VERSION "created by canmatrix"

NS_ :

BS_:

BU_: IPD

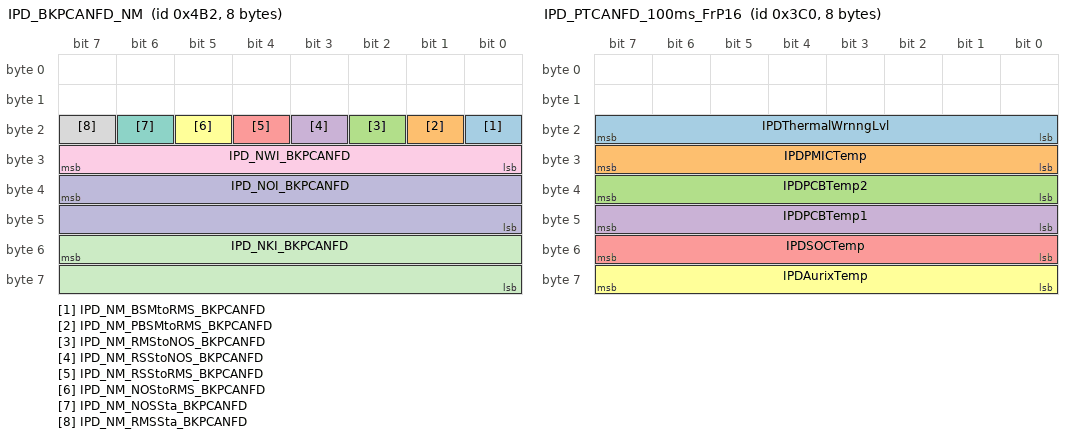
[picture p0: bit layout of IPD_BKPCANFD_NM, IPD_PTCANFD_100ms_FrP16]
BO_ 1202 IPD_BKPCANFD_NM: 8 IPD
 SG_ IPD_NM_BSMtoRMS_BKPCANFD : 16|1@0+ (1,0) [0|1] "null" Vector__XXX
 SG_ IPD_NM_PBSMtoRMS_BKPCANFD : 17|1@0+ (1,0) [0|1] "null" Vector__XXX
 SG_ IPD_NM_RMStoNOS_BKPCANFD : 18|1@0+ (1,0) [0|1] "null" Vector__XXX
 SG_ IPD_NM_RSStoNOS_BKPCANFD : 19|1@0+ (1,0) [0|1] "null" Vector__XXX
 SG_ IPD_NM_RSStoRMS_BKPCANFD : 20|1@0+ (1,0) [0|1] "null" Vector__XXX
 SG_ IPD_NM_NOStoRMS_BKPCANFD : 21|1@0+ (1,0) [0|1] "null" Vector__XXX
 SG_ IPD_NM_NOSSta_BKPCANFD : 22|1@0+ (1,0) [0|1] "null" Vector__XXX
 SG_ IPD_NM_RMSSta_BKPCANFD : 23|1@0+ (1,0) [0|1] "null" Vector__XXX
 SG_ IPD_NWI_BKPCANFD : 31|8@0+ (1,0) [0|255] "null" Vector__XXX
 SG_ IPD_NOI_BKPCANFD : 39|16@0+ (1,0) [0|65535] "null" Vector__XXX
 SG_ IPD_NKI_BKPCANFD : 55|16@0+ (1,0) [0|65535] "null" Vector__XXX

BO_ 705 IPD_CHCANFD_100ms_FrP130: 16 IPD
 SG_ RASysSts : 19|3@0+ (1,0) [0|7] "null" Vector__XXX
 SG_ HWPEMStsForEdr : 124|3@0+ (1,0) [0|7] "null" Vector__XXX
 SG_ HWPEMSts : 127|3@0+ (1,0) [0|7] "null" Vector__XXX

BO_ 982 IPD_PTCANFD_100ms_FrP03: 20 IPD
 SG_ ACCDetObjLongtRltvDist : 7|12@0+ (0.0625,0) [0.0000|255.9375] "null" Vector__XXX
 SG_ ACCDetObjSyncCtr : 11|4@0+ (1,0) [0|15] "null" Vector__XXX
 SG_ ACCDetObjLongtRltvSpd : 23|12@0+ (0.0625,-128) [-128.0000|127.9375] "null" Vector__XXX
 SG_ ACCDetObjRisk : 24|1@0+ (1,0) [0|1] "null" Vector__XXX
 SG_ ACCDetObjTyp : 27|3@0+ (1,0) [0|7] "null" Vector__XXX
 SG_ ACCDetObjLatRltvDist : 33|15@0+ (0.0078,-128) [-128.0000|127.5826] "null" Vector__XXX
 SG_ ACCDetObjExistPrblty : 39|6@0+ (0.015625,0) [0.000000|0.984375] "null" Vector__XXX
 SG_ ACCDetObjId : 50|6@0+ (1,0) [0|63] "null" Vector__XXX

BO_ 960 IPD_PTCANFD_100ms_FrP16: 8 IPD
 SG_ IPDThermalWrnngLvl : 23|8@0+ (1,0) [0|255] "null" Vector__XXX
 SG_ IPDPMICTemp : 31|8@0+ (1,-40) [-40|215] "degreeCelsius" Vector__XXX
 SG_ IPDPCBTemp2 : 39|8@0+ (1,-40) [-40|215] "degreeCelsius" Vector__XXX
 SG_ IPDPCBTemp1 : 47|8@0+ (1,-40) [-40|215] "degreeCelsius" Vector__XXX
 SG_ IPDSOCTemp : 55|8@0+ (1,-40) [-40|215] "degreeCelsius" Vector__XXX
 SG_ IPDAurixTemp : 63|8@0+ (1,-40) [-40|215] "degreeCelsius" Vector__XXX

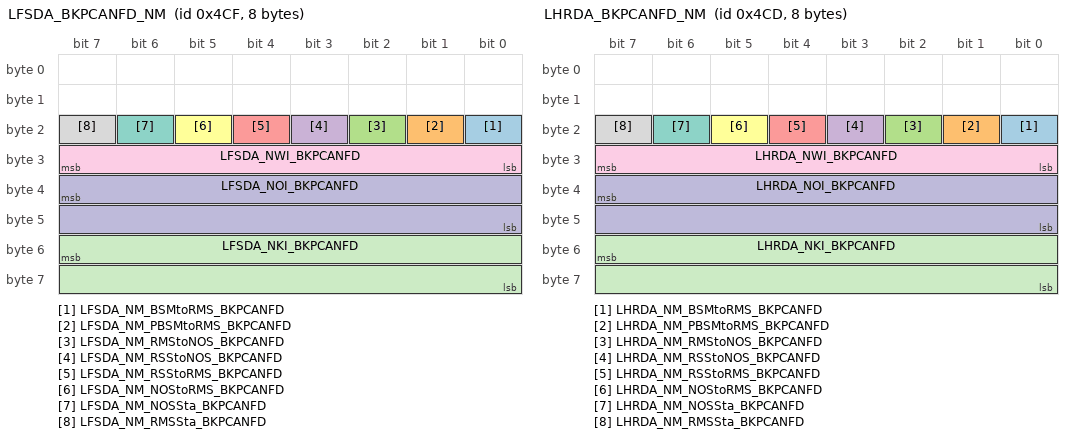
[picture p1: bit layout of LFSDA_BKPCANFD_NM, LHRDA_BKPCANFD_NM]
BO_ 1231 LFSDA_BKPCANFD_NM: 8 Vector__XXX
 SG_ LFSDA_NM_BSMtoRMS_BKPCANFD : 16|1@0+ (1,0) [0|1] "null" Vector__XXX
 SG_ LFSDA_NM_PBSMtoRMS_BKPCANFD : 17|1@0+ (1,0) [0|1] "null" Vector__XXX
 SG_ LFSDA_NM_RMStoNOS_BKPCANFD : 18|1@0+ (1,0) [0|1] "null" Vector__XXX
 SG_ LFSDA_NM_RSStoNOS_BKPCANFD : 19|1@0+ (1,0) [0|1] "null" Vector__XXX
 SG_ LFSDA_NM_RSStoRMS_BKPCANFD : 20|1@0+ (1,0) [0|1] "null" Vector__XXX
 SG_ LFSDA_NM_NOStoRMS_BKPCANFD : 21|1@0+ (1,0) [0|1] "null" Vector__XXX
 SG_ LFSDA_NM_NOSSta_BKPCANFD : 22|1@0+ (1,0) [0|1] "null" Vector__XXX
 SG_ LFSDA_NM_RMSSta_BKPCANFD : 23|1@0+ (1,0) [0|1] "null" Vector__XXX
 SG_ LFSDA_NWI_BKPCANFD : 31|8@0+ (1,0) [0|255] "null" Vector__XXX
 SG_ LFSDA_NOI_BKPCANFD : 39|16@0+ (1,0) [0|65535] "null" Vector__XXX
 SG_ LFSDA_NKI_BKPCANFD : 55|16@0+ (1,0) [0|65535] "null" Vector__XXX

BO_ 1229 LHRDA_BKPCANFD_NM: 8 Vector__XXX
 SG_ LHRDA_NM_BSMtoRMS_BKPCANFD : 16|1@0+ (1,0) [0|1] "null" Vector__XXX
 SG_ LHRDA_NM_PBSMtoRMS_BKPCANFD : 17|1@0+ (1,0) [0|1] "null" Vector__XXX
 SG_ LHRDA_NM_RMStoNOS_BKPCANFD : 18|1@0+ (1,0) [0|1] "null" Vector__XXX
 SG_ LHRDA_NM_RSStoNOS_BKPCANFD : 19|1@0+ (1,0) [0|1] "null" Vector__XXX
 SG_ LHRDA_NM_RSStoRMS_BKPCANFD : 20|1@0+ (1,0) [0|1] "null" Vector__XXX
 SG_ LHRDA_NM_NOStoRMS_BKPCANFD : 21|1@0+ (1,0) [0|1] "null" Vector__XXX
 SG_ LHRDA_NM_NOSSta_BKPCANFD : 22|1@0+ (1,0) [0|1] "null" Vector__XXX
 SG_ LHRDA_NM_RMSSta_BKPCANFD : 23|1@0+ (1,0) [0|1] "null" Vector__XXX
 SG_ LHRDA_NWI_BKPCANFD : 31|8@0+ (1,0) [0|255] "null" Vector__XXX
 SG_ LHRDA_NOI_BKPCANFD : 39|16@0+ (1,0) [0|65535] "null" Vector__XXX
 SG_ LHRDA_NKI_BKPCANFD : 55|16@0+ (1,0) [0|65535] "null" Vector__XXX

BO_ 995 LHZCU_BKBCANFD_100ms_FrP30: 16 Vector__XXX
 SG_ LHZCU_100ms_Group30_CRC : 7|8@0+ (1,0) [0|255] "null" IPD
 SG_ LHZCU_100ms_Group30_RC : 11|4@0+ (1,0) [0|15] "null" IPD
 SG_ LHZCU_100ms_Group30_Reserved12 : 12|1@0+ (1,0) [0|1] "null" IPD
 SG_ DircnIndLampSwStsMntry : 15|3@0+ (1,0) [0|7] "null" IPD
 SG_ LHZCU_100ms_Group30_Reserved23 : 23|8@0+ (1,0) [0|255] "null" IPD
 SG_ LHZCU_100ms_Group30_Reserved31 : 31|8@0+ (1,0) [0|255] "null" IPD
 SG_ FLSeatHorzPos : 39|8@0+ (1,0) [0|255] "%" IPD
 SG_ FLSeatVertPos : 47|8@0+ (1,0) [0|255] "%" IPD
 SG_ LHZCU_100ms_Group30_Reserved55 : 55|8@0+ (1,0) [0|255] "null" IPD
 SG_ LHZCU_100ms_Group30_Reserved63 : 63|8@0+ (1,0) [0|255] "null" IPD
 SG_ LHZCU_100ms_Group30_Reserved71 : 71|8@0+ (1,0) [0|255] "null" IPD
 SG_ LHZCU_100ms_Group30_Reserved79 : 79|8@0+ (1,0) [0|255] "null" IPD
 SG_ LHZCU_100ms_Group30_Reserved87 : 87|8@0+ (1,0) [0|255] "null" IPD
 SG_ LHZCU_100ms_Group30_Reserved95 : 95|8@0+ (1,0) [0|255] "null" IPD
 SG_ LHZCU_100ms_Group30_Reserved103 : 103|8@0+ (1,0) [0|255] "null" IPD
 SG_ LHZCU_100ms_Group30_Reserved111 : 111|8@0+ (1,0) [0|255] "null" IPD
 SG_ LHZCU_100ms_Group30_Reserved119 : 119|8@0+ (1,0) [0|255] "null" IPD
 SG_ LHZCU_100ms_Group30_Reserved127 : 127|8@0+ (1,0) [0|255] "null" IPD

BO_ 181 LHZCU_BKBCANFD_10ms_FrP32: 12 Vector__XXX
 SG_ LHZCU_10ms_Group32_CRC : 7|8@0+ (1,0) [0|255] "null" IPD
 SG_ LHZCU_10ms_Group32_RC : 11|4@0+ (1,0) [0|15] "null" IPD
 SG_ LHZCU_10ms_Group32_Reserved1 : 15|4@0+ (1,0) [0|15] "null" IPD
 SG_ BrkLghtSwReq : 16|1@0+ (1,0) [0|1] "null" IPD
 SG_ SideLghtOnReq : 18|2@0+ (1,0) [0|3] "null" IPD
 SG_ MainBeamLghtSwReq : 20|2@0+ (1,0) [0|3] "null" IPD
 SG_ LHZCU_10ms_Group32_Reserved2 : 23|3@0+ (1,0) [0|7] "null" IPD
 SG_ DrvrReqGearShftPos : 27|4@0+ (1,0) [0|15] "null" IPD
 SG_ LHZCU_10ms_Group32_Reserved3 : 28|1@0+ (1,0) [0|1] "null" IPD
 SG_ RrFogLightOnReq : 29|1@0+ (1,0) [0|1] "null" IPD
 SG_ RDayTimeRunningLghtCtrl : 30|1@0+ (1,0) [0|1] "null" IPD
 SG_ LDayTimeRunningLghtCtrl : 31|1@0+ (1,0) [0|1] "null" IPD
 SG_ EleccTrRngReq : 35|4@0+ (1,0) [0|15] "null" IPD
 SG_ DrvrReqGearShftPosInvs : 39|4@0+ (1,0) [0|15] "null" IPD
 SG_ DircnLghtOnReq_LHZCU : 41|2@0+ (1,0) [0|3] "null" IPD
 SG_ SCUDrvnIntrvnPos : 45|4@0+ (1,0) [0|15] "null" IPD
 SG_ LHZCU_10ms_Group32_Reserved4 : 46|1@0+ (1,0) [0|1] "null" IPD
 SG_ SCUShftLvrPosIncnstntFlag : 47|1@0+ (1,0) [0|1] "null" IPD
 SG_ SCUShftLvrPosTrgt : 51|4@0+ (1,0) [0|15] "null" IPD
 SG_ SCUExtdShifterActrPos : 55|4@0+ (1,0) [0|15] "null" IPD
 SG_ SCUTapUpDwnSwStaInvsn : 57|2@0+ (1,0) [0|3] "null" IPD
 SG_ SCUTapUpDwnSwSta : 59|2@0+ (1,0) [0|3] "null" IPD
 SG_ SCUParkActrSts : 61|2@0+ (1,0) [0|3] "null" IPD
 SG_ SCUActrMvmntSts : 63|2@0+ (1,0) [0|3] "null" IPD
 SG_ SmrtKey4LoctnResp : 67|4@0+ (1,0) [0|15] "null" IPD
 SG_ SmrtKeyLoctnProc : 71|4@0+ (1,0) [0|15] "null" IPD
 SG_ LHZCU_10ms_Group32_Reserved5 : 74|3@0+ (1,0) [0|7] "null" IPD
 SG_ LHZCUWKSTS : 75|1@0+ (1,0) [0|1] "null" IPD
 SG_ SmrtKeyLoctnFlrRsn : 79|4@0+ (1,0) [0|15] "null" IPD
 SG_ LHZCU_10ms_Group32_Reserved6 : 87|8@0+ (1,0) [0|255] "null" IPD
 SG_ LHZCU_10ms_Group32_Reserved7 : 95|8@0+ (1,0) [0|255] "null" IPD

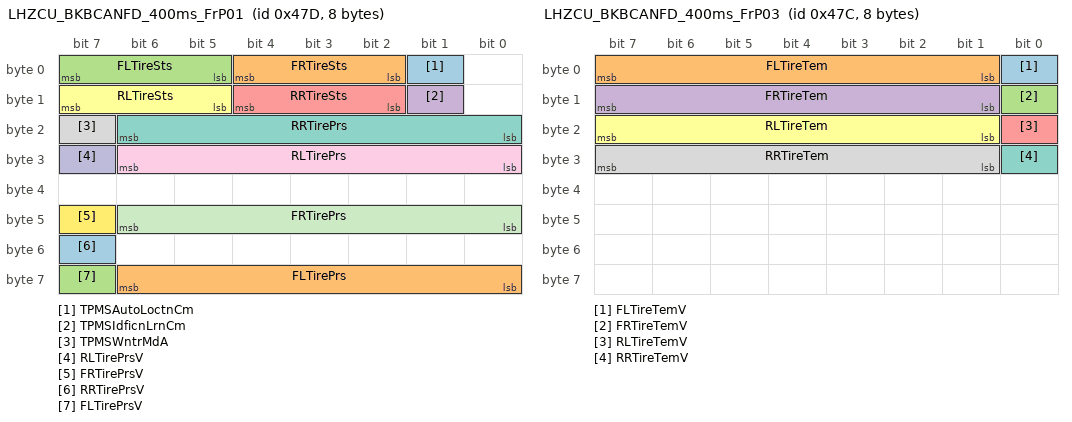
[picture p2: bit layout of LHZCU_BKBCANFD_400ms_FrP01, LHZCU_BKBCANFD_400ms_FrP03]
BO_ 1149 LHZCU_BKBCANFD_400ms_FrP01: 8 Vector__XXX
 SG_ TPMSAutoLoctnCm : 1|1@0+ (1,0) [0|1] "null" Vector__XXX
 SG_ FRTireSts : 4|3@0+ (1,0) [0|7] "null" IPD
 SG_ FLTireSts : 7|3@0+ (1,0) [0|7] "null" IPD
 SG_ TPMSIdficnLrnCm : 9|1@0+ (1,0) [0|1] "null" Vector__XXX
 SG_ RRTireSts : 12|3@0+ (1,0) [0|7] "null" IPD
 SG_ RLTireSts : 15|3@0+ (1,0) [0|7] "null" IPD
 SG_ RRTirePrs : 22|7@0+ (4,0) [0|508] "kPa" IPD
 SG_ TPMSWntrMdA : 23|1@0+ (1,0) [0|1] "null" IPD
 SG_ RLTirePrs : 30|7@0+ (4,0) [0|508] "kPa" IPD
 SG_ RLTirePrsV : 31|1@0+ (1,0) [0|1] "null" IPD
 SG_ FRTirePrs : 46|7@0+ (4,0) [0|508] "kPa" IPD
 SG_ FRTirePrsV : 47|1@0+ (1,0) [0|1] "null" IPD
 SG_ RRTirePrsV : 55|1@0+ (1,0) [0|1] "null" IPD
 SG_ FLTirePrs : 62|7@0+ (4,0) [0|508] "kPa" IPD
 SG_ FLTirePrsV : 63|1@0+ (1,0) [0|1] "null" IPD

BO_ 1148 LHZCU_BKBCANFD_400ms_FrP03: 8 Vector__XXX
 SG_ FLTireTemV : 0|1@0+ (1,0) [0|1] "null" IPD
 SG_ FLTireTem : 7|7@0+ (2,-60) [-60|194] "degreeCelsius" IPD
 SG_ FRTireTemV : 8|1@0+ (1,0) [0|1] "null" IPD
 SG_ FRTireTem : 15|7@0+ (2,-60) [-60|194] "degreeCelsius" IPD
 SG_ RLTireTemV : 16|1@0+ (1,0) [0|1] "null" IPD
 SG_ RLTireTem : 23|7@0+ (2,-60) [-60|194] "degreeCelsius" IPD
 SG_ RRTireTemV : 24|1@0+ (1,0) [0|1] "null" IPD
 SG_ RRTireTem : 31|7@0+ (2,-60) [-60|194] "degreeCelsius" IPD

BO_ 638 LHZCU_BKBCANFD_50ms_FrP24: 20 Vector__XXX
 SG_ LHZCU_50ms_Group24_CRC : 7|8@0+ (1,0) [0|255] "null" IPD
 SG_ LHZCU_50ms_Group24_RC : 11|4@0+ (1,0) [0|15] "null" IPD
 SG_ VehHzrdMdSts : 15|4@0+ (1,0) [0|15] "null" IPD
 SG_ LHZCU_50ms_Group24_Reserved23 : 23|8@0+ (1,0) [0|255] "null" IPD
 SG_ VehIlluminateCtrlCmd : 24|1@0+ (1,0) [0|1] "null" IPD
 SG_ LHZCU_50ms_Group24_Reserved31 : 31|7@0+ (1,0) [0|127] "null" IPD
 SG_ BrkLghtSta : 32|1@0+ (1,0) [0|1] "null" IPD
 SG_ LHZCU_50ms_Group24_Reserved39 : 39|7@0+ (1,0) [0|127] "null" IPD
 SG_ BrkLghtFltSta : 40|1@0+ (1,0) [0|1] "null" IPD
 SG_ LHZCU_50ms_Group24_Reserved47 : 47|7@0+ (1,0) [0|127] "null" IPD
 SG_ LHZCU_50ms_Group24_Reserved49 : 49|3@0+ (1,0) [0|7] "null" IPD
 SG_ DircnLghtSts : 52|3@0+ (1,0) [0|7] "null" IPD
 SG_ DircnLghtMdSts : 53|1@0+ (1,0) [0|1] "null" IPD
 SG_ LHZCU_50ms_Group24_Reserved55 : 55|2@0+ (1,0) [0|3] "null" IPD
 SG_ LHZCU_50ms_Group24_Reserved60 : 60|5@0+ (1,0) [0|31] "null" IPD
 SG_ RRSideLghtCtrl : 61|1@0+ (1,0) [0|1] "null" IPD
 SG_ RLSideLghtCtrl : 62|1@0+ (1,0) [0|1] "null" IPD
 SG_ LHZCU_50ms_Group24_Reserved71 : 71|8@0+ (1,0) [0|255] "null" IPD
 SG_ VehSideLghtSts : 73|2@0+ (1,0) [0|3] "null" IPD
 SG_ LHZCU_50ms_Group24_Reserved79 : 79|6@0+ (1,0) [0|63] "null" IPD
 SG_ LHZCU_50ms_Group24_Reserved81 : 81|2@0+ (1,0) [0|3] "null" IPD
 SG_ DircnLghtSwReq : 84|3@0+ (1,0) [0|7] "null" IPD
 SG_ LHZCU_50ms_Group24_Reserved87 : 87|3@0+ (1,0) [0|7] "null" IPD
 SG_ LHZCU_50ms_Group24_Reserved95 : 95|8@0+ (1,0) [0|255] "null" IPD
 SG_ LHZCU_50ms_Group24_Reserved103 : 103|8@0+ (1,0) [0|255] "null" IPD
 SG_ DircnLghtFltsts : 105|2@0+ (1,0) [0|3] "null" IPD
 SG_ LHZCU_50ms_Group24_Reserved111 : 111|6@0+ (1,0) [0|63] "null" IPD
 SG_ HUDLkngAmbtLghtLvlByLux : 119|14@0+ (10,0) [0|163830] "lux" IPD
 SG_ LHZCU_50ms_Group24_Reserved121 : 121|2@0+ (1,0) [0|3] "null" IPD
 SG_ LHZCU_50ms_Group24_Reserved135 : 135|8@0+ (1,0) [0|255] "null" IPD
 SG_ LHZCU_50ms_Group24_Reserved143 : 143|8@0+ (1,0) [0|255] "null" IPD
 SG_ LHZCU_50ms_Group24_Reserved151 : 151|8@0+ (1,0) [0|255] "null" IPD
 SG_ LHZCU_50ms_Group24_Reserved159 : 159|8@0+ (1,0) [0|255] "null" IPD

BO_ 745 LHZCU_BKBCANFD_50ms_FrP34: 16 Vector__XXX
 SG_ AutoMainBeamLghtOn : 12|1@0+ (1,0) [0|1] "null" IPD
 SG_ MainBeamLghtOn : 13|1@0+ (1,0) [0|1] "null" IPD
 SG_ LRevsLghtSts : 14|1@0+ (1,0) [0|1] "null" Vector__XXX
 SG_ LBrkLghtSts : 15|1@0+ (1,0) [0|1] "null" Vector__XXX
 SG_ ROtsdMirVertSwActReq : 17|2@0+ (1,0) [0|3] "null" Vector__XXX
 SG_ ROtsdMirHoztSwActReq : 19|2@0+ (1,0) [0|3] "null" Vector__XXX
 SG_ RLDoorLckSts : 21|2@0+ (1,0) [0|3] "null" Vector__XXX
 SG_ ZoneRLSideLghtSts : 27|2@0+ (1,0) [0|3] "null" Vector__XXX
 SG_ ZoneFLSideLghtSts : 29|2@0+ (1,0) [0|3] "null" Vector__XXX
 SG_ AllWndAndSrfLazyClsReq : 45|1@0+ (1,0) [0|1] "null" Vector__XXX
 SG_ RrSrvcPosReq : 46|1@0+ (1,0) [0|1] "null" Vector__XXX
 SG_ RrWiperFnEnb : 47|1@0+ (1,0) [0|1] "null" Vector__XXX
 SG_ DDSPSelRSwReq : 50|2@0+ (1,0) [0|3] "null" Vector__XXX
 SG_ DDSPSelLSwReq : 52|2@0+ (1,0) [0|3] "null" Vector__XXX
 SG_ TrdtnSmrtKyLckSwSts : 65|2@0+ (1,0) [0|3] "null" IPD
 SG_ TrdtnSmrtKyUnlckSwSts : 67|2@0+ (1,0) [0|3] "null" IPD
 SG_ RLSuperLckSts : 69|2@0+ (1,0) [0|3] "null" Vector__XXX
 SG_ FLSuperLckSts : 71|2@0+ (1,0) [0|3] "null" Vector__XXX
 SG_ DDSPSelDwnSwReq : 73|2@0+ (1,0) [0|3] "null" Vector__XXX
 SG_ DDSPSelUpSwReq : 75|2@0+ (1,0) [0|3] "null" Vector__XXX
 SG_ DDSPROtsdMirSeldSwA : 77|2@0+ (1,0) [0|3] "null" Vector__XXX
 SG_ DDSPLOtsdMirSeldSwA : 79|2@0+ (1,0) [0|3] "null" Vector__XXX
 SG_ DDSPOtsdMirFoldSwReq : 87|2@0+ (1,0) [0|3] "null" Vector__XXX

BO_ 640 LHZCU_BKBCANFD_50ms_FrP58: 24 Vector__XXX
 SG_ TrdtnKeyBtnSts : 15|4@0+ (1,0) [0|15] "null" IPD
 SG_ SmrtKey1BtnSts : 23|8@0+ (1,0) [0|255] "null" Vector__XXX
 SG_ SmrtKey2BtnSts : 31|8@0+ (1,0) [0|255] "null" Vector__XXX
 SG_ SmrtKey3BtnSts : 39|8@0+ (1,0) [0|255] "null" Vector__XXX
 SG_ SmrtKey4BtnSts : 47|8@0+ (1,0) [0|255] "null" Vector__XXX
 SG_ SmrtKey2LoctnResp : 51|4@0+ (1,0) [0|15] "null" Vector__XXX
 SG_ SmrtKey1LoctnResp : 55|4@0+ (1,0) [0|15] "null" Vector__XXX
 SG_ LHandAntFltSts : 59|4@0+ (1,0) [0|15] "null" Vector__XXX
 SG_ SmrtKey3LoctnResp : 63|4@0+ (1,0) [0|15] "null" Vector__XXX
 SG_ FrtBmpAntFltSts : 67|4@0+ (1,0) [0|15] "null" Vector__XXX
 SG_ RHandAntFltSts : 71|4@0+ (1,0) [0|15] "null" Vector__XXX
 SG_ CabinFrtAntFltSts : 75|4@0+ (1,0) [0|15] "null" Vector__XXX
 SG_ RrBmpAntFltSts : 79|4@0+ (1,0) [0|15] "null" Vector__XXX
 SG_ CabinRrAntFltSts : 83|4@0+ (1,0) [0|15] "null" Vector__XXX
 SG_ CabinImmoAntFltSts : 87|4@0+ (1,0) [0|15] "null" Vector__XXX
 SG_ KickSnsrDetnSts : 91|2@0+ (1,0) [0|3] "null" Vector__XXX
 SG_ TrdtnSmrtKyLdspcSwSts : 93|2@0+ (1,0) [0|3] "null" IPD
 SG_ TrdtnSmrtKyFindCarSwSts : 95|2@0+ (1,0) [0|3] "null" IPD

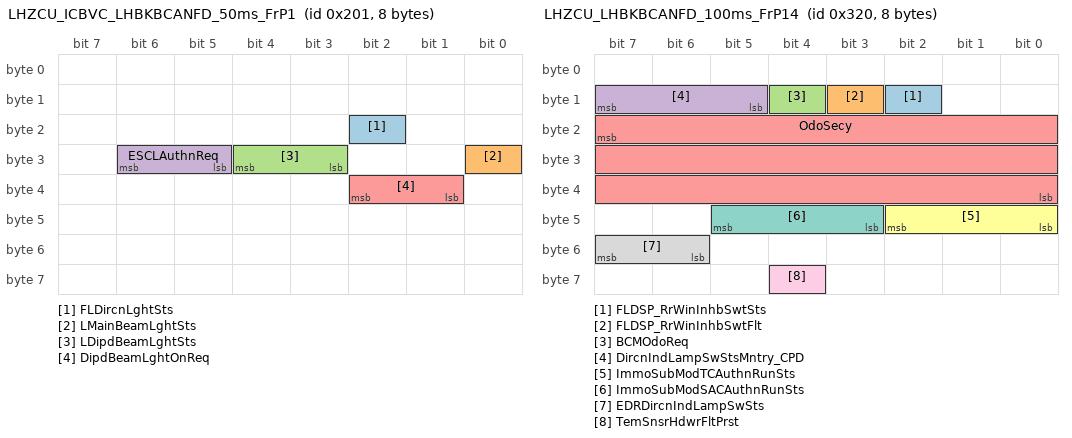
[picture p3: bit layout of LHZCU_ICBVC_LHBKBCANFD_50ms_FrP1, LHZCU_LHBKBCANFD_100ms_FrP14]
BO_ 513 LHZCU_ICBVC_LHBKBCANFD_50ms_FrP1: 8 Vector__XXX
 SG_ FLDircnLghtSts : 18|1@0+ (1,0) [0|1] "null" IPD
 SG_ LMainBeamLghtSts : 24|1@0+ (1,0) [0|1] "null" Vector__XXX
 SG_ LDipdBeamLghtSts : 28|2@0+ (1,0) [0|3] "null" Vector__XXX
 SG_ ESCLAuthnReq : 30|2@0+ (1,0) [0|3] "null" Vector__XXX
 SG_ DipdBeamLghtOnReq : 34|2@0+ (1,0) [0|3] "null" Vector__XXX

BO_ 800 LHZCU_LHBKBCANFD_100ms_FrP14: 8 Vector__XXX
 SG_ FLDSP_RrWinInhbSwtSts : 10|1@0+ (1,0) [0|1] "null" Vector__XXX
 SG_ FLDSP_RrWinInhbSwtFlt : 11|1@0+ (1,0) [0|1] "null" Vector__XXX
 SG_ BCMOdoReq : 12|1@0+ (1,0) [0|1] "null" Vector__XXX
 SG_ DircnIndLampSwStsMntry_CPD : 15|3@0+ (1,0) [0|7] "null" Vector__XXX
 SG_ OdoSecy : 23|24@0+ (1,0) [0|16777215] "km" Vector__XXX
 SG_ ImmoSubModTCAuthnRunSts : 42|3@0+ (1,0) [0|7] "null" Vector__XXX
 SG_ ImmoSubModSACAuthnRunSts : 45|3@0+ (1,0) [0|7] "null" Vector__XXX
 SG_ EDRDircnIndLampSwSts : 55|2@0+ (1,0) [0|3] "null" Vector__XXX
 SG_ TemSnsrHdwrFltPrst : 60|1@0+ (1,0) [0|1] "null" IPD

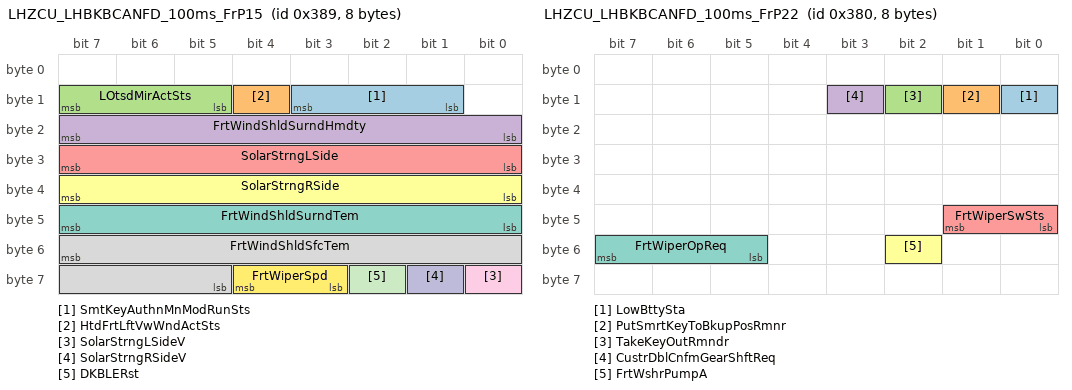
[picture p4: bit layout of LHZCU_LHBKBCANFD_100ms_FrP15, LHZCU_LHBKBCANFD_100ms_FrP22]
BO_ 905 LHZCU_LHBKBCANFD_100ms_FrP15: 8 Vector__XXX
 SG_ SmtKeyAuthnMnModRunSts : 11|3@0+ (1,0) [0|7] "null" Vector__XXX
 SG_ HtdFrtLftVwWndActSts : 12|1@0+ (1,0) [0|1] "null" Vector__XXX
 SG_ LOtsdMirActSts : 15|3@0+ (1,0) [0|7] "null" Vector__XXX
 SG_ FrtWindShldSurndHmdty : 23|8@0+ (0.5,0) [0|127.5] "%" IPD
 SG_ SolarStrngLSide : 31|8@0+ (5,0) [0|1275] "null" Vector__XXX
 SG_ SolarStrngRSide : 39|8@0+ (5,0) [0|1275] "null" Vector__XXX
 SG_ FrtWindShldSurndTem : 47|8@0+ (0.5,-40) [-40|87.5] "degC" IPD
 SG_ FrtWindShldSfcTem : 55|11@0+ (0.1,-40) [-40|164.7] "degC" IPD
 SG_ SolarStrngLSideV : 56|1@0+ (1,0) [0|1] "null" Vector__XXX
 SG_ SolarStrngRSideV : 57|1@0+ (1,0) [0|1] "null" Vector__XXX
 SG_ DKBLERst : 58|1@0+ (1,0) [0|1] "null" Vector__XXX
 SG_ FrtWiperSpd : 60|2@0+ (1,0) [0|3] "null" IPD

BO_ 783 LHZCU_LHBKBCANFD_100ms_FrP16: 64 Vector__XXX
 SG_ LHZCUeFs12Crnt : 7|9@0+ (0.1,0) [0|51.1] "A" Vector__XXX
 SG_ LHZCUeSw40Crnt : 14|9@0+ (0.1,0) [0|51.1] "A" Vector__XXX
 SG_ WlcmReq : 19|2@0+ (1,0) [0|3] "null" Vector__XXX
 SG_ FllwMeReq : 21|2@0+ (1,0) [0|3] "null" Vector__XXX
 SG_ LHZCUInptVol : 47|8@0+ (0.1,0) [0|25.5] "V" Vector__XXX
 SG_ LHZCUeFs8Crnt : 55|9@0+ (0.1,0) [0|51.1] "A" Vector__XXX
 SG_ LHZCUeSw24Crnt : 56|9@0+ (0.1,0) [0|51.1] "A" Vector__XXX
 SG_ LHZCUeSw17Crnt : 76|9@0+ (0.1,0) [0|51.1] "A" Vector__XXX
 SG_ LHZCUeSw16Crnt : 83|9@0+ (0.1,0) [0|51.1] "A" Vector__XXX
 SG_ LHZCUeSw15Crnt : 90|9@0+ (0.1,0) [0|51.1] "A" Vector__XXX
 SG_ LHZCUeSw14Crnt : 97|9@0+ (0.1,0) [0|51.1] "A" Vector__XXX
 SG_ LHZCUeSw13Crnt : 104|9@0+ (0.1,0) [0|51.1] "A" Vector__XXX
 SG_ LHZCUeSw12Crnt : 127|9@0+ (0.1,0) [0|51.1] "A" Vector__XXX
 SG_ LHZCUeSw26Crnt : 128|9@0+ (0.1,0) [0|51.1] "A" Vector__XXX
 SG_ LHZCUeFs6Crnt : 148|9@0+ (0.1,0) [0|51.1] "A" Vector__XXX
 SG_ LHZCUeSw32Crnt : 155|9@0+ (0.1,0) [0|51.1] "A" Vector__XXX
 SG_ LHZCUeFs4Crnt : 162|9@0+ (0.1,0) [0|51.1] "A" Vector__XXX
 SG_ LHZCUeSw27Crnt : 168|9@0+ (0.1,0) [0|51.1] "A" Vector__XXX
 SG_ LHZCUBkupInptVol : 191|8@0+ (0.1,0) [0|25.5] "V" Vector__XXX
 SG_ LHZCUeSw1Crnt : 199|9@0+ (0.1,0) [0|51.1] "A" Vector__XXX
 SG_ LHZCUeSw20Crnt : 206|9@0+ (0.1,0) [0|51.1] "A" Vector__XXX
 SG_ LHZCUeSw3Crnt : 213|9@0+ (0.1,0) [0|51.1] "A" Vector__XXX
 SG_ LHZCUeSw29Crnt : 216|9@0+ (0.1,0) [0|51.1] "A" Vector__XXX
 SG_ LHZCUeSw36Crnt : 239|9@0+ (0.1,0) [0|51.1] "A" Vector__XXX
 SG_ LHZCUeFs13Crnt : 240|9@0+ (0.1,0) [0|51.1] "A" Vector__XXX
 SG_ LHZCUeSw30Crnt : 263|9@0+ (0.1,0) [0|51.1] "A" Vector__XXX
 SG_ LHZCUeSw31Crnt : 264|9@0+ (0.1,0) [0|51.1] "A" Vector__XXX
 SG_ FrwlLghtReq_LHZCU : 267|1@0+ (1,0) [0|1] "null" Vector__XXX
 SG_ LHZCUeSw43Crnt : 287|9@0+ (0.1,0) [0|51.1] "A" Vector__XXX
 SG_ LHZCUAddtnInptVol : 303|8@0+ (0.1,0) [0|25.5] "V" Vector__XXX
 SG_ LHZCUeSw44Crnt : 311|9@0+ (0.1,0) [0|51.1] "A" Vector__XXX
 SG_ LHZCUeSw45Crnt : 318|9@0+ (0.1,0) [0|51.1] "A" Vector__XXX
 SG_ FLSeatZeroSt : 321|2@0+ (1,0) [0|3] "null" Vector__XXX
 SG_ LHZCUeSw46Crnt : 335|9@0+ (0.1,0) [0|51.1] "A" Vector__XXX
 SG_ LHZCUeSw47Crnt : 336|9@0+ (0.1,0) [0|51.1] "A" Vector__XXX
 SG_ WlcmLghtReq_LHZCU : 338|1@0+ (1,0) [0|1] "null" Vector__XXX
 SG_ FLDoorOpenSts : 341|2@0+ (1,0) [0|3] "null" IPD
 SG_ HUDLghtSnsrHdwrFltPrst : 342|1@0+ (1,0) [0|1] "null" Vector__XXX
 SG_ FLSeatRclnMotActn : 362|2@0+ (1,0) [0|3] "null" Vector__XXX
 SG_ FLSeatVertMotActn : 364|2@0+ (1,0) [0|3] "null" Vector__XXX
 SG_ FLSeatHoztMotActn : 366|2@0+ (1,0) [0|3] "null" Vector__XXX
 SG_ HUDFwdLkngAmbtLghtLvl : 383|14@0+ (10,0) [0|163830] "LUX" Vector__XXX
 SG_ FollowMeHomeReq_LHZCU : 384|1@0+ (1,0) [0|1] "null" Vector__XXX
 SG_ BklghtReq : 385|1@0+ (1,0) [0|1] "null" Vector__XXX
 SG_ HUDRLSAmbtLghtLvl : 399|12@0+ (10,0) [0|40950] "LUX" Vector__XXX
 SG_ LHZCUeFs15Crnt : 400|9@0+ (0.1,0) [0|51.1] "A" Vector__XXX
 SG_ HmdtySnsrHdwrFltPrst : 401|1@0+ (1,0) [0|1] "null" IPD
 SG_ FrtPsngDoorOpenSts_LHZCU : 403|2@0+ (1,0) [0|3] "null" IPD
 SG_ LHZCUeFs17Crnt : 423|9@0+ (0.1,0) [0|51.1] "A" Vector__XXX

BO_ 896 LHZCU_LHBKBCANFD_100ms_FrP22: 8 Vector__XXX
 SG_ LowBttySta : 8|1@0+ (1,0) [0|1] "null" Vector__XXX
 SG_ PutSmrtKeyToBkupPosRmnr : 9|1@0+ (1,0) [0|1] "null" Vector__XXX
 SG_ TakeKeyOutRmndr : 10|1@0+ (1,0) [0|1] "null" Vector__XXX
 SG_ CustrDblCnfmGearShftReq : 11|1@0+ (1,0) [0|1] "null" Vector__XXX
 SG_ FrtWiperSwSts : 41|2@0+ (1,0) [0|3] "null" IPD
 SG_ FrtWshrPumpA : 50|1@0+ (1,0) [0|1] "null" Vector__XXX
 SG_ FrtWiperOpReq : 55|3@0+ (1,0) [0|7] "null" Vector__XXX

BO_ 157 LHZCU_LHBKBCANFD_10ms_FrP01: 8 Vector__XXX
 SG_ LHZCU_10ms_Group01_CRC : 7|8@0+ (1,0) [0|255] "null" IPD
 SG_ LHZCU_10ms_Group01_RC : 11|4@0+ (1,0) [0|15] "null" IPD
 SG_ SCUFltLvlWarn : 13|2@0+ (1,0) [0|3] "null" IPD
 SG_ SCUDrvMd : 15|2@0+ (1,0) [0|3] "null" IPD
 SG_ SCUExtdShiftrFlr : 19|4@0+ (1,0) [0|15] "null" IPD
 SG_ SCUShiftrOpngRmndr : 23|4@0+ (1,0) [0|15] "null" IPD
 SG_ KeyAuthResp : 24|1@0+ (1,0) [0|1] "null" IPD
 SG_ SCUParkLckReq : 26|2@0+ (1,0) [0|3] "null" IPD
 SG_ SCUParkLckReqV : 27|1@0+ (1,0) [0|1] "null" IPD
 SG_ LHZCU_10ms_Group01_Reserved1 : 30|3@0+ (1,0) [0|7] "null" IPD
 SG_ DigKeyAuthReq : 31|1@0+ (1,0) [0|1] "null" IPD
 SG_ SCUShiftrLvrRawPosn : 34|3@0+ (1,0) [0|7] "null" IPD
 SG_ SCUParkLckReqVEPMCU : 35|1@0+ (1,0) [0|1] "null" IPD
 SG_ LHZCU_10ms_Group01_Reserved2 : 37|2@0+ (1,0) [0|3] "null" IPD
 SG_ SCUParkLckReqEPMCU : 39|2@0+ (1,0) [0|3] "null" IPD
 SG_ SCUShiftrPosnInvsn : 43|4@0+ (1,0) [0|15] "null" IPD
 SG_ SCUShiftrLvrPosn : 47|4@0+ (1,0) [0|15] "null" IPD
 SG_ DrvrReqParkBtn : 49|2@0+ (1,0) [0|3] "null" IPD
 SG_ SCUShiftrLvrPosnLtchActv : 50|1@0+ (1,0) [0|1] "null" IPD
 SG_ SecuKeyVldSts : 51|1@0+ (1,0) [0|1] "null" IPD
 SG_ SCUDrvrIntrvnActv : 52|1@0+ (1,0) [0|1] "null" IPD
 SG_ SCUAPAUnderCtrlActv : 55|3@0+ (1,0) [0|7] "null" IPD
 SG_ DigKeyPEValidReq : 63|8@0+ (1,0) [0|255] "null" IPD

BO_ 299 LHZCU_LHBKBCANFD_20ms_FrP03: 8 Vector__XXX
 SG_ LHZCU_20ms_Group03_CRC : 7|8@0+ (1,0) [0|255] "null" IPD
 SG_ LHZCU_20ms_Group03_RC : 11|4@0+ (1,0) [0|15] "null" IPD
 SG_ LHZCU_20ms_Group03_Reserved1 : 15|4@0+ (1,0) [0|15] "null" IPD
 SG_ LHZCU_20ms_Group03_Reserved2 : 23|8@0+ (1,0) [0|255] "null" IPD
 SG_ LHZCU_20ms_Group03_Reserved3 : 31|8@0+ (1,0) [0|255] "null" IPD
 SG_ LHZCU_20ms_Group03_Reserved4 : 39|8@0+ (1,0) [0|255] "null" IPD
 SG_ LHZCU_20ms_Group03_Reserved6 : 41|4@0+ (1,0) [0|15] "null" IPD
 SG_ DippedBeamActStatus : 42|1@0+ (1,0) [0|1] "null" IPD
 SG_ LHZCU_20ms_Group03_Reserved5 : 47|5@0+ (1,0) [0|31] "null" IPD
 SG_ RevsLghtCtrl : 48|1@0+ (1,0) [0|1] "null" IPD
 SG_ PriySSBA : 49|1@0+ (1,0) [0|1] "null" IPD
 SG_ PriySSBAV : 50|1@0+ (1,0) [0|1] "null" IPD
 SG_ SecySSBA : 51|1@0+ (1,0) [0|1] "null" IPD
 SG_ SecySSBAV : 52|1@0+ (1,0) [0|1] "null" IPD
 SG_ SSBTrigd : 53|1@0+ (1,0) [0|1] "null" IPD
 SG_ RMainBeamLghtCtrl : 56|1@0+ (1,0) [0|1] "null" IPD
 SG_ LMainBeamLghtCtrl : 57|1@0+ (1,0) [0|1] "null" IPD
 SG_ RRDircnLghtCtrl : 58|1@0+ (1,0) [0|1] "null" IPD
 SG_ RLDircnLghtCtrl : 59|1@0+ (1,0) [0|1] "null" IPD
 SG_ FRDircnLghtCtrl : 60|1@0+ (1,0) [0|1] "null" IPD
 SG_ FLDircnLghtCtrl : 61|1@0+ (1,0) [0|1] "null" IPD
 SG_ BrkLghtCtrl : 62|1@0+ (1,0) [0|1] "null" IPD
 SG_ HzrdLghtSwReq : 63|1@0+ (1,0) [0|1] "null" IPD

BA_DEF_ BO_ "FrameTriggeringName" STRING;
BA_DEF_ BO_ "GenMsgCycleTime" INT 0 65535;
BA_DEF_ BO_ "GenMsgDelayTime" INT 0 65535;
BA_DEF_ BO_ "GenMsgSendType" ENUM  "cyclicX","spontanX","cyclicIfActiveX","spontanWithDelay","cyclicAndSpontanX","cyclicAndSpontanWithDelay","spontanWithRepitition","cyclicIfActiveAndSpontanWD","cyclicIfActiveFast","cyclicWithRepeatOnDemand","none";
BA_DEF_ BO_ "GenMsgStartValue" STRING;
BA_DEF_ BO_ "PduName" STRING;
BA_DEF_ BO_ "SystemMessageLongSymbol" STRING;
BA_DEF_ BO_ "VFrameFormat" ENUM  "StandardCAN","ExtendedCAN","reserved","reserved","reserved","reserved","reserved","reserved","reserved","reserved","reserved","reserved","reserved","reserved","StandardCAN_FD","ExtendedCAN_FD";
BA_DEF_ SG_ "CompuMethodName" STRING;
BA_DEF_ SG_ "GenSigStartValue" FLOAT 0 100000000000;
BA_DEF_ SG_ "ISignalName" STRING;
BA_DEF_ SG_ "LongName" STRING;
BA_DEF_ SG_ "SysSignalName" STRING;
BA_DEF_ SG_ "SystemSignalLongSymbol" STRING;
BA_ "FrameTriggeringName" BO_ 1202 "IPD_BKPCANFD_NM";
BA_ "GenMsgSendType" BO_ 1202 1;
BA_ "GenMsgStartValue" BO_ 1202 "0000000000000000";
BA_ "PduName" BO_ 1202 "NmPDU_BKPCANFD_IPD";
BA_ "VFrameFormat" BO_ 1202 14;
BA_ "FrameTriggeringName" BO_ 705 "IPD_CHCANFD_100ms_FrP130";
BA_ "GenMsgCycleTime" BO_ 705 100;
BA_ "GenMsgSendType" BO_ 705 0;
BA_ "GenMsgStartValue" BO_ 705 "00000000000000000000000000000000";
BA_ "PduName" BO_ 705 "IPD_100ms_PDU130";
BA_ "VFrameFormat" BO_ 705 14;
BA_ "FrameTriggeringName" BO_ 982 "IPD_PTCANFD_100ms_FrP03";
BA_ "GenMsgCycleTime" BO_ 982 100;
BA_ "GenMsgSendType" BO_ 982 0;
BA_ "GenMsgStartValue" BO_ 982 "0000000000000000000000000000000000000000";
BA_ "PduName" BO_ 982 "IPD_100ms_PDU03";
BA_ "VFrameFormat" BO_ 982 14;
BA_ "FrameTriggeringName" BO_ 960 "IPD_PTCANFD_100ms_FrP16";
BA_ "GenMsgCycleTime" BO_ 960 100;
BA_ "GenMsgSendType" BO_ 960 0;
BA_ "GenMsgStartValue" BO_ 960 "000000ffffffffff";
BA_ "PduName" BO_ 960 "IPD_100ms_PDU16";
BA_ "VFrameFormat" BO_ 960 14;
BA_ "FrameTriggeringName" BO_ 1231 "LFSDA_BKPCANFD_NM";
BA_ "GenMsgSendType" BO_ 1231 1;
BA_ "GenMsgStartValue" BO_ 1231 "0000000000000000";
BA_ "PduName" BO_ 1231 "NmPDU_BKPCANFD_LFSDA";
BA_ "VFrameFormat" BO_ 1231 14;
BA_ "FrameTriggeringName" BO_ 1229 "LHRDA_BKPCANFD_NM";
BA_ "GenMsgSendType" BO_ 1229 1;
BA_ "GenMsgStartValue" BO_ 1229 "0000000000000000";
BA_ "PduName" BO_ 1229 "NmPDU_BKPCANFD_LHRDA";
BA_ "VFrameFormat" BO_ 1229 14;
BA_ "FrameTriggeringName" BO_ 995 "LHZCU_BKBCANFD_100ms_FrP30";
BA_ "GenMsgCycleTime" BO_ 995 100;
BA_ "GenMsgSendType" BO_ 995 0;
BA_ "GenMsgStartValue" BO_ 995 "0010ffffffffffffffffffffffffffff";
BA_ "PduName" BO_ 995 "LHZCU_100ms_PDU30";
BA_ "VFrameFormat" BO_ 995 14;
BA_ "FrameTriggeringName" BO_ 181 "LHZCU_BKBCANFD_10ms_FrP32";
BA_ "GenMsgCycleTime" BO_ 181 10;
BA_ "GenMsgSendType" BO_ 181 0;
BA_ "GenMsgStartValue" BO_ 181 "00f0e018704000030007ffff";
BA_ "PduName" BO_ 181 "LHZCU_10ms_PDU32";
BA_ "VFrameFormat" BO_ 181 14;
BA_ "FrameTriggeringName" BO_ 1149 "LHZCU_BKBCANFD_400ms_FrP01";
BA_ "GenMsgCycleTime" BO_ 1149 400;
BA_ "GenMsgSendType" BO_ 1149 0;
BA_ "GenMsgStartValue" BO_ 1149 "0202373700370037";
BA_ "PduName" BO_ 1149 "LHZCU_400ms_PDU01";
BA_ "VFrameFormat" BO_ 1149 14;
BA_ "FrameTriggeringName" BO_ 1148 "LHZCU_BKBCANFD_400ms_FrP03";
BA_ "GenMsgCycleTime" BO_ 1148 400;
BA_ "GenMsgSendType" BO_ 1148 0;
BA_ "GenMsgStartValue" BO_ 1148 "5a5a5a5a00000000";
BA_ "PduName" BO_ 1148 "LHZCU_400ms_PDU03";
BA_ "VFrameFormat" BO_ 1148 14;
BA_ "FrameTriggeringName" BO_ 638 "LHZCU_BKBCANFD_50ms_FrP24";
BA_ "GenMsgCycleTime" BO_ 638 50;
BA_ "GenMsgSendType" BO_ 638 0;
BA_ "GenMsgStartValue" BO_ 638 "0000fffefefec39ffffce3fffffc0003ffffffff";
BA_ "PduName" BO_ 638 "LHZCU_50ms_PDU24";
BA_ "VFrameFormat" BO_ 638 14;
BA_ "FrameTriggeringName" BO_ 745 "LHZCU_BKBCANFD_50ms_FrP34";
BA_ "GenMsgCycleTime" BO_ 745 50;
BA_ "GenMsgSendType" BO_ 745 0;
BA_ "GenMsgStartValue" BO_ 745 "00000000000000000000000000000000";
BA_ "PduName" BO_ 745 "LHZCU_50ms_PDU34";
BA_ "VFrameFormat" BO_ 745 14;
BA_ "FrameTriggeringName" BO_ 640 "LHZCU_BKBCANFD_50ms_FrP58";
BA_ "GenMsgCycleTime" BO_ 640 50;
BA_ "GenMsgSendType" BO_ 640 0;
BA_ "GenMsgStartValue" BO_ 640 "000000000000000000000000000000000000000000000000";
BA_ "PduName" BO_ 640 "LHZCU_50ms_PDU58";
BA_ "VFrameFormat" BO_ 640 14;
BA_ "FrameTriggeringName" BO_ 513 "LHZCU_ICBVC_LHBKBCANFD_50ms_FrP14";
BA_ "GenMsgCycleTime" BO_ 513 50;
BA_ "GenMsgSendType" BO_ 513 0;
BA_ "GenMsgStartValue" BO_ 513 "0000000000000000";
BA_ "PduName" BO_ 513 "LHZCU_ICBVC_50ms_PDU14";
BA_ "SystemMessageLongSymbol" BO_ 513 "LHZCU_ICBVC_LHBKBCANFD_50ms_FrP14";
BA_ "VFrameFormat" BO_ 513 14;
BA_ "FrameTriggeringName" BO_ 800 "LHZCU_LHBKBCANFD_100ms_FrP14";
BA_ "GenMsgCycleTime" BO_ 800 100;
BA_ "GenMsgSendType" BO_ 800 0;
BA_ "GenMsgStartValue" BO_ 800 "0000000000000000";
BA_ "PduName" BO_ 800 "LHZCU_100ms_PDU14";
BA_ "VFrameFormat" BO_ 800 14;
BA_ "FrameTriggeringName" BO_ 905 "LHZCU_LHBKBCANFD_100ms_FrP15";
BA_ "GenMsgCycleTime" BO_ 905 100;
BA_ "GenMsgSendType" BO_ 905 0;
BA_ "GenMsgStartValue" BO_ 905 "0000000000000000";
BA_ "PduName" BO_ 905 "LHZCU_100ms_PDU15";
BA_ "VFrameFormat" BO_ 905 14;
BA_ "FrameTriggeringName" BO_ 783 "LHZCU_LHBKBCANFD_100ms_FrP16";
BA_ "GenMsgCycleTime" BO_ 783 100;
BA_ "GenMsgSendType" BO_ 783 0;
BA_ "GenMsgStartValue" BO_ 783 "00000000000000000000000000000000000000000000000000000000000000000000000000000000000000000000000000000000000000000000000000000000";
BA_ "PduName" BO_ 783 "LHZCU_100ms_PDU16";
BA_ "VFrameFormat" BO_ 783 14;
BA_ "FrameTriggeringName" BO_ 896 "LHZCU_LHBKBCANFD_100ms_FrP22";
BA_ "GenMsgCycleTime" BO_ 896 100;
BA_ "GenMsgSendType" BO_ 896 0;
BA_ "GenMsgStartValue" BO_ 896 "0000000000000000";
BA_ "PduName" BO_ 896 "LHZCU_100ms_PDU22";
BA_ "VFrameFormat" BO_ 896 14;
BA_ "FrameTriggeringName" BO_ 157 "LHZCU_LHBKBCANFD_10ms_FrP01";
BA_ "GenMsgCycleTime" BO_ 157 10;
BA_ "GenMsgSendType" BO_ 157 0;
BA_ "GenMsgStartValue" BO_ 157 "000000783a0f0800";
BA_ "PduName" BO_ 157 "LHZCU_10ms_PDU01";
BA_ "VFrameFormat" BO_ 157 14;
BA_ "FrameTriggeringName" BO_ 299 "LHZCU_LHBKBCANFD_20ms_FrP03";
BA_ "GenMsgCycleTime" BO_ 299 20;
BA_ "GenMsgSendType" BO_ 299 0;
BA_ "GenMsgStartValue" BO_ 299 "00f0fffffffbc000";
BA_ "PduName" BO_ 299 "LHZCU_20ms_PDU03";
BA_ "VFrameFormat" BO_ 299 14;
BA_ "CompuMethodName" SG_ 1202 IPD_NM_BSMtoRMS_BKPCANFD "IPD_NM_BSMtoRMS_BKPCANFD";
BA_ "ISignalName" SG_ 1202 IPD_NM_BSMtoRMS_BKPCANFD "IIPD_NM_BSMtoRMS_BKPCANFD";
BA_ "LongName" SG_ 1202 IPD_NM_BSMtoRMS_BKPCANFD "IPD_NM_BSMtoRMS_BKPCANFD";
BA_ "SysSignalName" SG_ 1202 IPD_NM_BSMtoRMS_BKPCANFD "IPD_NM_BSMtoRMS_BKPCANFD";
BA_ "CompuMethodName" SG_ 1202 IPD_NM_PBSMtoRMS_BKPCANFD "IPD_NM_PBSMtoRMS_BKPCANFD";
BA_ "ISignalName" SG_ 1202 IPD_NM_PBSMtoRMS_BKPCANFD "IIPD_NM_PBSMtoRMS_BKPCANFD";
BA_ "LongName" SG_ 1202 IPD_NM_PBSMtoRMS_BKPCANFD "IPD_NM_PBSMtoRMS_BKPCANFD";
BA_ "SysSignalName" SG_ 1202 IPD_NM_PBSMtoRMS_BKPCANFD "IPD_NM_PBSMtoRMS_BKPCANFD";
BA_ "CompuMethodName" SG_ 1202 IPD_NM_RMStoNOS_BKPCANFD "IPD_NM_RMStoNOS_BKPCANFD";
BA_ "ISignalName" SG_ 1202 IPD_NM_RMStoNOS_BKPCANFD "IIPD_NM_RMStoNOS_BKPCANFD";
BA_ "LongName" SG_ 1202 IPD_NM_RMStoNOS_BKPCANFD "IPD_NM_RMStoNOS_BKPCANFD";
BA_ "SysSignalName" SG_ 1202 IPD_NM_RMStoNOS_BKPCANFD "IPD_NM_RMStoNOS_BKPCANFD";
BA_ "CompuMethodName" SG_ 1202 IPD_NM_RSStoNOS_BKPCANFD "IPD_NM_RSStoNOS_BKPCANFD";
BA_ "ISignalName" SG_ 1202 IPD_NM_RSStoNOS_BKPCANFD "IIPD_NM_RSStoNOS_BKPCANFD";
BA_ "LongName" SG_ 1202 IPD_NM_RSStoNOS_BKPCANFD "IPD_NM_RSStoNOS_BKPCANFD";
BA_ "SysSignalName" SG_ 1202 IPD_NM_RSStoNOS_BKPCANFD "IPD_NM_RSStoNOS_BKPCANFD";
BA_ "CompuMethodName" SG_ 1202 IPD_NM_RSStoRMS_BKPCANFD "IPD_NM_RSStoRMS_BKPCANFD";
BA_ "ISignalName" SG_ 1202 IPD_NM_RSStoRMS_BKPCANFD "IIPD_NM_RSStoRMS_BKPCANFD";
BA_ "LongName" SG_ 1202 IPD_NM_RSStoRMS_BKPCANFD "IPD_NM_RSStoRMS_BKPCANFD";
BA_ "SysSignalName" SG_ 1202 IPD_NM_RSStoRMS_BKPCANFD "IPD_NM_RSStoRMS_BKPCANFD";
BA_ "CompuMethodName" SG_ 1202 IPD_NM_NOStoRMS_BKPCANFD "IPD_NM_NOStoRMS_BKPCANFD";
BA_ "ISignalName" SG_ 1202 IPD_NM_NOStoRMS_BKPCANFD "IIPD_NM_NOStoRMS_BKPCANFD";
BA_ "LongName" SG_ 1202 IPD_NM_NOStoRMS_BKPCANFD "IPD_NM_NOStoRMS_BKPCANFD";
BA_ "SysSignalName" SG_ 1202 IPD_NM_NOStoRMS_BKPCANFD "IPD_NM_NOStoRMS_BKPCANFD";
BA_ "CompuMethodName" SG_ 1202 IPD_NM_NOSSta_BKPCANFD "IPD_NM_NOSSta_BKPCANFD";
BA_ "ISignalName" SG_ 1202 IPD_NM_NOSSta_BKPCANFD "IIPD_NM_NOSSta_BKPCANFD";
BA_ "LongName" SG_ 1202 IPD_NM_NOSSta_BKPCANFD "IPD_NM_NOSSta_BKPCANFD";
BA_ "SysSignalName" SG_ 1202 IPD_NM_NOSSta_BKPCANFD "IPD_NM_NOSSta_BKPCANFD";
BA_ "CompuMethodName" SG_ 1202 IPD_NM_RMSSta_BKPCANFD "IPD_NM_RMSSta_BKPCANFD";
BA_ "ISignalName" SG_ 1202 IPD_NM_RMSSta_BKPCANFD "IIPD_NM_RMSSta_BKPCANFD";
BA_ "LongName" SG_ 1202 IPD_NM_RMSSta_BKPCANFD "IPD_NM_RMSSta_BKPCANFD";
BA_ "SysSignalName" SG_ 1202 IPD_NM_RMSSta_BKPCANFD "IPD_NM_RMSSta_BKPCANFD";
BA_ "CompuMethodName" SG_ 1202 IPD_NWI_BKPCANFD "IPD_NWI_BKPCANFD";
BA_ "ISignalName" SG_ 1202 IPD_NWI_BKPCANFD "IIPD_NWI_BKPCANFD";
BA_ "LongName" SG_ 1202 IPD_NWI_BKPCANFD "IPD BKPCANFD Network_Wakeup_Indication";
BA_ "SysSignalName" SG_ 1202 IPD_NWI_BKPCANFD "IPD_NWI_BKPCANFD";
BA_ "CompuMethodName" SG_ 1202 IPD_NOI_BKPCANFD "IPD_NOI_BKPCANFD";
BA_ "ISignalName" SG_ 1202 IPD_NOI_BKPCANFD "IIPD_NOI_BKPCANFD";
BA_ "LongName" SG_ 1202 IPD_NOI_BKPCANFD "IPD BKPCANFD Network Operation Indication";
BA_ "SysSignalName" SG_ 1202 IPD_NOI_BKPCANFD "IPD_NOI_BKPCANFD";
BA_ "CompuMethodName" SG_ 1202 IPD_NKI_BKPCANFD "IPD_NKI_BKPCANFD";
BA_ "ISignalName" SG_ 1202 IPD_NKI_BKPCANFD "IIPD_NKI_BKPCANFD";
BA_ "LongName" SG_ 1202 IPD_NKI_BKPCANFD "IPD BKPCANFD Network Keep Indication";
BA_ "SysSignalName" SG_ 1202 IPD_NKI_BKPCANFD "IPD_NKI_BKPCANFD";
BA_ "CompuMethodName" SG_ 705 RASysSts "RASysSts";
BA_ "ISignalName" SG_ 705 RASysSts "IRASysSts";
BA_ "LongName" SG_ 705 RASysSts "Reverse Assist Systerm Status";
BA_ "SysSignalName" SG_ 705 RASysSts "RASysSts";
BA_ "CompuMethodName" SG_ 705 HWPEMStsForEdr "HWPEMStsForEdr";
BA_ "ISignalName" SG_ 705 HWPEMStsForEdr "IHWPEMStsForEdr";
BA_ "LongName" SG_ 705 HWPEMStsForEdr "L3 Function Emergency mode Status For Edr";
BA_ "SysSignalName" SG_ 705 HWPEMStsForEdr "HWPEMStsForEdr";
BA_ "CompuMethodName" SG_ 705 HWPEMSts "HWPEMSts";
BA_ "ISignalName" SG_ 705 HWPEMSts "IHWPEMSts";
BA_ "LongName" SG_ 705 HWPEMSts "HWP Function Emergency mode Status";
BA_ "SysSignalName" SG_ 705 HWPEMSts "HWPEMSts";
BA_ "CompuMethodName" SG_ 982 ACCDetObjLongtRltvDist "ACCDetObjLongtRltvDist";
BA_ "ISignalName" SG_ 982 ACCDetObjLongtRltvDist "IACCDetObjLongtRltvDist";
BA_ "LongName" SG_ 982 ACCDetObjLongtRltvDist "Adaptive_Cruise_Control_Detected_Object_Longitudinal_Relative_Distance";
BA_ "SysSignalName" SG_ 982 ACCDetObjLongtRltvDist "ACCDetObjLongtRltvDist";
BA_ "CompuMethodName" SG_ 982 ACCDetObjSyncCtr "ACCDetObjSyncCtr";
BA_ "ISignalName" SG_ 982 ACCDetObjSyncCtr "IACCDetObjSyncCtr";
BA_ "LongName" SG_ 982 ACCDetObjSyncCtr "Adaptive_Cruise_Control_Detected_Object_Synchronize_Counter";
BA_ "SysSignalName" SG_ 982 ACCDetObjSyncCtr "ACCDetObjSyncCtr";
BA_ "CompuMethodName" SG_ 982 ACCDetObjLongtRltvSpd "ACCDetObjLongtRltvSpd";
BA_ "ISignalName" SG_ 982 ACCDetObjLongtRltvSpd "IACCDetObjLongtRltvSpd";
BA_ "LongName" SG_ 982 ACCDetObjLongtRltvSpd "Adaptive_Cruise_Control_Detected_Object_Longitudinal_Relative_Speed";
BA_ "SysSignalName" SG_ 982 ACCDetObjLongtRltvSpd "ACCDetObjLongtRltvSpd";
BA_ "CompuMethodName" SG_ 982 ACCDetObjRisk "ACCDetObjRisk";
BA_ "ISignalName" SG_ 982 ACCDetObjRisk "IACCDetObjRisk";
BA_ "LongName" SG_ 982 ACCDetObjRisk "Adaptive_Cruise_Control_Detected_Object_0_Risk";
BA_ "SysSignalName" SG_ 982 ACCDetObjRisk "ACCDetObjRisk";
BA_ "CompuMethodName" SG_ 982 ACCDetObjTyp "ACCDetObjTyp";
BA_ "ISignalName" SG_ 982 ACCDetObjTyp "IACCDetObjTyp";
BA_ "LongName" SG_ 982 ACCDetObjTyp "Adaptive_Cruise_Control_Detected_Object_0_Type";
BA_ "SysSignalName" SG_ 982 ACCDetObjTyp "ACCDetObjTyp";
BA_ "CompuMethodName" SG_ 982 ACCDetObjLatRltvDist "ACCDetObjLatRltvDist";
BA_ "ISignalName" SG_ 982 ACCDetObjLatRltvDist "IACCDetObjLatRltvDist";
BA_ "LongName" SG_ 982 ACCDetObjLatRltvDist "Adaptive_Cruise_Control_Detected_Object_Lateral_Relative_Distance";
BA_ "SysSignalName" SG_ 982 ACCDetObjLatRltvDist "ACCDetObjLatRltvDist";
BA_ "CompuMethodName" SG_ 982 ACCDetObjExistPrblty "ACCDetObjExistPrblty";
BA_ "ISignalName" SG_ 982 ACCDetObjExistPrblty "IACCDetObjExistPrblty";
BA_ "LongName" SG_ 982 ACCDetObjExistPrblty "Adaptive_Cruise_Control_Detected_Object_Exist_Probability";
BA_ "SysSignalName" SG_ 982 ACCDetObjExistPrblty "ACCDetObjExistPrblty";
BA_ "CompuMethodName" SG_ 982 ACCDetObjId "ACCDetObjId";
BA_ "ISignalName" SG_ 982 ACCDetObjId "IACCDetObjId";
BA_ "LongName" SG_ 982 ACCDetObjId "Adaptive_Cruise_Control_Detected_Object_Identifier";
BA_ "SysSignalName" SG_ 982 ACCDetObjId "ACCDetObjId";
BA_ "CompuMethodName" SG_ 960 IPDThermalWrnngLvl "IPDThermalWrnngLvl";
BA_ "ISignalName" SG_ 960 IPDThermalWrnngLvl "IIPDThermalWrnngLvl";
BA_ "LongName" SG_ 960 IPDThermalWrnngLvl "IPD Thermal Warning Level";
BA_ "SysSignalName" SG_ 960 IPDThermalWrnngLvl "IPDThermalWrnngLvl";
BA_ "CompuMethodName" SG_ 960 IPDPMICTemp "IPDPMICTemp";
BA_ "GenSigStartValue" SG_ 960 IPDPMICTemp 255;
BA_ "ISignalName" SG_ 960 IPDPMICTemp "IIPDPMICTemp";
BA_ "LongName" SG_ 960 IPDPMICTemp "IPD PMIC Temperature";
BA_ "SysSignalName" SG_ 960 IPDPMICTemp "IPDPMICTemp";
BA_ "CompuMethodName" SG_ 960 IPDPCBTemp2 "IPDPCBTemp2";
BA_ "GenSigStartValue" SG_ 960 IPDPCBTemp2 255;
BA_ "ISignalName" SG_ 960 IPDPCBTemp2 "IIPDPCBTemp2";
BA_ "LongName" SG_ 960 IPDPCBTemp2 "IPD PCB Temperature 2";
BA_ "SysSignalName" SG_ 960 IPDPCBTemp2 "IPDPCBTemp2";
BA_ "CompuMethodName" SG_ 960 IPDPCBTemp1 "IPDPCBTemp1";
BA_ "GenSigStartValue" SG_ 960 IPDPCBTemp1 255;
BA_ "ISignalName" SG_ 960 IPDPCBTemp1 "IIPDPCBTemp1";
BA_ "LongName" SG_ 960 IPDPCBTemp1 "IPD PCB Temperature 1";
BA_ "SysSignalName" SG_ 960 IPDPCBTemp1 "IPDPCBTemp1";
BA_ "CompuMethodName" SG_ 960 IPDSOCTemp "IPDSOCTemp";
BA_ "GenSigStartValue" SG_ 960 IPDSOCTemp 255;
BA_ "ISignalName" SG_ 960 IPDSOCTemp "IIPDSOCTemp";
BA_ "LongName" SG_ 960 IPDSOCTemp "IPD Orin Temperature";
BA_ "SysSignalName" SG_ 960 IPDSOCTemp "IPDSOCTemp";
BA_ "CompuMethodName" SG_ 960 IPDAurixTemp "IPDAurixTemp";
BA_ "GenSigStartValue" SG_ 960 IPDAurixTemp 255;
BA_ "ISignalName" SG_ 960 IPDAurixTemp "IIPDAurixTemp";
BA_ "LongName" SG_ 960 IPDAurixTemp "IPD Aurix Temperature";
BA_ "SysSignalName" SG_ 960 IPDAurixTemp "IPDAurixTemp";
BA_ "CompuMethodName" SG_ 1231 LFSDA_NM_BSMtoRMS_BKPCANFD "LFSDA_NM_BSMtoRMS_BKPCANFD";
BA_ "ISignalName" SG_ 1231 LFSDA_NM_BSMtoRMS_BKPCANFD "ILFSDA_NM_BSMtoRMS_BKPCANFD";
BA_ "LongName" SG_ 1231 LFSDA_NM_BSMtoRMS_BKPCANFD "LFSDA_NM_BSMtoRMS_BKPCANFD";
BA_ "SysSignalName" SG_ 1231 LFSDA_NM_BSMtoRMS_BKPCANFD "LFSDA_NM_BSMtoRMS_BKPCANFD";
BA_ "CompuMethodName" SG_ 1231 LFSDA_NM_PBSMtoRMS_BKPCANFD "LFSDA_NM_PBSMtoRMS_BKPCANFD";
BA_ "ISignalName" SG_ 1231 LFSDA_NM_PBSMtoRMS_BKPCANFD "ILFSDA_NM_PBSMtoRMS_BKPCANFD";
BA_ "LongName" SG_ 1231 LFSDA_NM_PBSMtoRMS_BKPCANFD "LFSDA_NM_PBSMtoRMS_BKPCANFD";
BA_ "SysSignalName" SG_ 1231 LFSDA_NM_PBSMtoRMS_BKPCANFD "LFSDA_NM_PBSMtoRMS_BKPCANFD";
BA_ "CompuMethodName" SG_ 1231 LFSDA_NM_RMStoNOS_BKPCANFD "LFSDA_NM_RMStoNOS_BKPCANFD";
BA_ "ISignalName" SG_ 1231 LFSDA_NM_RMStoNOS_BKPCANFD "ILFSDA_NM_RMStoNOS_BKPCANFD";
BA_ "LongName" SG_ 1231 LFSDA_NM_RMStoNOS_BKPCANFD "LFSDA_NM_RMStoNOS_BKPCANFD";
BA_ "SysSignalName" SG_ 1231 LFSDA_NM_RMStoNOS_BKPCANFD "LFSDA_NM_RMStoNOS_BKPCANFD";
BA_ "CompuMethodName" SG_ 1231 LFSDA_NM_RSStoNOS_BKPCANFD "LFSDA_NM_RSStoNOS_BKPCANFD";
BA_ "ISignalName" SG_ 1231 LFSDA_NM_RSStoNOS_BKPCANFD "ILFSDA_NM_RSStoNOS_BKPCANFD";
BA_ "LongName" SG_ 1231 LFSDA_NM_RSStoNOS_BKPCANFD "LFSDA_NM_RSStoNOS_BKPCANFD";
BA_ "SysSignalName" SG_ 1231 LFSDA_NM_RSStoNOS_BKPCANFD "LFSDA_NM_RSStoNOS_BKPCANFD";
BA_ "CompuMethodName" SG_ 1231 LFSDA_NM_RSStoRMS_BKPCANFD "LFSDA_NM_RSStoRMS_BKPCANFD";
BA_ "ISignalName" SG_ 1231 LFSDA_NM_RSStoRMS_BKPCANFD "ILFSDA_NM_RSStoRMS_BKPCANFD";
BA_ "LongName" SG_ 1231 LFSDA_NM_RSStoRMS_BKPCANFD "LFSDA_NM_RSStoRMS_BKPCANFD";
BA_ "SysSignalName" SG_ 1231 LFSDA_NM_RSStoRMS_BKPCANFD "LFSDA_NM_RSStoRMS_BKPCANFD";
BA_ "CompuMethodName" SG_ 1231 LFSDA_NM_NOStoRMS_BKPCANFD "LFSDA_NM_NOStoRMS_BKPCANFD";
BA_ "ISignalName" SG_ 1231 LFSDA_NM_NOStoRMS_BKPCANFD "ILFSDA_NM_NOStoRMS_BKPCANFD";
BA_ "LongName" SG_ 1231 LFSDA_NM_NOStoRMS_BKPCANFD "LFSDA_NM_NOStoRMS_BKPCANFD";
BA_ "SysSignalName" SG_ 1231 LFSDA_NM_NOStoRMS_BKPCANFD "LFSDA_NM_NOStoRMS_BKPCANFD";
BA_ "CompuMethodName" SG_ 1231 LFSDA_NM_NOSSta_BKPCANFD "LFSDA_NM_NOSSta_BKPCANFD";
BA_ "ISignalName" SG_ 1231 LFSDA_NM_NOSSta_BKPCANFD "ILFSDA_NM_NOSSta_BKPCANFD";
BA_ "LongName" SG_ 1231 LFSDA_NM_NOSSta_BKPCANFD "LFSDA_NM_NOSSta_BKPCANFD";
BA_ "SysSignalName" SG_ 1231 LFSDA_NM_NOSSta_BKPCANFD "LFSDA_NM_NOSSta_BKPCANFD";
BA_ "CompuMethodName" SG_ 1231 LFSDA_NM_RMSSta_BKPCANFD "LFSDA_NM_RMSSta_BKPCANFD";
BA_ "ISignalName" SG_ 1231 LFSDA_NM_RMSSta_BKPCANFD "ILFSDA_NM_RMSSta_BKPCANFD";
BA_ "LongName" SG_ 1231 LFSDA_NM_RMSSta_BKPCANFD "LFSDA_NM_RMSSta_BKPCANFD";
BA_ "SysSignalName" SG_ 1231 LFSDA_NM_RMSSta_BKPCANFD "LFSDA_NM_RMSSta_BKPCANFD";
BA_ "CompuMethodName" SG_ 1231 LFSDA_NWI_BKPCANFD "LFSDA_NWI_BKPCANFD";
BA_ "ISignalName" SG_ 1231 LFSDA_NWI_BKPCANFD "ILFSDA_NWI_BKPCANFD";
BA_ "LongName" SG_ 1231 LFSDA_NWI_BKPCANFD "LFSDA_BKPCANFD Network Wakeup Indication";
BA_ "SysSignalName" SG_ 1231 LFSDA_NWI_BKPCANFD "LFSDA_NWI_BKPCANFD";
BA_ "CompuMethodName" SG_ 1231 LFSDA_NOI_BKPCANFD "LFSDA_NOI_BKPCANFD";
BA_ "ISignalName" SG_ 1231 LFSDA_NOI_BKPCANFD "ILFSDA_NOI_BKPCANFD";
BA_ "LongName" SG_ 1231 LFSDA_NOI_BKPCANFD "LFSDA BKPCANFD Network Operation Indication";
BA_ "SysSignalName" SG_ 1231 LFSDA_NOI_BKPCANFD "LFSDA_NOI_BKPCANFD";
BA_ "CompuMethodName" SG_ 1231 LFSDA_NKI_BKPCANFD "LFSDA_NKI_BKPCANFD";
BA_ "ISignalName" SG_ 1231 LFSDA_NKI_BKPCANFD "ILFSDA_NKI_BKPCANFD";
BA_ "LongName" SG_ 1231 LFSDA_NKI_BKPCANFD "LFSDA BKPCANFD Network Keep Indication";
BA_ "SysSignalName" SG_ 1231 LFSDA_NKI_BKPCANFD "LFSDA_NKI_BKPCANFD";
BA_ "CompuMethodName" SG_ 1229 LHRDA_NM_BSMtoRMS_BKPCANFD "LHRDA_NM_BSMtoRMS_BKPCANFD";
BA_ "ISignalName" SG_ 1229 LHRDA_NM_BSMtoRMS_BKPCANFD "ILHRDA_NM_BSMtoRMS_BKPCANFD";
BA_ "LongName" SG_ 1229 LHRDA_NM_BSMtoRMS_BKPCANFD "LHRDA_NM_BSMtoRMS_BKPCANFD";
BA_ "SysSignalName" SG_ 1229 LHRDA_NM_BSMtoRMS_BKPCANFD "LHRDA_NM_BSMtoRMS_BKPCANFD";
BA_ "CompuMethodName" SG_ 1229 LHRDA_NM_PBSMtoRMS_BKPCANFD "LHRDA_NM_PBSMtoRMS_BKPCANFD";
BA_ "ISignalName" SG_ 1229 LHRDA_NM_PBSMtoRMS_BKPCANFD "ILHRDA_NM_PBSMtoRMS_BKPCANFD";
BA_ "LongName" SG_ 1229 LHRDA_NM_PBSMtoRMS_BKPCANFD "LHRDA_NM_PBSMtoRMS_BKPCANFD";
BA_ "SysSignalName" SG_ 1229 LHRDA_NM_PBSMtoRMS_BKPCANFD "LHRDA_NM_PBSMtoRMS_BKPCANFD";
BA_ "CompuMethodName" SG_ 1229 LHRDA_NM_RMStoNOS_BKPCANFD "LHRDA_NM_RMStoNOS_BKPCANFD";
BA_ "ISignalName" SG_ 1229 LHRDA_NM_RMStoNOS_BKPCANFD "ILHRDA_NM_RMStoNOS_BKPCANFD";
BA_ "LongName" SG_ 1229 LHRDA_NM_RMStoNOS_BKPCANFD "LHRDA_NM_RMStoNOS_BKPCANFD";
BA_ "SysSignalName" SG_ 1229 LHRDA_NM_RMStoNOS_BKPCANFD "LHRDA_NM_RMStoNOS_BKPCANFD";
BA_ "CompuMethodName" SG_ 1229 LHRDA_NM_RSStoNOS_BKPCANFD "LHRDA_NM_RSStoNOS_BKPCANFD";
BA_ "ISignalName" SG_ 1229 LHRDA_NM_RSStoNOS_BKPCANFD "ILHRDA_NM_RSStoNOS_BKPCANFD";
BA_ "LongName" SG_ 1229 LHRDA_NM_RSStoNOS_BKPCANFD "LHRDA_NM_RSStoNOS_BKPCANFD";
BA_ "SysSignalName" SG_ 1229 LHRDA_NM_RSStoNOS_BKPCANFD "LHRDA_NM_RSStoNOS_BKPCANFD";
BA_ "CompuMethodName" SG_ 1229 LHRDA_NM_RSStoRMS_BKPCANFD "LHRDA_NM_RSStoRMS_BKPCANFD";
BA_ "ISignalName" SG_ 1229 LHRDA_NM_RSStoRMS_BKPCANFD "ILHRDA_NM_RSStoRMS_BKPCANFD";
BA_ "LongName" SG_ 1229 LHRDA_NM_RSStoRMS_BKPCANFD "LHRDA_NM_RSStoRMS_BKPCANFD";
BA_ "SysSignalName" SG_ 1229 LHRDA_NM_RSStoRMS_BKPCANFD "LHRDA_NM_RSStoRMS_BKPCANFD";
BA_ "CompuMethodName" SG_ 1229 LHRDA_NM_NOStoRMS_BKPCANFD "LHRDA_NM_NOStoRMS_BKPCANFD";
BA_ "ISignalName" SG_ 1229 LHRDA_NM_NOStoRMS_BKPCANFD "ILHRDA_NM_NOStoRMS_BKPCANFD";
BA_ "LongName" SG_ 1229 LHRDA_NM_NOStoRMS_BKPCANFD "LHRDA_NM_NOStoRMS_BKPCANFD";
BA_ "SysSignalName" SG_ 1229 LHRDA_NM_NOStoRMS_BKPCANFD "LHRDA_NM_NOStoRMS_BKPCANFD";
BA_ "CompuMethodName" SG_ 1229 LHRDA_NM_NOSSta_BKPCANFD "LHRDA_NM_NOSSta_BKPCANFD";
BA_ "ISignalName" SG_ 1229 LHRDA_NM_NOSSta_BKPCANFD "ILHRDA_NM_NOSSta_BKPCANFD";
BA_ "LongName" SG_ 1229 LHRDA_NM_NOSSta_BKPCANFD "LHRDA_NM_NOSSta_BKPCANFD";
BA_ "SysSignalName" SG_ 1229 LHRDA_NM_NOSSta_BKPCANFD "LHRDA_NM_NOSSta_BKPCANFD";
BA_ "CompuMethodName" SG_ 1229 LHRDA_NM_RMSSta_BKPCANFD "LHRDA_NM_RMSSta_BKPCANFD";
BA_ "ISignalName" SG_ 1229 LHRDA_NM_RMSSta_BKPCANFD "ILHRDA_NM_RMSSta_BKPCANFD";
BA_ "LongName" SG_ 1229 LHRDA_NM_RMSSta_BKPCANFD "LHRDA_NM_RMSSta_BKPCANFD";
BA_ "SysSignalName" SG_ 1229 LHRDA_NM_RMSSta_BKPCANFD "LHRDA_NM_RMSSta_BKPCANFD";
BA_ "CompuMethodName" SG_ 1229 LHRDA_NWI_BKPCANFD "LHRDA_NWI_BKPCANFD";
BA_ "ISignalName" SG_ 1229 LHRDA_NWI_BKPCANFD "ILHRDA_NWI_BKPCANFD";
BA_ "LongName" SG_ 1229 LHRDA_NWI_BKPCANFD "LHRDA BKPCANFD Network_Wakeup_Indication";
BA_ "SysSignalName" SG_ 1229 LHRDA_NWI_BKPCANFD "LHRDA_NWI_BKPCANFD";
BA_ "CompuMethodName" SG_ 1229 LHRDA_NOI_BKPCANFD "LHRDA_NOI_BKPCANFD";
BA_ "ISignalName" SG_ 1229 LHRDA_NOI_BKPCANFD "ILHRDA_NOI_BKPCANFD";
BA_ "LongName" SG_ 1229 LHRDA_NOI_BKPCANFD "LHRDA BKPCANFD Network Operation Indication";
BA_ "SysSignalName" SG_ 1229 LHRDA_NOI_BKPCANFD "LHRDA_NOI_BKPCANFD";
BA_ "CompuMethodName" SG_ 1229 LHRDA_NKI_BKPCANFD "LHRDA_NKI_BKPCANFD";
BA_ "ISignalName" SG_ 1229 LHRDA_NKI_BKPCANFD "ILHRDA_NKI_BKPCANFD";
BA_ "LongName" SG_ 1229 LHRDA_NKI_BKPCANFD "LHRDA BKPCANFD Network Keep Indication";
BA_ "SysSignalName" SG_ 1229 LHRDA_NKI_BKPCANFD "LHRDA_NKI_BKPCANFD";
BA_ "CompuMethodName" SG_ 995 LHZCU_100ms_Group30_CRC "LHZCU_100ms_Group30_CRC";
BA_ "ISignalName" SG_ 995 LHZCU_100ms_Group30_CRC "ILHZCU_100ms_Group30_CRC";
BA_ "LongName" SG_ 995 LHZCU_100ms_Group30_CRC "LHZCU_100ms_Group30_CRC";
BA_ "SysSignalName" SG_ 995 LHZCU_100ms_Group30_CRC "LHZCU_100ms_Group30_CRC";
BA_ "CompuMethodName" SG_ 995 LHZCU_100ms_Group30_RC "LHZCU_100ms_Group30_RC";
BA_ "ISignalName" SG_ 995 LHZCU_100ms_Group30_RC "ILHZCU_100ms_Group30_RC";
BA_ "LongName" SG_ 995 LHZCU_100ms_Group30_RC "LHZCU_100ms_Group30_RC";
BA_ "SysSignalName" SG_ 995 LHZCU_100ms_Group30_RC "LHZCU_100ms_Group30_RC";
BA_ "CompuMethodName" SG_ 995 LHZCU_100ms_Group30_Reserved12 "LHZCU_100ms_Group30_Reserved12";
BA_ "GenSigStartValue" SG_ 995 LHZCU_100ms_Group30_Reserved12 1;
BA_ "ISignalName" SG_ 995 LHZCU_100ms_Group30_Reserved12 "ILHZCU_100ms_Group30_Reserved12";
BA_ "SysSignalName" SG_ 995 LHZCU_100ms_Group30_Reserved12 "LHZCU_100ms_Group30_Reserved12";
BA_ "CompuMethodName" SG_ 995 DircnIndLampSwStsMntry "DircnIndLampSwStsMntry";
BA_ "ISignalName" SG_ 995 DircnIndLampSwStsMntry "IDircnIndLampSwStsMntry";
BA_ "LongName" SG_ 995 DircnIndLampSwStsMntry "Direction Indication Lamp Switch Status Momentary";
BA_ "SysSignalName" SG_ 995 DircnIndLampSwStsMntry "DircnIndLampSwStsMntry";
BA_ "CompuMethodName" SG_ 995 LHZCU_100ms_Group30_Reserved23 "LHZCU_100ms_Group30_Reserved23";
BA_ "GenSigStartValue" SG_ 995 LHZCU_100ms_Group30_Reserved23 255;
BA_ "ISignalName" SG_ 995 LHZCU_100ms_Group30_Reserved23 "ILHZCU_100ms_Group30_Reserved23";
BA_ "SysSignalName" SG_ 995 LHZCU_100ms_Group30_Reserved23 "LHZCU_100ms_Group30_Reserved23";
BA_ "CompuMethodName" SG_ 995 LHZCU_100ms_Group30_Reserved31 "LHZCU_100ms_Group30_Reserved31";
BA_ "GenSigStartValue" SG_ 995 LHZCU_100ms_Group30_Reserved31 255;
BA_ "ISignalName" SG_ 995 LHZCU_100ms_Group30_Reserved31 "ILHZCU_100ms_Group30_Reserved31";
BA_ "SysSignalName" SG_ 995 LHZCU_100ms_Group30_Reserved31 "LHZCU_100ms_Group30_Reserved31";
BA_ "CompuMethodName" SG_ 995 FLSeatHorzPos "FLSeatHorzPos";
BA_ "GenSigStartValue" SG_ 995 FLSeatHorzPos 255;
BA_ "ISignalName" SG_ 995 FLSeatHorzPos "IFLSeatHorzPos";
BA_ "LongName" SG_ 995 FLSeatHorzPos "FRONT LEFT
Seat Horizontal Position";
BA_ "SysSignalName" SG_ 995 FLSeatHorzPos "FLSeatHorzPos";
BA_ "CompuMethodName" SG_ 995 FLSeatVertPos "FLSeatVertPos";
BA_ "GenSigStartValue" SG_ 995 FLSeatVertPos 255;
BA_ "ISignalName" SG_ 995 FLSeatVertPos "IFLSeatVertPos";
BA_ "LongName" SG_ 995 FLSeatVertPos "Memory Seat Module Driver Seat Vertical Position";
BA_ "SysSignalName" SG_ 995 FLSeatVertPos "FLSeatVertPos";
BA_ "CompuMethodName" SG_ 995 LHZCU_100ms_Group30_Reserved55 "LHZCU_100ms_Group30_Reserved55";
BA_ "GenSigStartValue" SG_ 995 LHZCU_100ms_Group30_Reserved55 255;
BA_ "ISignalName" SG_ 995 LHZCU_100ms_Group30_Reserved55 "ILHZCU_100ms_Group30_Reserved55";
BA_ "SysSignalName" SG_ 995 LHZCU_100ms_Group30_Reserved55 "LHZCU_100ms_Group30_Reserved55";
BA_ "CompuMethodName" SG_ 995 LHZCU_100ms_Group30_Reserved63 "LHZCU_100ms_Group30_Reserved63";
BA_ "GenSigStartValue" SG_ 995 LHZCU_100ms_Group30_Reserved63 255;
BA_ "ISignalName" SG_ 995 LHZCU_100ms_Group30_Reserved63 "ILHZCU_100ms_Group30_Reserved63";
BA_ "SysSignalName" SG_ 995 LHZCU_100ms_Group30_Reserved63 "LHZCU_100ms_Group30_Reserved63";
BA_ "CompuMethodName" SG_ 995 LHZCU_100ms_Group30_Reserved71 "LHZCU_100ms_Group30_Reserved71";
BA_ "GenSigStartValue" SG_ 995 LHZCU_100ms_Group30_Reserved71 255;
BA_ "ISignalName" SG_ 995 LHZCU_100ms_Group30_Reserved71 "ILHZCU_100ms_Group30_Reserved71";
BA_ "SysSignalName" SG_ 995 LHZCU_100ms_Group30_Reserved71 "LHZCU_100ms_Group30_Reserved71";
BA_ "CompuMethodName" SG_ 995 LHZCU_100ms_Group30_Reserved79 "LHZCU_100ms_Group30_Reserved79";
BA_ "GenSigStartValue" SG_ 995 LHZCU_100ms_Group30_Reserved79 255;
BA_ "ISignalName" SG_ 995 LHZCU_100ms_Group30_Reserved79 "ILHZCU_100ms_Group30_Reserved79";
BA_ "SysSignalName" SG_ 995 LHZCU_100ms_Group30_Reserved79 "LHZCU_100ms_Group30_Reserved79";
BA_ "CompuMethodName" SG_ 995 LHZCU_100ms_Group30_Reserved87 "LHZCU_100ms_Group30_Reserved87";
BA_ "GenSigStartValue" SG_ 995 LHZCU_100ms_Group30_Reserved87 255;
BA_ "ISignalName" SG_ 995 LHZCU_100ms_Group30_Reserved87 "ILHZCU_100ms_Group30_Reserved87";
BA_ "SysSignalName" SG_ 995 LHZCU_100ms_Group30_Reserved87 "LHZCU_100ms_Group30_Reserved87";
BA_ "CompuMethodName" SG_ 995 LHZCU_100ms_Group30_Reserved95 "LHZCU_100ms_Group30_Reserved95";
BA_ "GenSigStartValue" SG_ 995 LHZCU_100ms_Group30_Reserved95 255;
BA_ "ISignalName" SG_ 995 LHZCU_100ms_Group30_Reserved95 "ILHZCU_100ms_Group30_Reserved95";
BA_ "SysSignalName" SG_ 995 LHZCU_100ms_Group30_Reserved95 "LHZCU_100ms_Group30_Reserved95";
BA_ "CompuMethodName" SG_ 995 LHZCU_100ms_Group30_Reserved103 "LHZCU_100ms_Group30_Reserved103";
BA_ "GenSigStartValue" SG_ 995 LHZCU_100ms_Group30_Reserved103 255;
BA_ "ISignalName" SG_ 995 LHZCU_100ms_Group30_Reserved103 "ILHZCU_100ms_Group30_Reserved103";
BA_ "SysSignalName" SG_ 995 LHZCU_100ms_Group30_Reserved103 "LHZCU_100ms_Group30_Reserved103";
BA_ "CompuMethodName" SG_ 995 LHZCU_100ms_Group30_Reserved111 "LHZCU_100ms_Group30_Reserved111";
BA_ "GenSigStartValue" SG_ 995 LHZCU_100ms_Group30_Reserved111 255;
BA_ "ISignalName" SG_ 995 LHZCU_100ms_Group30_Reserved111 "ILHZCU_100ms_Group30_Reserved111";
BA_ "SysSignalName" SG_ 995 LHZCU_100ms_Group30_Reserved111 "LHZCU_100ms_Group30_Reserved111";
BA_ "CompuMethodName" SG_ 995 LHZCU_100ms_Group30_Reserved119 "LHZCU_100ms_Group30_Reserved119";
BA_ "GenSigStartValue" SG_ 995 LHZCU_100ms_Group30_Reserved119 255;
BA_ "ISignalName" SG_ 995 LHZCU_100ms_Group30_Reserved119 "ILHZCU_100ms_Group30_Reserved119";
BA_ "SysSignalName" SG_ 995 LHZCU_100ms_Group30_Reserved119 "LHZCU_100ms_Group30_Reserved119";
BA_ "CompuMethodName" SG_ 995 LHZCU_100ms_Group30_Reserved127 "LHZCU_100ms_Group30_Reserved127";
BA_ "GenSigStartValue" SG_ 995 LHZCU_100ms_Group30_Reserved127 255;
BA_ "ISignalName" SG_ 995 LHZCU_100ms_Group30_Reserved127 "ILHZCU_100ms_Group30_Reserved127";
BA_ "SysSignalName" SG_ 995 LHZCU_100ms_Group30_Reserved127 "LHZCU_100ms_Group30_Reserved127";
BA_ "CompuMethodName" SG_ 181 LHZCU_10ms_Group32_CRC "LHZCU_10ms_Group32_CRC";
BA_ "ISignalName" SG_ 181 LHZCU_10ms_Group32_CRC "ILHZCU_10ms_Group32_CRC";
BA_ "LongName" SG_ 181 LHZCU_10ms_Group32_CRC "LHZCU_10ms_Group32 Checksum";
BA_ "SysSignalName" SG_ 181 LHZCU_10ms_Group32_CRC "LHZCU_10ms_Group32_CRC";
BA_ "CompuMethodName" SG_ 181 LHZCU_10ms_Group32_RC "LHZCU_10ms_Group32_RC";
BA_ "ISignalName" SG_ 181 LHZCU_10ms_Group32_RC "ILHZCU_10ms_Group32_RC";
BA_ "LongName" SG_ 181 LHZCU_10ms_Group32_RC "LHZCU_10ms_Group32 Alive Rolling Counter";
BA_ "SysSignalName" SG_ 181 LHZCU_10ms_Group32_RC "LHZCU_10ms_Group32_RC";
BA_ "CompuMethodName" SG_ 181 LHZCU_10ms_Group32_Reserved1 "LHZCU_10ms_Group32_Reserved1";
BA_ "GenSigStartValue" SG_ 181 LHZCU_10ms_Group32_Reserved1 15;
BA_ "ISignalName" SG_ 181 LHZCU_10ms_Group32_Reserved1 "ILHZCU_10ms_Group32_Reserved1";
BA_ "SysSignalName" SG_ 181 LHZCU_10ms_Group32_Reserved1 "LHZCU_10ms_Group32_Reserved1";
BA_ "CompuMethodName" SG_ 181 BrkLghtSwReq "BrkLghtSwReq";
BA_ "ISignalName" SG_ 181 BrkLghtSwReq "IBrkLghtSwReq";
BA_ "LongName" SG_ 181 BrkLghtSwReq "Brake_Light_Switch_Request";
BA_ "SysSignalName" SG_ 181 BrkLghtSwReq "BrkLghtSwReq";
BA_ "CompuMethodName" SG_ 181 SideLghtOnReq "SideLghtOnReq";
BA_ "ISignalName" SG_ 181 SideLghtOnReq "ISideLghtOnReq";
BA_ "LongName" SG_ 181 SideLghtOnReq "Side Ligth On Request";
BA_ "SysSignalName" SG_ 181 SideLghtOnReq "SideLghtOnReq";
BA_ "CompuMethodName" SG_ 181 MainBeamLghtSwReq "MainBeamLghtSwReq";
BA_ "ISignalName" SG_ 181 MainBeamLghtSwReq "IMainBeamLghtSwReq";
BA_ "LongName" SG_ 181 MainBeamLghtSwReq "Main_beam_Light_switch_request";
BA_ "SysSignalName" SG_ 181 MainBeamLghtSwReq "MainBeamLghtSwReq";
BA_ "CompuMethodName" SG_ 181 LHZCU_10ms_Group32_Reserved2 "LHZCU_10ms_Group32_Reserved2";
BA_ "GenSigStartValue" SG_ 181 LHZCU_10ms_Group32_Reserved2 7;
BA_ "ISignalName" SG_ 181 LHZCU_10ms_Group32_Reserved2 "ILHZCU_10ms_Group32_Reserved2";
BA_ "SysSignalName" SG_ 181 LHZCU_10ms_Group32_Reserved2 "LHZCU_10ms_Group32_Reserved2";
BA_ "CompuMethodName" SG_ 181 DrvrReqGearShftPos "DrvrReqGearShftPos";
BA_ "GenSigStartValue" SG_ 181 DrvrReqGearShftPos 8;
BA_ "ISignalName" SG_ 181 DrvrReqGearShftPos "IDrvrReqGearShftPos";
BA_ "SysSignalName" SG_ 181 DrvrReqGearShftPos "DrvrReqGearShftPos";
BA_ "CompuMethodName" SG_ 181 LHZCU_10ms_Group32_Reserved3 "LHZCU_10ms_Group32_Reserved3";
BA_ "GenSigStartValue" SG_ 181 LHZCU_10ms_Group32_Reserved3 1;
BA_ "ISignalName" SG_ 181 LHZCU_10ms_Group32_Reserved3 "ILHZCU_10ms_Group32_Reserved3";
BA_ "SysSignalName" SG_ 181 LHZCU_10ms_Group32_Reserved3 "LHZCU_10ms_Group32_Reserved3";
BA_ "CompuMethodName" SG_ 181 RrFogLightOnReq "RrFogLightOnReq";
BA_ "ISignalName" SG_ 181 RrFogLightOnReq "IRrFogLightOnReq";
BA_ "LongName" SG_ 181 RrFogLightOnReq "Rear Fog Light On Request";
BA_ "SysSignalName" SG_ 181 RrFogLightOnReq "RrFogLightOnReq";
BA_ "CompuMethodName" SG_ 181 RDayTimeRunningLghtCtrl "RDayTimeRunningLghtCtrl";
BA_ "ISignalName" SG_ 181 RDayTimeRunningLghtCtrl "IRDayTimeRunningLghtCtrl";
BA_ "LongName" SG_ 181 RDayTimeRunningLghtCtrl "Right_day time running ligth control";
BA_ "SysSignalName" SG_ 181 RDayTimeRunningLghtCtrl "RDayTimeRunningLghtCtrl";
BA_ "CompuMethodName" SG_ 181 LDayTimeRunningLghtCtrl "LDayTimeRunningLghtCtrl";
BA_ "ISignalName" SG_ 181 LDayTimeRunningLghtCtrl "ILDayTimeRunningLghtCtrl";
BA_ "LongName" SG_ 181 LDayTimeRunningLghtCtrl "Left_day time running ligth control";
BA_ "SysSignalName" SG_ 181 LDayTimeRunningLghtCtrl "LDayTimeRunningLghtCtrl";
BA_ "CompuMethodName" SG_ 181 EleccTrRngReq "EleccTrRngReq";
BA_ "ISignalName" SG_ 181 EleccTrRngReq "IEleccTrRngReq";
BA_ "SysSignalName" SG_ 181 EleccTrRngReq "EleccTrRngReq";
BA_ "CompuMethodName" SG_ 181 DrvrReqGearShftPosInvs "DrvrReqGearShftPosInvs";
BA_ "GenSigStartValue" SG_ 181 DrvrReqGearShftPosInvs 7;
BA_ "ISignalName" SG_ 181 DrvrReqGearShftPosInvs "IDrvrReqGearShftPosInvs";
BA_ "SysSignalName" SG_ 181 DrvrReqGearShftPosInvs "DrvrReqGearShftPosInvs";
BA_ "CompuMethodName" SG_ 181 DircnLghtOnReq_LHZCU "DircnLghtOnReq_LHZCU";
BA_ "ISignalName" SG_ 181 DircnLghtOnReq_LHZCU "IDircnLghtOnReq_LHZCU";
BA_ "LongName" SG_ 181 DircnLghtOnReq_LHZCU "Direction Light On Request";
BA_ "SysSignalName" SG_ 181 DircnLghtOnReq_LHZCU "DircnLghtOnReq_LHZCU";
BA_ "CompuMethodName" SG_ 181 SCUDrvnIntrvnPos "SCUDrvnIntrvnPos";
BA_ "ISignalName" SG_ 181 SCUDrvnIntrvnPos "ISCUDrvnIntrvnPos";
BA_ "SysSignalName" SG_ 181 SCUDrvnIntrvnPos "SCUDrvnIntrvnPos";
BA_ "CompuMethodName" SG_ 181 LHZCU_10ms_Group32_Reserved4 "LHZCU_10ms_Group32_Reserved4";
BA_ "GenSigStartValue" SG_ 181 LHZCU_10ms_Group32_Reserved4 1;
BA_ "ISignalName" SG_ 181 LHZCU_10ms_Group32_Reserved4 "ILHZCU_10ms_Group32_Reserved4";
BA_ "SysSignalName" SG_ 181 LHZCU_10ms_Group32_Reserved4 "LHZCU_10ms_Group32_Reserved4";
BA_ "CompuMethodName" SG_ 181 SCUShftLvrPosIncnstntFlag "SCUShftLvrPosIncnstntFlag";
BA_ "ISignalName" SG_ 181 SCUShftLvrPosIncnstntFlag "ISCUShftLvrPosIncnstntFlag";
BA_ "SysSignalName" SG_ 181 SCUShftLvrPosIncnstntFlag "SCUShftLvrPosIncnstntFlag";
BA_ "CompuMethodName" SG_ 181 SCUShftLvrPosTrgt "SCUShftLvrPosTrgt";
BA_ "ISignalName" SG_ 181 SCUShftLvrPosTrgt "ISCUShftLvrPosTrgt";
BA_ "SysSignalName" SG_ 181 SCUShftLvrPosTrgt "SCUShftLvrPosTrgt";
BA_ "CompuMethodName" SG_ 181 SCUExtdShifterActrPos "SCUExtdShifterActrPos";
BA_ "ISignalName" SG_ 181 SCUExtdShifterActrPos "ISCUExtdShifterActrPos";
BA_ "SysSignalName" SG_ 181 SCUExtdShifterActrPos "SCUExtdShifterActrPos";
BA_ "CompuMethodName" SG_ 181 SCUTapUpDwnSwStaInvsn "SCUTapUpDwnSwStaInvsn";
BA_ "GenSigStartValue" SG_ 181 SCUTapUpDwnSwStaInvsn 3;
BA_ "ISignalName" SG_ 181 SCUTapUpDwnSwStaInvsn "ISCUTapUpDwnSwStaInvsn";
BA_ "SysSignalName" SG_ 181 SCUTapUpDwnSwStaInvsn "SCUTapUpDwnSwStaInvsn";
BA_ "CompuMethodName" SG_ 181 SCUTapUpDwnSwSta "SCUTapUpDwnSwSta";
BA_ "ISignalName" SG_ 181 SCUTapUpDwnSwSta "ISCUTapUpDwnSwSta";
BA_ "SysSignalName" SG_ 181 SCUTapUpDwnSwSta "SCUTapUpDwnSwSta";
BA_ "CompuMethodName" SG_ 181 SCUParkActrSts "SCUParkActrSts";
BA_ "ISignalName" SG_ 181 SCUParkActrSts "ISCUParkActrSts";
BA_ "SysSignalName" SG_ 181 SCUParkActrSts "SCUParkActrSts";
BA_ "CompuMethodName" SG_ 181 SCUActrMvmntSts "SCUActrMvmntSts";
BA_ "ISignalName" SG_ 181 SCUActrMvmntSts "ISCUActrMvmntSts";
BA_ "SysSignalName" SG_ 181 SCUActrMvmntSts "SCUActrMvmntSts";
BA_ "CompuMethodName" SG_ 181 SmrtKey4LoctnResp "SmrtKey4LoctnResp";
BA_ "ISignalName" SG_ 181 SmrtKey4LoctnResp "ISmrtKey4LoctnResp";
BA_ "LongName" SG_ 181 SmrtKey4LoctnResp "Smart Key 4 Location Response";
BA_ "SysSignalName" SG_ 181 SmrtKey4LoctnResp "SmrtKey4LoctnResp";
BA_ "CompuMethodName" SG_ 181 SmrtKeyLoctnProc "SmrtKeyLoctnProc";
BA_ "ISignalName" SG_ 181 SmrtKeyLoctnProc "ISmrtKeyLoctnProc";
BA_ "LongName" SG_ 181 SmrtKeyLoctnProc "Smart Key Location Process";
BA_ "SysSignalName" SG_ 181 SmrtKeyLoctnProc "SmrtKeyLoctnProc";
BA_ "CompuMethodName" SG_ 181 LHZCU_10ms_Group32_Reserved5 "LHZCU_10ms_Group32_Reserved5";
BA_ "GenSigStartValue" SG_ 181 LHZCU_10ms_Group32_Reserved5 7;
BA_ "ISignalName" SG_ 181 LHZCU_10ms_Group32_Reserved5 "ILHZCU_10ms_Group32_Reserved5";
BA_ "SysSignalName" SG_ 181 LHZCU_10ms_Group32_Reserved5 "LHZCU_10ms_Group32_Reserved5";
BA_ "CompuMethodName" SG_ 181 LHZCUWKSTS "LHZCUWKSTS";
BA_ "ISignalName" SG_ 181 LHZCUWKSTS "ILHZCUWKSTS";
BA_ "LongName" SG_ 181 LHZCUWKSTS "LHZCU WAKEUP STATUS";
BA_ "SysSignalName" SG_ 181 LHZCUWKSTS "LHZCUWKSTS";
BA_ "CompuMethodName" SG_ 181 SmrtKeyLoctnFlrRsn "SmrtKeyLoctnFlrRsn";
BA_ "ISignalName" SG_ 181 SmrtKeyLoctnFlrRsn "ISmrtKeyLoctnFlrRsn";
BA_ "LongName" SG_ 181 SmrtKeyLoctnFlrRsn "Smart Key Search Failure Reason";
BA_ "SysSignalName" SG_ 181 SmrtKeyLoctnFlrRsn "SmrtKeyLoctnFlrRsn";
BA_ "CompuMethodName" SG_ 181 LHZCU_10ms_Group32_Reserved6 "LHZCU_10ms_Group32_Reserved6";
BA_ "GenSigStartValue" SG_ 181 LHZCU_10ms_Group32_Reserved6 255;
BA_ "ISignalName" SG_ 181 LHZCU_10ms_Group32_Reserved6 "ILHZCU_10ms_Group32_Reserved6";
BA_ "SysSignalName" SG_ 181 LHZCU_10ms_Group32_Reserved6 "LHZCU_10ms_Group32_Reserved6";
BA_ "CompuMethodName" SG_ 181 LHZCU_10ms_Group32_Reserved7 "LHZCU_10ms_Group32_Reserved7";
BA_ "GenSigStartValue" SG_ 181 LHZCU_10ms_Group32_Reserved7 255;
BA_ "ISignalName" SG_ 181 LHZCU_10ms_Group32_Reserved7 "ILHZCU_10ms_Group32_Reserved7";
BA_ "SysSignalName" SG_ 181 LHZCU_10ms_Group32_Reserved7 "LHZCU_10ms_Group32_Reserved7";
BA_ "CompuMethodName" SG_ 1149 TPMSAutoLoctnCm "TPMSAutoLoctnCm";
BA_ "GenSigStartValue" SG_ 1149 TPMSAutoLoctnCm 1;
BA_ "ISignalName" SG_ 1149 TPMSAutoLoctnCm "ITPMSAutoLoctnCm";
BA_ "LongName" SG_ 1149 TPMSAutoLoctnCm "Tire_Pressure_Monitor_System_Auto_Location_Complete";
BA_ "SysSignalName" SG_ 1149 TPMSAutoLoctnCm "TPMSAutoLoctnCm";
BA_ "CompuMethodName" SG_ 1149 FRTireSts "FRTireSts";
BA_ "ISignalName" SG_ 1149 FRTireSts "IFRTireSts";
BA_ "LongName" SG_ 1149 FRTireSts "Front_Right_Tire_Status";
BA_ "SysSignalName" SG_ 1149 FRTireSts "FRTireSts";
BA_ "CompuMethodName" SG_ 1149 FLTireSts "FLTireSts";
BA_ "ISignalName" SG_ 1149 FLTireSts "IFLTireSts";
BA_ "LongName" SG_ 1149 FLTireSts "Front_Left_Tire_Status";
BA_ "SysSignalName" SG_ 1149 FLTireSts "FLTireSts";
BA_ "CompuMethodName" SG_ 1149 TPMSIdficnLrnCm "TPMSIdficnLrnCm";
BA_ "GenSigStartValue" SG_ 1149 TPMSIdficnLrnCm 1;
BA_ "ISignalName" SG_ 1149 TPMSIdficnLrnCm "ITPMSIdficnLrnCm";
BA_ "LongName" SG_ 1149 TPMSIdficnLrnCm "Tire_Pressure_Monitor_System_Identification_Learn_Complete";
BA_ "SysSignalName" SG_ 1149 TPMSIdficnLrnCm "TPMSIdficnLrnCm";
BA_ "CompuMethodName" SG_ 1149 RRTireSts "RRTireSts";
BA_ "ISignalName" SG_ 1149 RRTireSts "IRRTireSts";
BA_ "LongName" SG_ 1149 RRTireSts "Rear_Right_Tire_Status";
BA_ "SysSignalName" SG_ 1149 RRTireSts "RRTireSts";
BA_ "CompuMethodName" SG_ 1149 RLTireSts "RLTireSts";
BA_ "ISignalName" SG_ 1149 RLTireSts "IRLTireSts";
BA_ "LongName" SG_ 1149 RLTireSts "Rear_Left_Tire_Status";
BA_ "SysSignalName" SG_ 1149 RLTireSts "RLTireSts";
BA_ "CompuMethodName" SG_ 1149 RRTirePrs "RRTirePrs";
BA_ "GenSigStartValue" SG_ 1149 RRTirePrs 55;
BA_ "ISignalName" SG_ 1149 RRTirePrs "IRRTirePrs";
BA_ "LongName" SG_ 1149 RRTirePrs "Rear Right Tire Pressure";
BA_ "SysSignalName" SG_ 1149 RRTirePrs "RRTirePrs";
BA_ "CompuMethodName" SG_ 1149 TPMSWntrMdA "TPMSWntrMdA";
BA_ "ISignalName" SG_ 1149 TPMSWntrMdA "ITPMSWntrMdA";
BA_ "LongName" SG_ 1149 TPMSWntrMdA "Tire Pressure Monitor System Winter Mode Active";
BA_ "SysSignalName" SG_ 1149 TPMSWntrMdA "TPMSWntrMdA";
BA_ "CompuMethodName" SG_ 1149 RLTirePrs "RLTirePrs";
BA_ "GenSigStartValue" SG_ 1149 RLTirePrs 55;
BA_ "ISignalName" SG_ 1149 RLTirePrs "IRLTirePrs";
BA_ "LongName" SG_ 1149 RLTirePrs "Rear Left Tire Pressure";
BA_ "SysSignalName" SG_ 1149 RLTirePrs "RLTirePrs";
BA_ "CompuMethodName" SG_ 1149 RLTirePrsV "RLTirePrsV";
BA_ "ISignalName" SG_ 1149 RLTirePrsV "IRLTirePrsV";
BA_ "LongName" SG_ 1149 RLTirePrsV "Rear_Left_Tire_Pressure_Validity";
BA_ "SysSignalName" SG_ 1149 RLTirePrsV "RLTirePrsV";
BA_ "CompuMethodName" SG_ 1149 FRTirePrs "FRTirePrs";
BA_ "GenSigStartValue" SG_ 1149 FRTirePrs 55;
BA_ "ISignalName" SG_ 1149 FRTirePrs "IFRTirePrs";
BA_ "LongName" SG_ 1149 FRTirePrs "Front Right Tire Pressure";
BA_ "SysSignalName" SG_ 1149 FRTirePrs "FRTirePrs";
BA_ "CompuMethodName" SG_ 1149 FRTirePrsV "FRTirePrsV";
BA_ "ISignalName" SG_ 1149 FRTirePrsV "IFRTirePrsV";
BA_ "LongName" SG_ 1149 FRTirePrsV "Front_Right_Tire_Pressure_Validity";
BA_ "SysSignalName" SG_ 1149 FRTirePrsV "FRTirePrsV";
BA_ "CompuMethodName" SG_ 1149 RRTirePrsV "RRTirePrsV";
BA_ "ISignalName" SG_ 1149 RRTirePrsV "IRRTirePrsV";
BA_ "LongName" SG_ 1149 RRTirePrsV "Rear_Right_Tire_Pressure_Validity";
BA_ "SysSignalName" SG_ 1149 RRTirePrsV "RRTirePrsV";
BA_ "CompuMethodName" SG_ 1149 FLTirePrs "FLTirePrs";
BA_ "GenSigStartValue" SG_ 1149 FLTirePrs 55;
BA_ "ISignalName" SG_ 1149 FLTirePrs "IFLTirePrs";
BA_ "LongName" SG_ 1149 FLTirePrs "Front Left Tire Pressure";
BA_ "SysSignalName" SG_ 1149 FLTirePrs "FLTirePrs";
BA_ "CompuMethodName" SG_ 1149 FLTirePrsV "FLTirePrsV";
BA_ "ISignalName" SG_ 1149 FLTirePrsV "IFLTirePrsV";
BA_ "LongName" SG_ 1149 FLTirePrsV "Front_Left_Tire_Pressure_Validity";
BA_ "SysSignalName" SG_ 1149 FLTirePrsV "FLTirePrsV";
BA_ "CompuMethodName" SG_ 1148 FLTireTemV "FLTireTemV";
BA_ "ISignalName" SG_ 1148 FLTireTemV "IFLTireTemV";
BA_ "LongName" SG_ 1148 FLTireTemV "Front Left Tire Temperature Validity";
BA_ "SysSignalName" SG_ 1148 FLTireTemV "FLTireTemV";
BA_ "CompuMethodName" SG_ 1148 FLTireTem "FLTireTem";
BA_ "GenSigStartValue" SG_ 1148 FLTireTem 45;
BA_ "ISignalName" SG_ 1148 FLTireTem "IFLTireTem";
BA_ "LongName" SG_ 1148 FLTireTem "Front Left Tire Temperature";
BA_ "SysSignalName" SG_ 1148 FLTireTem "FLTireTem";
BA_ "CompuMethodName" SG_ 1148 FRTireTemV "FRTireTemV";
BA_ "ISignalName" SG_ 1148 FRTireTemV "IFRTireTemV";
BA_ "LongName" SG_ 1148 FRTireTemV "Front Right Tire Temperature Validity";
BA_ "SysSignalName" SG_ 1148 FRTireTemV "FRTireTemV";
BA_ "CompuMethodName" SG_ 1148 FRTireTem "FRTireTem";
BA_ "GenSigStartValue" SG_ 1148 FRTireTem 45;
BA_ "ISignalName" SG_ 1148 FRTireTem "IFRTireTem";
BA_ "LongName" SG_ 1148 FRTireTem "Front Right Tire Temperature";
BA_ "SysSignalName" SG_ 1148 FRTireTem "FRTireTem";
BA_ "CompuMethodName" SG_ 1148 RLTireTemV "RLTireTemV";
BA_ "ISignalName" SG_ 1148 RLTireTemV "IRLTireTemV";
BA_ "LongName" SG_ 1148 RLTireTemV "Rear Left Tire Temperature Validity";
BA_ "SysSignalName" SG_ 1148 RLTireTemV "RLTireTemV";
BA_ "CompuMethodName" SG_ 1148 RLTireTem "RLTireTem";
BA_ "GenSigStartValue" SG_ 1148 RLTireTem 45;
BA_ "ISignalName" SG_ 1148 RLTireTem "IRLTireTem";
BA_ "LongName" SG_ 1148 RLTireTem "Rear Left Tire Temperature";
BA_ "SysSignalName" SG_ 1148 RLTireTem "RLTireTem";
BA_ "CompuMethodName" SG_ 1148 RRTireTemV "RRTireTemV";
BA_ "ISignalName" SG_ 1148 RRTireTemV "IRRTireTemV";
BA_ "LongName" SG_ 1148 RRTireTemV "Rear Right Tire Temperature Validity";
BA_ "SysSignalName" SG_ 1148 RRTireTemV "RRTireTemV";
BA_ "CompuMethodName" SG_ 1148 RRTireTem "RRTireTem";
BA_ "GenSigStartValue" SG_ 1148 RRTireTem 45;
BA_ "ISignalName" SG_ 1148 RRTireTem "IRRTireTem";
BA_ "LongName" SG_ 1148 RRTireTem "Rear Right Tire Temperature";
BA_ "SysSignalName" SG_ 1148 RRTireTem "RRTireTem";
BA_ "CompuMethodName" SG_ 638 LHZCU_50ms_Group24_CRC "LHZCU_50ms_Group24_CRC";
BA_ "ISignalName" SG_ 638 LHZCU_50ms_Group24_CRC "ILHZCU_50ms_Group24_CRC";
BA_ "SysSignalName" SG_ 638 LHZCU_50ms_Group24_CRC "LHZCU_50ms_Group24_CRC";
BA_ "CompuMethodName" SG_ 638 LHZCU_50ms_Group24_RC "LHZCU_50ms_Group24_RC";
BA_ "ISignalName" SG_ 638 LHZCU_50ms_Group24_RC "ILHZCU_50ms_Group24_RC";
BA_ "SysSignalName" SG_ 638 LHZCU_50ms_Group24_RC "LHZCU_50ms_Group24_RC";
BA_ "CompuMethodName" SG_ 638 VehHzrdMdSts "VehHzrdMdSts";
BA_ "ISignalName" SG_ 638 VehHzrdMdSts "IVehHzrdMdSts";
BA_ "LongName" SG_ 638 VehHzrdMdSts "Vehicle_Hazard_Mode_Status";
BA_ "SysSignalName" SG_ 638 VehHzrdMdSts "VehHzrdMdSts";
BA_ "CompuMethodName" SG_ 638 LHZCU_50ms_Group24_Reserved23 "LHZCU_50ms_Group24_Reserved23";
BA_ "GenSigStartValue" SG_ 638 LHZCU_50ms_Group24_Reserved23 255;
BA_ "ISignalName" SG_ 638 LHZCU_50ms_Group24_Reserved23 "ILHZCU_50ms_Group24_Reserved23";
BA_ "SysSignalName" SG_ 638 LHZCU_50ms_Group24_Reserved23 "LHZCU_50ms_Group24_Reserved23";
BA_ "CompuMethodName" SG_ 638 VehIlluminateCtrlCmd "VehIlluminateCtrlCmd";
BA_ "ISignalName" SG_ 638 VehIlluminateCtrlCmd "IVehIlluminateCtrlCmd";
BA_ "LongName" SG_ 638 VehIlluminateCtrlCmd "Vehicle Illuminate Control Command";
BA_ "SysSignalName" SG_ 638 VehIlluminateCtrlCmd "VehIlluminateCtrlCmd";
BA_ "CompuMethodName" SG_ 638 LHZCU_50ms_Group24_Reserved31 "LHZCU_50ms_Group24_Reserved31";
BA_ "GenSigStartValue" SG_ 638 LHZCU_50ms_Group24_Reserved31 127;
BA_ "ISignalName" SG_ 638 LHZCU_50ms_Group24_Reserved31 "ILHZCU_50ms_Group24_Reserved31";
BA_ "SysSignalName" SG_ 638 LHZCU_50ms_Group24_Reserved31 "LHZCU_50ms_Group24_Reserved31";
BA_ "CompuMethodName" SG_ 638 BrkLghtSta "BrkLghtSta";
BA_ "ISignalName" SG_ 638 BrkLghtSta "IBrkLghtSta";
BA_ "LongName" SG_ 638 BrkLghtSta "Brake_Light_State";
BA_ "SysSignalName" SG_ 638 BrkLghtSta "BrkLghtSta";
BA_ "CompuMethodName" SG_ 638 LHZCU_50ms_Group24_Reserved39 "LHZCU_50ms_Group24_Reserved39";
BA_ "GenSigStartValue" SG_ 638 LHZCU_50ms_Group24_Reserved39 127;
BA_ "ISignalName" SG_ 638 LHZCU_50ms_Group24_Reserved39 "ILHZCU_50ms_Group24_Reserved39";
BA_ "SysSignalName" SG_ 638 LHZCU_50ms_Group24_Reserved39 "LHZCU_50ms_Group24_Reserved39";
BA_ "CompuMethodName" SG_ 638 BrkLghtFltSta "BrkLghtFltSta";
BA_ "ISignalName" SG_ 638 BrkLghtFltSta "IBrkLghtFltSta";
BA_ "LongName" SG_ 638 BrkLghtFltSta "Brake_Light_Fault_State";
BA_ "SysSignalName" SG_ 638 BrkLghtFltSta "BrkLghtFltSta";
BA_ "CompuMethodName" SG_ 638 LHZCU_50ms_Group24_Reserved47 "LHZCU_50ms_Group24_Reserved47";
BA_ "GenSigStartValue" SG_ 638 LHZCU_50ms_Group24_Reserved47 127;
BA_ "ISignalName" SG_ 638 LHZCU_50ms_Group24_Reserved47 "ILHZCU_50ms_Group24_Reserved47";
BA_ "SysSignalName" SG_ 638 LHZCU_50ms_Group24_Reserved47 "LHZCU_50ms_Group24_Reserved47";
BA_ "CompuMethodName" SG_ 638 LHZCU_50ms_Group24_Reserved49 "LHZCU_50ms_Group24_Reserved49";
BA_ "GenSigStartValue" SG_ 638 LHZCU_50ms_Group24_Reserved49 7;
BA_ "ISignalName" SG_ 638 LHZCU_50ms_Group24_Reserved49 "ILHZCU_50ms_Group24_Reserved49";
BA_ "SysSignalName" SG_ 638 LHZCU_50ms_Group24_Reserved49 "LHZCU_50ms_Group24_Reserved49";
BA_ "CompuMethodName" SG_ 638 DircnLghtSts "DircnLghtSts";
BA_ "ISignalName" SG_ 638 DircnLghtSts "IDircnLghtSts";
BA_ "LongName" SG_ 638 DircnLghtSts "Direction_Light_Status";
BA_ "SysSignalName" SG_ 638 DircnLghtSts "DircnLghtSts";
BA_ "CompuMethodName" SG_ 638 DircnLghtMdSts "DircnLghtMdSts";
BA_ "ISignalName" SG_ 638 DircnLghtMdSts "IDircnLghtMdSts";
BA_ "LongName" SG_ 638 DircnLghtMdSts "Direction_Light_Mode_Status";
BA_ "SysSignalName" SG_ 638 DircnLghtMdSts "DircnLghtMdSts";
BA_ "CompuMethodName" SG_ 638 LHZCU_50ms_Group24_Reserved55 "LHZCU_50ms_Group24_Reserved55";
BA_ "GenSigStartValue" SG_ 638 LHZCU_50ms_Group24_Reserved55 3;
BA_ "ISignalName" SG_ 638 LHZCU_50ms_Group24_Reserved55 "ILHZCU_50ms_Group24_Reserved55";
BA_ "SysSignalName" SG_ 638 LHZCU_50ms_Group24_Reserved55 "LHZCU_50ms_Group24_Reserved55";
BA_ "CompuMethodName" SG_ 638 LHZCU_50ms_Group24_Reserved60 "LHZCU_50ms_Group24_Reserved60";
BA_ "GenSigStartValue" SG_ 638 LHZCU_50ms_Group24_Reserved60 31;
BA_ "ISignalName" SG_ 638 LHZCU_50ms_Group24_Reserved60 "ILHZCU_50ms_Group24_Reserved60";
BA_ "SysSignalName" SG_ 638 LHZCU_50ms_Group24_Reserved60 "LHZCU_50ms_Group24_Reserved60";
BA_ "CompuMethodName" SG_ 638 RRSideLghtCtrl "RRSideLghtCtrl";
BA_ "ISignalName" SG_ 638 RRSideLghtCtrl "IRRSideLghtCtrl";
BA_ "LongName" SG_ 638 RRSideLghtCtrl "Right_Rear_Side_Light_Control";
BA_ "SysSignalName" SG_ 638 RRSideLghtCtrl "RRSideLghtCtrl";
BA_ "CompuMethodName" SG_ 638 RLSideLghtCtrl "RLSideLghtCtrl";
BA_ "ISignalName" SG_ 638 RLSideLghtCtrl "IRLSideLghtCtrl";
BA_ "LongName" SG_ 638 RLSideLghtCtrl "Left_Rear_Side_Light_Control";
BA_ "SysSignalName" SG_ 638 RLSideLghtCtrl "RLSideLghtCtrl";
BA_ "CompuMethodName" SG_ 638 LHZCU_50ms_Group24_Reserved71 "LHZCU_50ms_Group24_Reserved71";
BA_ "GenSigStartValue" SG_ 638 LHZCU_50ms_Group24_Reserved71 255;
BA_ "ISignalName" SG_ 638 LHZCU_50ms_Group24_Reserved71 "ILHZCU_50ms_Group24_Reserved71";
BA_ "SysSignalName" SG_ 638 LHZCU_50ms_Group24_Reserved71 "LHZCU_50ms_Group24_Reserved71";
BA_ "CompuMethodName" SG_ 638 VehSideLghtSts "VehSideLghtSts";
BA_ "ISignalName" SG_ 638 VehSideLghtSts "IVehSideLghtSts";
BA_ "LongName" SG_ 638 VehSideLghtSts "Vehicle Side Light Status";
BA_ "SysSignalName" SG_ 638 VehSideLghtSts "VehSideLghtSts";
BA_ "CompuMethodName" SG_ 638 LHZCU_50ms_Group24_Reserved79 "LHZCU_50ms_Group24_Reserved79";
BA_ "GenSigStartValue" SG_ 638 LHZCU_50ms_Group24_Reserved79 63;
BA_ "ISignalName" SG_ 638 LHZCU_50ms_Group24_Reserved79 "ILHZCU_50ms_Group24_Reserved79";
BA_ "SysSignalName" SG_ 638 LHZCU_50ms_Group24_Reserved79 "LHZCU_50ms_Group24_Reserved79";
BA_ "CompuMethodName" SG_ 638 LHZCU_50ms_Group24_Reserved81 "LHZCU_50ms_Group24_Reserved81";
BA_ "GenSigStartValue" SG_ 638 LHZCU_50ms_Group24_Reserved81 3;
BA_ "ISignalName" SG_ 638 LHZCU_50ms_Group24_Reserved81 "ILHZCU_50ms_Group24_Reserved81";
BA_ "SysSignalName" SG_ 638 LHZCU_50ms_Group24_Reserved81 "LHZCU_50ms_Group24_Reserved81";
BA_ "CompuMethodName" SG_ 638 DircnLghtSwReq "DircnLghtSwReq";
BA_ "ISignalName" SG_ 638 DircnLghtSwReq "IDircnLghtSwReq";
BA_ "LongName" SG_ 638 DircnLghtSwReq "Direction_Light_Switch_Request";
BA_ "SysSignalName" SG_ 638 DircnLghtSwReq "DircnLghtSwReq";
BA_ "CompuMethodName" SG_ 638 LHZCU_50ms_Group24_Reserved87 "LHZCU_50ms_Group24_Reserved87";
BA_ "GenSigStartValue" SG_ 638 LHZCU_50ms_Group24_Reserved87 7;
BA_ "ISignalName" SG_ 638 LHZCU_50ms_Group24_Reserved87 "ILHZCU_50ms_Group24_Reserved87";
BA_ "SysSignalName" SG_ 638 LHZCU_50ms_Group24_Reserved87 "LHZCU_50ms_Group24_Reserved87";
BA_ "CompuMethodName" SG_ 638 LHZCU_50ms_Group24_Reserved95 "LHZCU_50ms_Group24_Reserved95";
BA_ "GenSigStartValue" SG_ 638 LHZCU_50ms_Group24_Reserved95 255;
BA_ "ISignalName" SG_ 638 LHZCU_50ms_Group24_Reserved95 "ILHZCU_50ms_Group24_Reserved95";
BA_ "SysSignalName" SG_ 638 LHZCU_50ms_Group24_Reserved95 "LHZCU_50ms_Group24_Reserved95";
BA_ "CompuMethodName" SG_ 638 LHZCU_50ms_Group24_Reserved103 "LHZCU_50ms_Group24_Reserved103";
BA_ "GenSigStartValue" SG_ 638 LHZCU_50ms_Group24_Reserved103 255;
BA_ "ISignalName" SG_ 638 LHZCU_50ms_Group24_Reserved103 "ILHZCU_50ms_Group24_Reserved103";
BA_ "SysSignalName" SG_ 638 LHZCU_50ms_Group24_Reserved103 "LHZCU_50ms_Group24_Reserved103";
BA_ "CompuMethodName" SG_ 638 DircnLghtFltsts "DircnLghtFltsts";
BA_ "ISignalName" SG_ 638 DircnLghtFltsts "IDircnLghtFltsts";
BA_ "LongName" SG_ 638 DircnLghtFltsts "Direction_Light_Fault_Status";
BA_ "SysSignalName" SG_ 638 DircnLghtFltsts "DircnLghtFltsts";
BA_ "CompuMethodName" SG_ 638 LHZCU_50ms_Group24_Reserved111 "LHZCU_50ms_Group24_Reserved111";
BA_ "GenSigStartValue" SG_ 638 LHZCU_50ms_Group24_Reserved111 63;
BA_ "ISignalName" SG_ 638 LHZCU_50ms_Group24_Reserved111 "ILHZCU_50ms_Group24_Reserved111";
BA_ "SysSignalName" SG_ 638 LHZCU_50ms_Group24_Reserved111 "LHZCU_50ms_Group24_Reserved111";
BA_ "CompuMethodName" SG_ 638 HUDLkngAmbtLghtLvlByLux "HUDLkngAmbtLghtLvlByLux";
BA_ "ISignalName" SG_ 638 HUDLkngAmbtLghtLvlByLux "IHUDLkngAmbtLghtLvlByLux";
BA_ "LongName" SG_ 638 HUDLkngAmbtLghtLvlByLux "HUD Looking Ambient Light Level By Lux";
BA_ "SysSignalName" SG_ 638 HUDLkngAmbtLghtLvlByLux "HUDLkngAmbtLghtLvlByLux";
BA_ "CompuMethodName" SG_ 638 LHZCU_50ms_Group24_Reserved121 "LHZCU_50ms_Group24_Reserved121";
BA_ "GenSigStartValue" SG_ 638 LHZCU_50ms_Group24_Reserved121 3;
BA_ "ISignalName" SG_ 638 LHZCU_50ms_Group24_Reserved121 "ILHZCU_50ms_Group24_Reserved121";
BA_ "SysSignalName" SG_ 638 LHZCU_50ms_Group24_Reserved121 "LHZCU_50ms_Group24_Reserved121";
BA_ "CompuMethodName" SG_ 638 LHZCU_50ms_Group24_Reserved135 "LHZCU_50ms_Group24_Reserved135";
BA_ "GenSigStartValue" SG_ 638 LHZCU_50ms_Group24_Reserved135 255;
BA_ "ISignalName" SG_ 638 LHZCU_50ms_Group24_Reserved135 "ILHZCU_50ms_Group24_Reserved135";
BA_ "SysSignalName" SG_ 638 LHZCU_50ms_Group24_Reserved135 "LHZCU_50ms_Group24_Reserved135";
BA_ "CompuMethodName" SG_ 638 LHZCU_50ms_Group24_Reserved143 "LHZCU_50ms_Group24_Reserved143";
BA_ "GenSigStartValue" SG_ 638 LHZCU_50ms_Group24_Reserved143 255;
BA_ "ISignalName" SG_ 638 LHZCU_50ms_Group24_Reserved143 "ILHZCU_50ms_Group24_Reserved143";
BA_ "SysSignalName" SG_ 638 LHZCU_50ms_Group24_Reserved143 "LHZCU_50ms_Group24_Reserved143";
BA_ "CompuMethodName" SG_ 638 LHZCU_50ms_Group24_Reserved151 "LHZCU_50ms_Group24_Reserved151";
BA_ "GenSigStartValue" SG_ 638 LHZCU_50ms_Group24_Reserved151 255;
BA_ "ISignalName" SG_ 638 LHZCU_50ms_Group24_Reserved151 "ILHZCU_50ms_Group24_Reserved151";
BA_ "SysSignalName" SG_ 638 LHZCU_50ms_Group24_Reserved151 "LHZCU_50ms_Group24_Reserved151";
BA_ "CompuMethodName" SG_ 638 LHZCU_50ms_Group24_Reserved159 "LHZCU_50ms_Group24_Reserved159";
BA_ "GenSigStartValue" SG_ 638 LHZCU_50ms_Group24_Reserved159 255;
BA_ "ISignalName" SG_ 638 LHZCU_50ms_Group24_Reserved159 "ILHZCU_50ms_Group24_Reserved159";
BA_ "SysSignalName" SG_ 638 LHZCU_50ms_Group24_Reserved159 "LHZCU_50ms_Group24_Reserved159";
BA_ "CompuMethodName" SG_ 745 AutoMainBeamLghtOn "AutoMainBeamLghtOn";
BA_ "ISignalName" SG_ 745 AutoMainBeamLghtOn "IAutoMainBeamLghtOn";
BA_ "LongName" SG_ 745 AutoMainBeamLghtOn "Auto_Main_Beam_Light_On";
BA_ "SysSignalName" SG_ 745 AutoMainBeamLghtOn "AutoMainBeamLghtOn";
BA_ "CompuMethodName" SG_ 745 MainBeamLghtOn "MainBeamLghtOn";
BA_ "ISignalName" SG_ 745 MainBeamLghtOn "IMainBeamLghtOn";
BA_ "LongName" SG_ 745 MainBeamLghtOn "Main_Beam_Light_On";
BA_ "SysSignalName" SG_ 745 MainBeamLghtOn "MainBeamLghtOn";
BA_ "CompuMethodName" SG_ 745 LRevsLghtSts "LRevsLghtSts";
BA_ "ISignalName" SG_ 745 LRevsLghtSts "ILRevsLghtSts";
BA_ "LongName" SG_ 745 LRevsLghtSts "LReverse_Light_Status";
BA_ "SysSignalName" SG_ 745 LRevsLghtSts "LRevsLghtSts";
BA_ "CompuMethodName" SG_ 745 LBrkLghtSts "LBrkLghtSts";
BA_ "ISignalName" SG_ 745 LBrkLghtSts "ILBrkLghtSts";
BA_ "LongName" SG_ 745 LBrkLghtSts "Left Brake_Light_Status";
BA_ "SysSignalName" SG_ 745 LBrkLghtSts "LBrkLghtSts";
BA_ "CompuMethodName" SG_ 745 ROtsdMirVertSwActReq "ROtsdMirVertSwActReq";
BA_ "ISignalName" SG_ 745 ROtsdMirVertSwActReq "IROtsdMirVertSwActReq";
BA_ "LongName" SG_ 745 ROtsdMirVertSwActReq "Right_Outside_Mirror_Vertical_Switch_Action_Request";
BA_ "SysSignalName" SG_ 745 ROtsdMirVertSwActReq "ROtsdMirVertSwActReq";
BA_ "CompuMethodName" SG_ 745 ROtsdMirHoztSwActReq "ROtsdMirHoztSwActReq";
BA_ "ISignalName" SG_ 745 ROtsdMirHoztSwActReq "IROtsdMirHoztSwActReq";
BA_ "LongName" SG_ 745 ROtsdMirHoztSwActReq "Right_Outside_Mirror_Horizontal_Switch_Action_Request";
BA_ "SysSignalName" SG_ 745 ROtsdMirHoztSwActReq "ROtsdMirHoztSwActReq";
BA_ "CompuMethodName" SG_ 745 RLDoorLckSts "RLDoorLckSts";
BA_ "ISignalName" SG_ 745 RLDoorLckSts "IRLDoorLckSts";
BA_ "LongName" SG_ 745 RLDoorLckSts "Rear Left Door Lock Status";
BA_ "SysSignalName" SG_ 745 RLDoorLckSts "RLDoorLckSts";
BA_ "CompuMethodName" SG_ 745 ZoneRLSideLghtSts "ZoneRLSideLghtSts";
BA_ "ISignalName" SG_ 745 ZoneRLSideLghtSts "IZoneRLSideLghtSts";
BA_ "LongName" SG_ 745 ZoneRLSideLghtSts "Zone Rear Left Side Light State";
BA_ "SysSignalName" SG_ 745 ZoneRLSideLghtSts "ZoneRLSideLghtSts";
BA_ "CompuMethodName" SG_ 745 ZoneFLSideLghtSts "ZoneFLSideLghtSts";
BA_ "ISignalName" SG_ 745 ZoneFLSideLghtSts "IZoneFLSideLghtSts";
BA_ "LongName" SG_ 745 ZoneFLSideLghtSts "Zone Front Left  Side Light State";
BA_ "SysSignalName" SG_ 745 ZoneFLSideLghtSts "ZoneFLSideLghtSts";
BA_ "CompuMethodName" SG_ 745 AllWndAndSrfLazyClsReq "AllWndAndSrfLazyClsReq";
BA_ "ISignalName" SG_ 745 AllWndAndSrfLazyClsReq "IAllWndAndSrfLazyClsReq";
BA_ "LongName" SG_ 745 AllWndAndSrfLazyClsReq "All Window And Sunroof Lazy Close Request";
BA_ "SysSignalName" SG_ 745 AllWndAndSrfLazyClsReq "AllWndAndSrfLazyClsReq";
BA_ "CompuMethodName" SG_ 745 RrSrvcPosReq "RrSrvcPosReq";
BA_ "ISignalName" SG_ 745 RrSrvcPosReq "IRrSrvcPosReq";
BA_ "LongName" SG_ 745 RrSrvcPosReq "Rear Service Position Request";
BA_ "SysSignalName" SG_ 745 RrSrvcPosReq "RrSrvcPosReq";
BA_ "CompuMethodName" SG_ 745 RrWiperFnEnb "RrWiperFnEnb";
BA_ "ISignalName" SG_ 745 RrWiperFnEnb "IRrWiperFnEnb";
BA_ "LongName" SG_ 745 RrWiperFnEnb "Rear Wiper Function Enable";
BA_ "SysSignalName" SG_ 745 RrWiperFnEnb "RrWiperFnEnb";
BA_ "CompuMethodName" SG_ 745 DDSPSelRSwReq "DDSPSelRSwReq";
BA_ "ISignalName" SG_ 745 DDSPSelRSwReq "IDDSPSelRSwReq";
BA_ "LongName" SG_ 745 DDSPSelRSwReq "Driver Door Switch Pack Select Right Switch Request";
BA_ "SysSignalName" SG_ 745 DDSPSelRSwReq "DDSPSelRSwReq";
BA_ "CompuMethodName" SG_ 745 DDSPSelLSwReq "DDSPSelLSwReq";
BA_ "ISignalName" SG_ 745 DDSPSelLSwReq "IDDSPSelLSwReq";
BA_ "LongName" SG_ 745 DDSPSelLSwReq "Driver Door Switch Pack Select Left Switch Request";
BA_ "SysSignalName" SG_ 745 DDSPSelLSwReq "DDSPSelLSwReq";
BA_ "CompuMethodName" SG_ 745 TrdtnSmrtKyLckSwSts "TrdtnSmrtKyLckSwSts";
BA_ "ISignalName" SG_ 745 TrdtnSmrtKyLckSwSts "ITrdtnSmrtKyLckSwSts";
BA_ "LongName" SG_ 745 TrdtnSmrtKyLckSwSts "tradition smart key lock switch status";
BA_ "SysSignalName" SG_ 745 TrdtnSmrtKyLckSwSts "TrdtnSmrtKyLckSwSts";
BA_ "CompuMethodName" SG_ 745 TrdtnSmrtKyUnlckSwSts "TrdtnSmrtKyUnlckSwSts";
BA_ "ISignalName" SG_ 745 TrdtnSmrtKyUnlckSwSts "ITrdtnSmrtKyUnlckSwSts";
BA_ "LongName" SG_ 745 TrdtnSmrtKyUnlckSwSts "tradition smart key unlock switch status";
BA_ "SysSignalName" SG_ 745 TrdtnSmrtKyUnlckSwSts "TrdtnSmrtKyUnlckSwSts";
BA_ "CompuMethodName" SG_ 745 RLSuperLckSts "RLSuperLckSts";
BA_ "ISignalName" SG_ 745 RLSuperLckSts "IRLSuperLckSts";
BA_ "LongName" SG_ 745 RLSuperLckSts "Rear Left SuperLock Status";
BA_ "SysSignalName" SG_ 745 RLSuperLckSts "RLSuperLckSts";
BA_ "CompuMethodName" SG_ 745 FLSuperLckSts "FLSuperLckSts";
BA_ "ISignalName" SG_ 745 FLSuperLckSts "IFLSuperLckSts";
BA_ "LongName" SG_ 745 FLSuperLckSts "Front Left SuperLock Status";
BA_ "SysSignalName" SG_ 745 FLSuperLckSts "FLSuperLckSts";
BA_ "CompuMethodName" SG_ 745 DDSPSelDwnSwReq "DDSPSelDwnSwReq";
BA_ "ISignalName" SG_ 745 DDSPSelDwnSwReq "IDDSPSelDwnSwReq";
BA_ "LongName" SG_ 745 DDSPSelDwnSwReq "Driver Door Switch Pack Select Down Switch Request";
BA_ "SysSignalName" SG_ 745 DDSPSelDwnSwReq "DDSPSelDwnSwReq";
BA_ "CompuMethodName" SG_ 745 DDSPSelUpSwReq "DDSPSelUpSwReq";
BA_ "ISignalName" SG_ 745 DDSPSelUpSwReq "IDDSPSelUpSwReq";
BA_ "LongName" SG_ 745 DDSPSelUpSwReq "Driver Door Switch Pack Select Up Switch Request";
BA_ "SysSignalName" SG_ 745 DDSPSelUpSwReq "DDSPSelUpSwReq";
BA_ "CompuMethodName" SG_ 745 DDSPROtsdMirSeldSwA "DDSPROtsdMirSeldSwA";
BA_ "ISignalName" SG_ 745 DDSPROtsdMirSeldSwA "IDDSPROtsdMirSeldSwA";
BA_ "LongName" SG_ 745 DDSPROtsdMirSeldSwA "Driver Door Switch Pack Right Outside Mirror Selected Switch Active";
BA_ "SysSignalName" SG_ 745 DDSPROtsdMirSeldSwA "DDSPROtsdMirSeldSwA";
BA_ "CompuMethodName" SG_ 745 DDSPLOtsdMirSeldSwA "DDSPLOtsdMirSeldSwA";
BA_ "ISignalName" SG_ 745 DDSPLOtsdMirSeldSwA "IDDSPLOtsdMirSeldSwA";
BA_ "LongName" SG_ 745 DDSPLOtsdMirSeldSwA "Driver Door Switch Pack Left Outside Mirror Selected Switch Active";
BA_ "SysSignalName" SG_ 745 DDSPLOtsdMirSeldSwA "DDSPLOtsdMirSeldSwA";
BA_ "CompuMethodName" SG_ 745 DDSPOtsdMirFoldSwReq "DDSPOtsdMirFoldSwReq";
BA_ "ISignalName" SG_ 745 DDSPOtsdMirFoldSwReq "IDDSPOtsdMirFoldSwReq";
BA_ "LongName" SG_ 745 DDSPOtsdMirFoldSwReq "Driver Door Switch Pack Outside Mirror Fold Switch Request";
BA_ "SysSignalName" SG_ 745 DDSPOtsdMirFoldSwReq "DDSPOtsdMirFoldSwReq";
BA_ "CompuMethodName" SG_ 640 TrdtnKeyBtnSts "TrdtnKeyBtnSts";
BA_ "ISignalName" SG_ 640 TrdtnKeyBtnSts "ITrdtnKeyBtnSts";
BA_ "LongName" SG_ 640 TrdtnKeyBtnSts "Tradition Key Button Status";
BA_ "SysSignalName" SG_ 640 TrdtnKeyBtnSts "TrdtnKeyBtnSts";
BA_ "CompuMethodName" SG_ 640 SmrtKey1BtnSts "SmrtKey1BtnSts";
BA_ "ISignalName" SG_ 640 SmrtKey1BtnSts "ISmrtKey1BtnSts";
BA_ "LongName" SG_ 640 SmrtKey1BtnSts "Smart Key 1 Button Status";
BA_ "SysSignalName" SG_ 640 SmrtKey1BtnSts "SmrtKey1BtnSts";
BA_ "CompuMethodName" SG_ 640 SmrtKey2BtnSts "SmrtKey2BtnSts";
BA_ "ISignalName" SG_ 640 SmrtKey2BtnSts "ISmrtKey2BtnSts";
BA_ "LongName" SG_ 640 SmrtKey2BtnSts "Smart Key 2 Button Status";
BA_ "SysSignalName" SG_ 640 SmrtKey2BtnSts "SmrtKey2BtnSts";
BA_ "CompuMethodName" SG_ 640 SmrtKey3BtnSts "SmrtKey3BtnSts";
BA_ "ISignalName" SG_ 640 SmrtKey3BtnSts "ISmrtKey3BtnSts";
BA_ "LongName" SG_ 640 SmrtKey3BtnSts "Smart Key 3 Button Status";
BA_ "SysSignalName" SG_ 640 SmrtKey3BtnSts "SmrtKey3BtnSts";
BA_ "CompuMethodName" SG_ 640 SmrtKey4BtnSts "SmrtKey4BtnSts";
BA_ "ISignalName" SG_ 640 SmrtKey4BtnSts "ISmrtKey4BtnSts";
BA_ "LongName" SG_ 640 SmrtKey4BtnSts "Smart Key 4 Button Status";
BA_ "SysSignalName" SG_ 640 SmrtKey4BtnSts "SmrtKey4BtnSts";
BA_ "CompuMethodName" SG_ 640 SmrtKey2LoctnResp "SmrtKey2LoctnResp";
BA_ "ISignalName" SG_ 640 SmrtKey2LoctnResp "ISmrtKey2LoctnResp";
BA_ "LongName" SG_ 640 SmrtKey2LoctnResp "Smart Key 2 Location Response";
BA_ "SysSignalName" SG_ 640 SmrtKey2LoctnResp "SmrtKey2LoctnResp";
BA_ "CompuMethodName" SG_ 640 SmrtKey1LoctnResp "SmrtKey1LoctnResp";
BA_ "ISignalName" SG_ 640 SmrtKey1LoctnResp "ISmrtKey1LoctnResp";
BA_ "LongName" SG_ 640 SmrtKey1LoctnResp "Smart Key 1 Location Response";
BA_ "SysSignalName" SG_ 640 SmrtKey1LoctnResp "SmrtKey1LoctnResp";
BA_ "CompuMethodName" SG_ 640 LHandAntFltSts "LHandAntFltSts";
BA_ "ISignalName" SG_ 640 LHandAntFltSts "ILHandAntFltSts";
BA_ "LongName" SG_ 640 LHandAntFltSts "Left Hand Antenna Fault Status";
BA_ "SysSignalName" SG_ 640 LHandAntFltSts "LHandAntFltSts";
BA_ "CompuMethodName" SG_ 640 SmrtKey3LoctnResp "SmrtKey3LoctnResp";
BA_ "ISignalName" SG_ 640 SmrtKey3LoctnResp "ISmrtKey3LoctnResp";
BA_ "LongName" SG_ 640 SmrtKey3LoctnResp "Smart Key 3 Location Response";
BA_ "SysSignalName" SG_ 640 SmrtKey3LoctnResp "SmrtKey3LoctnResp";
BA_ "CompuMethodName" SG_ 640 FrtBmpAntFltSts "FrtBmpAntFltSts";
BA_ "ISignalName" SG_ 640 FrtBmpAntFltSts "IFrtBmpAntFltSts";
BA_ "LongName" SG_ 640 FrtBmpAntFltSts "Front Bumper Antenna Fault Status";
BA_ "SysSignalName" SG_ 640 FrtBmpAntFltSts "FrtBmpAntFltSts";
BA_ "CompuMethodName" SG_ 640 RHandAntFltSts "RHandAntFltSts";
BA_ "ISignalName" SG_ 640 RHandAntFltSts "IRHandAntFltSts";
BA_ "LongName" SG_ 640 RHandAntFltSts "Right Hand Antenna Fault Status";
BA_ "SysSignalName" SG_ 640 RHandAntFltSts "RHandAntFltSts";
BA_ "CompuMethodName" SG_ 640 CabinFrtAntFltSts "CabinFrtAntFltSts";
BA_ "ISignalName" SG_ 640 CabinFrtAntFltSts "ICabinFrtAntFltSts";
BA_ "LongName" SG_ 640 CabinFrtAntFltSts "Cabin Front Antenna Fault Status";
BA_ "SysSignalName" SG_ 640 CabinFrtAntFltSts "CabinFrtAntFltSts";
BA_ "CompuMethodName" SG_ 640 RrBmpAntFltSts "RrBmpAntFltSts";
BA_ "ISignalName" SG_ 640 RrBmpAntFltSts "IRrBmpAntFltSts";
BA_ "LongName" SG_ 640 RrBmpAntFltSts "Rear Bumper Antenna Fault Status";
BA_ "SysSignalName" SG_ 640 RrBmpAntFltSts "RrBmpAntFltSts";
BA_ "CompuMethodName" SG_ 640 CabinRrAntFltSts "CabinRrAntFltSts";
BA_ "ISignalName" SG_ 640 CabinRrAntFltSts "ICabinRrAntFltSts";
BA_ "LongName" SG_ 640 CabinRrAntFltSts "Cabin Front Antenna Fault Status";
BA_ "SysSignalName" SG_ 640 CabinRrAntFltSts "CabinRrAntFltSts";
BA_ "CompuMethodName" SG_ 640 CabinImmoAntFltSts "CabinImmoAntFltSts";
BA_ "ISignalName" SG_ 640 CabinImmoAntFltSts "ICabinImmoAntFltSts";
BA_ "LongName" SG_ 640 CabinImmoAntFltSts "Cabin IMMO Antenna Fault Status";
BA_ "SysSignalName" SG_ 640 CabinImmoAntFltSts "CabinImmoAntFltSts";
BA_ "CompuMethodName" SG_ 640 KickSnsrDetnSts "KickSnsrDetnSts";
BA_ "ISignalName" SG_ 640 KickSnsrDetnSts "IKickSnsrDetnSts";
BA_ "LongName" SG_ 640 KickSnsrDetnSts "Kick Sensor Detection Status";
BA_ "SysSignalName" SG_ 640 KickSnsrDetnSts "KickSnsrDetnSts";
BA_ "CompuMethodName" SG_ 640 TrdtnSmrtKyLdspcSwSts "TrdtnSmrtKyLdspcSwSts";
BA_ "ISignalName" SG_ 640 TrdtnSmrtKyLdspcSwSts "ITrdtnSmrtKyLdspcSwSts";
BA_ "LongName" SG_ 640 TrdtnSmrtKyLdspcSwSts "Tradition Smart Key Loadspace Switch Press Status";
BA_ "SysSignalName" SG_ 640 TrdtnSmrtKyLdspcSwSts "TrdtnSmrtKyLdspcSwSts";
BA_ "CompuMethodName" SG_ 640 TrdtnSmrtKyFindCarSwSts "TrdtnSmrtKyFindCarSwSts";
BA_ "ISignalName" SG_ 640 TrdtnSmrtKyFindCarSwSts "ITrdtnSmrtKyFindCarSwSts";
BA_ "LongName" SG_ 640 TrdtnSmrtKyFindCarSwSts "Tradition Smart Key Find Car Switch Press Status";
BA_ "SysSignalName" SG_ 640 TrdtnSmrtKyFindCarSwSts "TrdtnSmrtKyFindCarSwSts";
BA_ "CompuMethodName" SG_ 513 FLDircnLghtSts "FLDircnLghtSts";
BA_ "ISignalName" SG_ 513 FLDircnLghtSts "IFLDircnLghtSts";
BA_ "LongName" SG_ 513 FLDircnLghtSts "Left_Front_Direction_Light_Status";
BA_ "SysSignalName" SG_ 513 FLDircnLghtSts "FLDircnLghtSts";
BA_ "CompuMethodName" SG_ 513 LMainBeamLghtSts "LMainBeamLghtSts";
BA_ "ISignalName" SG_ 513 LMainBeamLghtSts "ILMainBeamLghtSts";
BA_ "LongName" SG_ 513 LMainBeamLghtSts "Left_Main_beam_Light_Status";
BA_ "SysSignalName" SG_ 513 LMainBeamLghtSts "LMainBeamLghtSts";
BA_ "CompuMethodName" SG_ 513 LDipdBeamLghtSts "LDipdBeamLghtSts";
BA_ "ISignalName" SG_ 513 LDipdBeamLghtSts "ILDipdBeamLghtSts";
BA_ "LongName" SG_ 513 LDipdBeamLghtSts "Left  Dipped BeamLight State";
BA_ "SysSignalName" SG_ 513 LDipdBeamLghtSts "LDipdBeamLghtSts";
BA_ "CompuMethodName" SG_ 513 ESCLAuthnReq "ESCLAuthnReq";
BA_ "ISignalName" SG_ 513 ESCLAuthnReq "IESCLAuthnReq";
BA_ "LongName" SG_ 513 ESCLAuthnReq "Electronic Steering Column Lock Authentication Request";
BA_ "SysSignalName" SG_ 513 ESCLAuthnReq "ESCLAuthnReq";
BA_ "CompuMethodName" SG_ 513 DipdBeamLghtOnReq "DipdBeamLghtOnReq";
BA_ "ISignalName" SG_ 513 DipdBeamLghtOnReq "IDipdBeamLghtOnReq";
BA_ "LongName" SG_ 513 DipdBeamLghtOnReq "Dipped Beam Light On Request";
BA_ "SysSignalName" SG_ 513 DipdBeamLghtOnReq "DipdBeamLghtOnReq";
BA_ "CompuMethodName" SG_ 800 FLDSP_RrWinInhbSwtSts "FLDSP_RrWinInhbSwtSts";
BA_ "ISignalName" SG_ 800 FLDSP_RrWinInhbSwtSts "IFLDSP_RrWinInhbSwtSts";
BA_ "LongName" SG_ 800 FLDSP_RrWinInhbSwtSts "Rear Window Inhibit Switch Status";
BA_ "SysSignalName" SG_ 800 FLDSP_RrWinInhbSwtSts "FLDSP_RrWinInhbSwtSts";
BA_ "CompuMethodName" SG_ 800 FLDSP_RrWinInhbSwtFlt "FLDSP_RrWinInhbSwtFlt";
BA_ "ISignalName" SG_ 800 FLDSP_RrWinInhbSwtFlt "IFLDSP_RrWinInhbSwtFlt";
BA_ "LongName" SG_ 800 FLDSP_RrWinInhbSwtFlt "Rear Window Inhibit Switch Fault";
BA_ "SysSignalName" SG_ 800 FLDSP_RrWinInhbSwtFlt "FLDSP_RrWinInhbSwtFlt";
BA_ "CompuMethodName" SG_ 800 BCMOdoReq "BCMOdoReq";
BA_ "ISignalName" SG_ 800 BCMOdoReq "IBCMOdoReq";
BA_ "LongName" SG_ 800 BCMOdoReq "Body Control Module Odometer Request";
BA_ "SysSignalName" SG_ 800 BCMOdoReq "BCMOdoReq";
BA_ "CompuMethodName" SG_ 800 DircnIndLampSwStsMntry_CPD "DircnIndLampSwStsMntry_CPD";
BA_ "ISignalName" SG_ 800 DircnIndLampSwStsMntry_CPD "IDircnIndLampSwStsMntry_CPD";
BA_ "LongName" SG_ 800 DircnIndLampSwStsMntry_CPD "Direction Indication Lamp Switch Status Momentary";
BA_ "SysSignalName" SG_ 800 DircnIndLampSwStsMntry_CPD "DircnIndLampSwStsMntry_CPD";
BA_ "CompuMethodName" SG_ 800 OdoSecy "OdoSecy";
BA_ "ISignalName" SG_ 800 OdoSecy "IOdoSecy";
BA_ "LongName" SG_ 800 OdoSecy "Odometer Secondary";
BA_ "SysSignalName" SG_ 800 OdoSecy "OdoSecy";
BA_ "CompuMethodName" SG_ 800 ImmoSubModTCAuthnRunSts "ImmoSubModTCAuthnRunSts";
BA_ "ISignalName" SG_ 800 ImmoSubModTCAuthnRunSts "IImmoSubModTCAuthnRunSts";
BA_ "LongName" SG_ 800 ImmoSubModTCAuthnRunSts "Immobilizer_Sub_Module_Traction_Controller_Authentication_Run_Status";
BA_ "SysSignalName" SG_ 800 ImmoSubModTCAuthnRunSts "ImmoSubModTCAuthnRunSts";
BA_ "CompuMethodName" SG_ 800 ImmoSubModSACAuthnRunSts "ImmoSubModSACAuthnRunSts";
BA_ "ISignalName" SG_ 800 ImmoSubModSACAuthnRunSts "IImmoSubModSACAuthnRunSts";
BA_ "LongName" SG_ 800 ImmoSubModSACAuthnRunSts "Immobilizer_Sub_Module_Sencondery_Axis_Controller_Authentication_Run_Status";
BA_ "SysSignalName" SG_ 800 ImmoSubModSACAuthnRunSts "ImmoSubModSACAuthnRunSts";
BA_ "CompuMethodName" SG_ 800 EDRDircnIndLampSwSts "EDRDircnIndLampSwSts";
BA_ "ISignalName" SG_ 800 EDRDircnIndLampSwSts "IEDRDircnIndLampSwSts";
BA_ "LongName" SG_ 800 EDRDircnIndLampSwSts "EDR direction indication lamp switch status";
BA_ "SysSignalName" SG_ 800 EDRDircnIndLampSwSts "EDRDircnIndLampSwSts";
BA_ "CompuMethodName" SG_ 800 TemSnsrHdwrFltPrst "TemSnsrHdwrFltPrst";
BA_ "ISignalName" SG_ 800 TemSnsrHdwrFltPrst "ITemSnsrHdwrFltPrst";
BA_ "LongName" SG_ 800 TemSnsrHdwrFltPrst "Temperature Sensor Hardware Fault Present";
BA_ "SysSignalName" SG_ 800 TemSnsrHdwrFltPrst "TemSnsrHdwrFltPrst";
BA_ "CompuMethodName" SG_ 905 SmtKeyAuthnMnModRunSts "SmtKeyAuthnMnModRunSts";
BA_ "ISignalName" SG_ 905 SmtKeyAuthnMnModRunSts "ISmtKeyAuthnMnModRunSts";
BA_ "LongName" SG_ 905 SmtKeyAuthnMnModRunSts "Smart_Key__Authentication_Platform_Run_Status";
BA_ "SysSignalName" SG_ 905 SmtKeyAuthnMnModRunSts "SmtKeyAuthnMnModRunSts";
BA_ "CompuMethodName" SG_ 905 HtdFrtLftVwWndActSts "HtdFrtLftVwWndActSts";
BA_ "ISignalName" SG_ 905 HtdFrtLftVwWndActSts "IHtdFrtLftVwWndActSts";
BA_ "LongName" SG_ 905 HtdFrtLftVwWndActSts "Heated Front  Left View Window Actual Status";
BA_ "SysSignalName" SG_ 905 HtdFrtLftVwWndActSts "HtdFrtLftVwWndActSts";
BA_ "CompuMethodName" SG_ 905 LOtsdMirActSts "LOtsdMirActSts";
BA_ "ISignalName" SG_ 905 LOtsdMirActSts "ILOtsdMirActSts";
BA_ "LongName" SG_ 905 LOtsdMirActSts "Left_Outside_Mirror_Action_Status";
BA_ "SysSignalName" SG_ 905 LOtsdMirActSts "LOtsdMirActSts";
BA_ "CompuMethodName" SG_ 905 FrtWindShldSurndHmdty "FrtWindShldSurndHmdty";
BA_ "ISignalName" SG_ 905 FrtWindShldSurndHmdty "IFrtWindShldSurndHmdty";
BA_ "LongName" SG_ 905 FrtWindShldSurndHmdty "Front Windsheld Surround Humidity";
BA_ "SysSignalName" SG_ 905 FrtWindShldSurndHmdty "FrtWindShldSurndHmdty";
BA_ "CompuMethodName" SG_ 905 SolarStrngLSide "SolarStrngLSide";
BA_ "ISignalName" SG_ 905 SolarStrngLSide "ISolarStrngLSide";
BA_ "LongName" SG_ 905 SolarStrngLSide "Solar Strength Left Side";
BA_ "SysSignalName" SG_ 905 SolarStrngLSide "SolarStrngLSide";
BA_ "CompuMethodName" SG_ 905 SolarStrngRSide "SolarStrngRSide";
BA_ "ISignalName" SG_ 905 SolarStrngRSide "ISolarStrngRSide";
BA_ "LongName" SG_ 905 SolarStrngRSide "Solar Strength Right Side";
BA_ "SysSignalName" SG_ 905 SolarStrngRSide "SolarStrngRSide";
BA_ "CompuMethodName" SG_ 905 FrtWindShldSurndTem "FrtWindShldSurndTem";
BA_ "ISignalName" SG_ 905 FrtWindShldSurndTem "IFrtWindShldSurndTem";
BA_ "LongName" SG_ 905 FrtWindShldSurndTem "Front Windsheld Surround Temperature";
BA_ "SysSignalName" SG_ 905 FrtWindShldSurndTem "FrtWindShldSurndTem";
BA_ "CompuMethodName" SG_ 905 FrtWindShldSfcTem "FrtWindShldSfcTem";
BA_ "ISignalName" SG_ 905 FrtWindShldSfcTem "IFrtWindShldSfcTem";
BA_ "LongName" SG_ 905 FrtWindShldSfcTem "Front Windsheld Surface Temperature";
BA_ "SysSignalName" SG_ 905 FrtWindShldSfcTem "FrtWindShldSfcTem";
BA_ "CompuMethodName" SG_ 905 SolarStrngLSideV "SolarStrngLSideV";
BA_ "ISignalName" SG_ 905 SolarStrngLSideV "ISolarStrngLSideV";
BA_ "LongName" SG_ 905 SolarStrngLSideV "Solar Strength Left Side Valid";
BA_ "SysSignalName" SG_ 905 SolarStrngLSideV "SolarStrngLSideV";
BA_ "CompuMethodName" SG_ 905 SolarStrngRSideV "SolarStrngRSideV";
BA_ "ISignalName" SG_ 905 SolarStrngRSideV "ISolarStrngRSideV";
BA_ "LongName" SG_ 905 SolarStrngRSideV "Solar Strength Right Side Valid";
BA_ "SysSignalName" SG_ 905 SolarStrngRSideV "SolarStrngRSideV";
BA_ "CompuMethodName" SG_ 905 DKBLERst "DKBLERst";
BA_ "ISignalName" SG_ 905 DKBLERst "IDKBLERst";
BA_ "LongName" SG_ 905 DKBLERst "Digital Key Ble Reset";
BA_ "SysSignalName" SG_ 905 DKBLERst "DKBLERst";
BA_ "CompuMethodName" SG_ 905 FrtWiperSpd "FrtWiperSpd";
BA_ "ISignalName" SG_ 905 FrtWiperSpd "IFrtWiperSpd";
BA_ "LongName" SG_ 905 FrtWiperSpd "Front_Wiper_Speed";
BA_ "SysSignalName" SG_ 905 FrtWiperSpd "FrtWiperSpd";
BA_ "CompuMethodName" SG_ 783 LHZCUeFs12Crnt "LHZCUeFs12Crnt";
BA_ "ISignalName" SG_ 783 LHZCUeFs12Crnt "ILHZCUeFs12Crnt";
BA_ "LongName" SG_ 783 LHZCUeFs12Crnt "LHZCU eFuse12 Current";
BA_ "SysSignalName" SG_ 783 LHZCUeFs12Crnt "LHZCUeFs12Crnt";
BA_ "CompuMethodName" SG_ 783 LHZCUeSw40Crnt "LHZCUeSw40Crnt";
BA_ "ISignalName" SG_ 783 LHZCUeSw40Crnt "ILHZCUeSw40Crnt";
BA_ "LongName" SG_ 783 LHZCUeSw40Crnt "LHZCU eSwitch40 Current";
BA_ "SysSignalName" SG_ 783 LHZCUeSw40Crnt "LHZCUeSw40Crnt";
BA_ "CompuMethodName" SG_ 783 WlcmReq "WlcmReq";
BA_ "ISignalName" SG_ 783 WlcmReq "IWlcmReq";
BA_ "LongName" SG_ 783 WlcmReq "Welcome Request";
BA_ "SysSignalName" SG_ 783 WlcmReq "WlcmReq";
BA_ "CompuMethodName" SG_ 783 FllwMeReq "FllwMeReq";
BA_ "ISignalName" SG_ 783 FllwMeReq "IFllwMeReq";
BA_ "LongName" SG_ 783 FllwMeReq "Follow ME Home Request";
BA_ "SysSignalName" SG_ 783 FllwMeReq "FllwMeReq";
BA_ "CompuMethodName" SG_ 783 LHZCUInptVol "LHZCUInptVol";
BA_ "ISignalName" SG_ 783 LHZCUInptVol "ILHZCUInptVol";
BA_ "LongName" SG_ 783 LHZCUInptVol "LHZCU Input Voltage";
BA_ "SysSignalName" SG_ 783 LHZCUInptVol "LHZCUInptVol";
BA_ "CompuMethodName" SG_ 783 LHZCUeFs8Crnt "LHZCUeFs8Crnt";
BA_ "ISignalName" SG_ 783 LHZCUeFs8Crnt "ILHZCUeFs8Crnt";
BA_ "LongName" SG_ 783 LHZCUeFs8Crnt "LHZCU eFuse8 Current";
BA_ "SysSignalName" SG_ 783 LHZCUeFs8Crnt "LHZCUeFs8Crnt";
BA_ "CompuMethodName" SG_ 783 LHZCUeSw24Crnt "LHZCUeSw24Crnt";
BA_ "ISignalName" SG_ 783 LHZCUeSw24Crnt "ILHZCUeSw24Crnt";
BA_ "LongName" SG_ 783 LHZCUeSw24Crnt "LHZCU eSwitch24 Current";
BA_ "SysSignalName" SG_ 783 LHZCUeSw24Crnt "LHZCUeSw24Crnt";
BA_ "CompuMethodName" SG_ 783 LHZCUeSw17Crnt "LHZCUeSw17Crnt";
BA_ "ISignalName" SG_ 783 LHZCUeSw17Crnt "ILHZCUeSw17Crnt";
BA_ "LongName" SG_ 783 LHZCUeSw17Crnt "LHZCU eSwitch17 Current";
BA_ "SysSignalName" SG_ 783 LHZCUeSw17Crnt "LHZCUeSw17Crnt";
BA_ "CompuMethodName" SG_ 783 LHZCUeSw16Crnt "LHZCUeSw16Crnt";
BA_ "ISignalName" SG_ 783 LHZCUeSw16Crnt "ILHZCUeSw16Crnt";
BA_ "LongName" SG_ 783 LHZCUeSw16Crnt "LHZCU eSwitch16 Current";
BA_ "SysSignalName" SG_ 783 LHZCUeSw16Crnt "LHZCUeSw16Crnt";
BA_ "CompuMethodName" SG_ 783 LHZCUeSw15Crnt "LHZCUeSw15Crnt";
BA_ "ISignalName" SG_ 783 LHZCUeSw15Crnt "ILHZCUeSw15Crnt";
BA_ "LongName" SG_ 783 LHZCUeSw15Crnt "LHZCU eSwitch15 Current";
BA_ "SysSignalName" SG_ 783 LHZCUeSw15Crnt "LHZCUeSw15Crnt";
BA_ "CompuMethodName" SG_ 783 LHZCUeSw14Crnt "LHZCUeSw14Crnt";
BA_ "ISignalName" SG_ 783 LHZCUeSw14Crnt "ILHZCUeSw14Crnt";
BA_ "LongName" SG_ 783 LHZCUeSw14Crnt "LHZCU eSwitch14 Current";
BA_ "SysSignalName" SG_ 783 LHZCUeSw14Crnt "LHZCUeSw14Crnt";
BA_ "CompuMethodName" SG_ 783 LHZCUeSw13Crnt "LHZCUeSw13Crnt";
BA_ "ISignalName" SG_ 783 LHZCUeSw13Crnt "ILHZCUeSw13Crnt";
BA_ "LongName" SG_ 783 LHZCUeSw13Crnt "LHZCU eSwitch13 Current";
BA_ "SysSignalName" SG_ 783 LHZCUeSw13Crnt "LHZCUeSw13Crnt";
BA_ "CompuMethodName" SG_ 783 LHZCUeSw12Crnt "LHZCUeSw12Crnt";
BA_ "ISignalName" SG_ 783 LHZCUeSw12Crnt "ILHZCUeSw12Crnt";
BA_ "LongName" SG_ 783 LHZCUeSw12Crnt "LHZCU eSwitch12 Current";
BA_ "SysSignalName" SG_ 783 LHZCUeSw12Crnt "LHZCUeSw12Crnt";
BA_ "CompuMethodName" SG_ 783 LHZCUeSw26Crnt "LHZCUeSw26Crnt";
BA_ "ISignalName" SG_ 783 LHZCUeSw26Crnt "ILHZCUeSw26Crnt";
BA_ "LongName" SG_ 783 LHZCUeSw26Crnt "LHZCU eSwitch26 Current";
BA_ "SysSignalName" SG_ 783 LHZCUeSw26Crnt "LHZCUeSw26Crnt";
BA_ "CompuMethodName" SG_ 783 LHZCUeFs6Crnt "LHZCUeFs6Crnt";
BA_ "ISignalName" SG_ 783 LHZCUeFs6Crnt "ILHZCUeFs6Crnt";
BA_ "LongName" SG_ 783 LHZCUeFs6Crnt "LHZCU eFuse6 Current";
BA_ "SysSignalName" SG_ 783 LHZCUeFs6Crnt "LHZCUeFs6Crnt";
BA_ "CompuMethodName" SG_ 783 LHZCUeSw32Crnt "LHZCUeSw32Crnt";
BA_ "ISignalName" SG_ 783 LHZCUeSw32Crnt "ILHZCUeSw32Crnt";
BA_ "LongName" SG_ 783 LHZCUeSw32Crnt "LHZCU eSwitch32 Current";
BA_ "SysSignalName" SG_ 783 LHZCUeSw32Crnt "LHZCUeSw32Crnt";
BA_ "CompuMethodName" SG_ 783 LHZCUeFs4Crnt "LHZCUeFs4Crnt";
BA_ "ISignalName" SG_ 783 LHZCUeFs4Crnt "ILHZCUeFs4Crnt";
BA_ "LongName" SG_ 783 LHZCUeFs4Crnt "LHZCU eFuse4 Current";
BA_ "SysSignalName" SG_ 783 LHZCUeFs4Crnt "LHZCUeFs4Crnt";
BA_ "CompuMethodName" SG_ 783 LHZCUeSw27Crnt "LHZCUeSw27Crnt";
BA_ "ISignalName" SG_ 783 LHZCUeSw27Crnt "ILHZCUeSw27Crnt";
BA_ "LongName" SG_ 783 LHZCUeSw27Crnt "LHZCU eSwitch27 Current";
BA_ "SysSignalName" SG_ 783 LHZCUeSw27Crnt "LHZCUeSw27Crnt";
BA_ "CompuMethodName" SG_ 783 LHZCUBkupInptVol "LHZCUBkupInptVol";
BA_ "ISignalName" SG_ 783 LHZCUBkupInptVol "ILHZCUBkupInptVol";
BA_ "LongName" SG_ 783 LHZCUBkupInptVol "LHZCU Backup Input Voltage";
BA_ "SysSignalName" SG_ 783 LHZCUBkupInptVol "LHZCUBkupInptVol";
BA_ "CompuMethodName" SG_ 783 LHZCUeSw1Crnt "LHZCUeSw1Crnt";
BA_ "ISignalName" SG_ 783 LHZCUeSw1Crnt "ILHZCUeSw1Crnt";
BA_ "LongName" SG_ 783 LHZCUeSw1Crnt "LHZCU eSwitch1 Current";
BA_ "SysSignalName" SG_ 783 LHZCUeSw1Crnt "LHZCUeSw1Crnt";
BA_ "CompuMethodName" SG_ 783 LHZCUeSw20Crnt "LHZCUeSw20Crnt";
BA_ "ISignalName" SG_ 783 LHZCUeSw20Crnt "ILHZCUeSw20Crnt";
BA_ "LongName" SG_ 783 LHZCUeSw20Crnt "LHZCU eSwitch20 Current";
BA_ "SysSignalName" SG_ 783 LHZCUeSw20Crnt "LHZCUeSw20Crnt";
BA_ "CompuMethodName" SG_ 783 LHZCUeSw3Crnt "LHZCUeSw3Crnt";
BA_ "ISignalName" SG_ 783 LHZCUeSw3Crnt "ILHZCUeSw3Crnt";
BA_ "LongName" SG_ 783 LHZCUeSw3Crnt "LHZCU eSwitch3 Current";
BA_ "SysSignalName" SG_ 783 LHZCUeSw3Crnt "LHZCUeSw3Crnt";
BA_ "CompuMethodName" SG_ 783 LHZCUeSw29Crnt "LHZCUeSw29Crnt";
BA_ "ISignalName" SG_ 783 LHZCUeSw29Crnt "ILHZCUeSw29Crnt";
BA_ "LongName" SG_ 783 LHZCUeSw29Crnt "LHZCU eSwitch29 Current";
BA_ "SysSignalName" SG_ 783 LHZCUeSw29Crnt "LHZCUeSw29Crnt";
BA_ "CompuMethodName" SG_ 783 LHZCUeSw36Crnt "LHZCUeSw36Crnt";
BA_ "ISignalName" SG_ 783 LHZCUeSw36Crnt "ILHZCUeSw36Crnt";
BA_ "LongName" SG_ 783 LHZCUeSw36Crnt "LHZCU eSwitch36 Current";
BA_ "SysSignalName" SG_ 783 LHZCUeSw36Crnt "LHZCUeSw36Crnt";
BA_ "CompuMethodName" SG_ 783 LHZCUeFs13Crnt "LHZCUeFs13Crnt";
BA_ "ISignalName" SG_ 783 LHZCUeFs13Crnt "ILHZCUeFs13Crnt";
BA_ "LongName" SG_ 783 LHZCUeFs13Crnt "LHZCU eFuse13 Current";
BA_ "SysSignalName" SG_ 783 LHZCUeFs13Crnt "LHZCUeFs13Crnt";
BA_ "CompuMethodName" SG_ 783 LHZCUeSw30Crnt "LHZCUeSw30Crnt";
BA_ "ISignalName" SG_ 783 LHZCUeSw30Crnt "ILHZCUeSw30Crnt";
BA_ "LongName" SG_ 783 LHZCUeSw30Crnt "LHZCU eSwitch30 Current";
BA_ "SysSignalName" SG_ 783 LHZCUeSw30Crnt "LHZCUeSw30Crnt";
BA_ "CompuMethodName" SG_ 783 LHZCUeSw31Crnt "LHZCUeSw31Crnt";
BA_ "ISignalName" SG_ 783 LHZCUeSw31Crnt "ILHZCUeSw31Crnt";
BA_ "LongName" SG_ 783 LHZCUeSw31Crnt "LHZCU eSwitch31 Current";
BA_ "SysSignalName" SG_ 783 LHZCUeSw31Crnt "LHZCUeSw31Crnt";
BA_ "CompuMethodName" SG_ 783 FrwlLghtReq_LHZCU "FrwlLghtReq_LHZCU";
BA_ "ISignalName" SG_ 783 FrwlLghtReq_LHZCU "IFrwlLghtReq_LHZCU";
BA_ "LongName" SG_ 783 FrwlLghtReq_LHZCU "Farewell Light Request";
BA_ "SysSignalName" SG_ 783 FrwlLghtReq_LHZCU "FrwlLghtReq_LHZCU";
BA_ "CompuMethodName" SG_ 783 LHZCUeSw43Crnt "LHZCUeSw43Crnt";
BA_ "ISignalName" SG_ 783 LHZCUeSw43Crnt "ILHZCUeSw43Crnt";
BA_ "LongName" SG_ 783 LHZCUeSw43Crnt "LHZCU eSwitch43 Current";
BA_ "SysSignalName" SG_ 783 LHZCUeSw43Crnt "LHZCUeSw43Crnt";
BA_ "CompuMethodName" SG_ 783 LHZCUAddtnInptVol "LHZCUAddtnInptVol";
BA_ "ISignalName" SG_ 783 LHZCUAddtnInptVol "ILHZCUAddtnInptVol";
BA_ "LongName" SG_ 783 LHZCUAddtnInptVol "LHZCU Additional Input Voltage";
BA_ "SysSignalName" SG_ 783 LHZCUAddtnInptVol "LHZCUAddtnInptVol";
BA_ "CompuMethodName" SG_ 783 LHZCUeSw44Crnt "LHZCUeSw44Crnt";
BA_ "ISignalName" SG_ 783 LHZCUeSw44Crnt "ILHZCUeSw44Crnt";
BA_ "LongName" SG_ 783 LHZCUeSw44Crnt "LHZCU eSwitch44 Current";
BA_ "SysSignalName" SG_ 783 LHZCUeSw44Crnt "LHZCUeSw44Crnt";
BA_ "CompuMethodName" SG_ 783 LHZCUeSw45Crnt "LHZCUeSw45Crnt";
BA_ "ISignalName" SG_ 783 LHZCUeSw45Crnt "ILHZCUeSw45Crnt";
BA_ "LongName" SG_ 783 LHZCUeSw45Crnt "LHZCU eSwitch45 Current";
BA_ "SysSignalName" SG_ 783 LHZCUeSw45Crnt "LHZCUeSw45Crnt";
BA_ "CompuMethodName" SG_ 783 FLSeatZeroSt "FLSeatZeroSt";
BA_ "ISignalName" SG_ 783 FLSeatZeroSt "IFLSeatZeroSt";
BA_ "LongName" SG_ 783 FLSeatZeroSt "Msm Driver Seat Zero Position Learning Status";
BA_ "SysSignalName" SG_ 783 FLSeatZeroSt "FLSeatZeroSt";
BA_ "CompuMethodName" SG_ 783 LHZCUeSw46Crnt "LHZCUeSw46Crnt";
BA_ "ISignalName" SG_ 783 LHZCUeSw46Crnt "ILHZCUeSw46Crnt";
BA_ "LongName" SG_ 783 LHZCUeSw46Crnt "LHZCU eSwitch46 Current";
BA_ "SysSignalName" SG_ 783 LHZCUeSw46Crnt "LHZCUeSw46Crnt";
BA_ "CompuMethodName" SG_ 783 LHZCUeSw47Crnt "LHZCUeSw47Crnt";
BA_ "ISignalName" SG_ 783 LHZCUeSw47Crnt "ILHZCUeSw47Crnt";
BA_ "LongName" SG_ 783 LHZCUeSw47Crnt "LHZCU eSwitch47 Current";
BA_ "SysSignalName" SG_ 783 LHZCUeSw47Crnt "LHZCUeSw47Crnt";
BA_ "CompuMethodName" SG_ 783 WlcmLghtReq_LHZCU "WlcmLghtReq_LHZCU";
BA_ "ISignalName" SG_ 783 WlcmLghtReq_LHZCU "IWlcmLghtReq_LHZCU";
BA_ "LongName" SG_ 783 WlcmLghtReq_LHZCU "Welcome Light Request";
BA_ "SysSignalName" SG_ 783 WlcmLghtReq_LHZCU "WlcmLghtReq_LHZCU";
BA_ "CompuMethodName" SG_ 783 FLDoorOpenSts "FLDoorOpenSts";
BA_ "ISignalName" SG_ 783 FLDoorOpenSts "IFLDoorOpenSts";
BA_ "LongName" SG_ 783 FLDoorOpenSts "Front Left Door Open Status";
BA_ "SysSignalName" SG_ 783 FLDoorOpenSts "FLDoorOpenSts";
BA_ "CompuMethodName" SG_ 783 HUDLghtSnsrHdwrFltPrst "HUDLghtSnsrHdwrFltPrst";
BA_ "ISignalName" SG_ 783 HUDLghtSnsrHdwrFltPrst "IHUDLghtSnsrHdwrFltPrst";
BA_ "LongName" SG_ 783 HUDLghtSnsrHdwrFltPrst "HUD Light Sensor Hardware Fault Present";
BA_ "SysSignalName" SG_ 783 HUDLghtSnsrHdwrFltPrst "HUDLghtSnsrHdwrFltPrst";
BA_ "CompuMethodName" SG_ 783 FLSeatRclnMotActn "FLSeatRclnMotActn";
BA_ "ISignalName" SG_ 783 FLSeatRclnMotActn "IFLSeatRclnMotActn";
BA_ "LongName" SG_ 783 FLSeatRclnMotActn "Memory Seat Module  Driver Seat Recline Motor Action";
BA_ "SysSignalName" SG_ 783 FLSeatRclnMotActn "FLSeatRclnMotActn";
BA_ "CompuMethodName" SG_ 783 FLSeatVertMotActn "FLSeatVertMotActn";
BA_ "ISignalName" SG_ 783 FLSeatVertMotActn "IFLSeatVertMotActn";
BA_ "LongName" SG_ 783 FLSeatVertMotActn "Memory Seat Module  Driver Seat Vertical Motor Action";
BA_ "SysSignalName" SG_ 783 FLSeatVertMotActn "FLSeatVertMotActn";
BA_ "CompuMethodName" SG_ 783 FLSeatHoztMotActn "FLSeatHoztMotActn";
BA_ "ISignalName" SG_ 783 FLSeatHoztMotActn "IFLSeatHoztMotActn";
BA_ "LongName" SG_ 783 FLSeatHoztMotActn "Memory Seat Module Driver Seat Horizontal Motor Action";
BA_ "SysSignalName" SG_ 783 FLSeatHoztMotActn "FLSeatHoztMotActn";
BA_ "CompuMethodName" SG_ 783 HUDFwdLkngAmbtLghtLvl "HUDFwdLkngAmbtLghtLvl";
BA_ "ISignalName" SG_ 783 HUDFwdLkngAmbtLghtLvl "IHUDFwdLkngAmbtLghtLvl";
BA_ "LongName" SG_ 783 HUDFwdLkngAmbtLghtLvl "HUD Forward Light Looking  Ambient light  Level";
BA_ "SysSignalName" SG_ 783 HUDFwdLkngAmbtLghtLvl "HUDFwdLkngAmbtLghtLvl";
BA_ "CompuMethodName" SG_ 783 FollowMeHomeReq_LHZCU "FollowMeHomeReq_LHZCU";
BA_ "ISignalName" SG_ 783 FollowMeHomeReq_LHZCU "IFollowMeHomeReq_LHZCU";
BA_ "LongName" SG_ 783 FollowMeHomeReq_LHZCU "Follow Me Home Request";
BA_ "SysSignalName" SG_ 783 FollowMeHomeReq_LHZCU "FollowMeHomeReq_LHZCU";
BA_ "CompuMethodName" SG_ 783 BklghtReq "BklghtReq";
BA_ "ISignalName" SG_ 783 BklghtReq "IBklghtReq";
BA_ "LongName" SG_ 783 BklghtReq "BackLight Request";
BA_ "SysSignalName" SG_ 783 BklghtReq "BklghtReq";
BA_ "CompuMethodName" SG_ 783 HUDRLSAmbtLghtLvl "HUDRLSAmbtLghtLvl";
BA_ "ISignalName" SG_ 783 HUDRLSAmbtLghtLvl "IHUDRLSAmbtLghtLvl";
BA_ "LongName" SG_ 783 HUDRLSAmbtLghtLvl "HUD Rain Light sensor Ambient Light Level";
BA_ "SysSignalName" SG_ 783 HUDRLSAmbtLghtLvl "HUDRLSAmbtLghtLvl";
BA_ "CompuMethodName" SG_ 783 LHZCUeFs15Crnt "LHZCUeFs15Crnt";
BA_ "ISignalName" SG_ 783 LHZCUeFs15Crnt "ILHZCUeFs15Crnt";
BA_ "LongName" SG_ 783 LHZCUeFs15Crnt "LHZCU eFuse15 Current";
BA_ "SysSignalName" SG_ 783 LHZCUeFs15Crnt "LHZCUeFs15Crnt";
BA_ "CompuMethodName" SG_ 783 HmdtySnsrHdwrFltPrst "HmdtySnsrHdwrFltPrst";
BA_ "ISignalName" SG_ 783 HmdtySnsrHdwrFltPrst "IHmdtySnsrHdwrFltPrst";
BA_ "LongName" SG_ 783 HmdtySnsrHdwrFltPrst "Humidity Sensor Hardware Fault Present";
BA_ "SysSignalName" SG_ 783 HmdtySnsrHdwrFltPrst "HmdtySnsrHdwrFltPrst";
BA_ "CompuMethodName" SG_ 783 FrtPsngDoorOpenSts_LHZCU "FrtPsngDoorOpenSts_LHZCU";
BA_ "ISignalName" SG_ 783 FrtPsngDoorOpenSts_LHZCU "IFrtPsngDoorOpenSts_LHZCU";
BA_ "LongName" SG_ 783 FrtPsngDoorOpenSts_LHZCU "Front_Passenger_Door_Open_Status_LHZCU";
BA_ "SysSignalName" SG_ 783 FrtPsngDoorOpenSts_LHZCU "FrtPsngDoorOpenSts_LHZCU";
BA_ "CompuMethodName" SG_ 783 LHZCUeFs17Crnt "LHZCUeFs17Crnt";
BA_ "ISignalName" SG_ 783 LHZCUeFs17Crnt "ILHZCUeFs17Crnt";
BA_ "LongName" SG_ 783 LHZCUeFs17Crnt "LHZCU eFuse17 Current";
BA_ "SysSignalName" SG_ 783 LHZCUeFs17Crnt "LHZCUeFs17Crnt";
BA_ "CompuMethodName" SG_ 896 LowBttySta "LowBttySta";
BA_ "ISignalName" SG_ 896 LowBttySta "ILowBttySta";
BA_ "LongName" SG_ 896 LowBttySta "Low Battery Status";
BA_ "SysSignalName" SG_ 896 LowBttySta "LowBttySta";
BA_ "CompuMethodName" SG_ 896 PutSmrtKeyToBkupPosRmnr "PutSmrtKeyToBkupPosRmnr";
BA_ "ISignalName" SG_ 896 PutSmrtKeyToBkupPosRmnr "IPutSmrtKeyToBkupPosRmnr";
BA_ "LongName" SG_ 896 PutSmrtKeyToBkupPosRmnr "Put Smart Key To Backup Position Reminder";
BA_ "SysSignalName" SG_ 896 PutSmrtKeyToBkupPosRmnr "PutSmrtKeyToBkupPosRmnr";
BA_ "CompuMethodName" SG_ 896 TakeKeyOutRmndr "TakeKeyOutRmndr";
BA_ "ISignalName" SG_ 896 TakeKeyOutRmndr "ITakeKeyOutRmndr";
BA_ "LongName" SG_ 896 TakeKeyOutRmndr "Take Key Out Reminder";
BA_ "SysSignalName" SG_ 896 TakeKeyOutRmndr "TakeKeyOutRmndr";
BA_ "CompuMethodName" SG_ 896 CustrDblCnfmGearShftReq "CustrDblCnfmGearShftReq";
BA_ "ISignalName" SG_ 896 CustrDblCnfmGearShftReq "ICustrDblCnfmGearShftReq";
BA_ "LongName" SG_ 896 CustrDblCnfmGearShftReq "Customer Double Comfirm Gear Shift Request";
BA_ "SysSignalName" SG_ 896 CustrDblCnfmGearShftReq "CustrDblCnfmGearShftReq";
BA_ "CompuMethodName" SG_ 896 FrtWiperSwSts "FrtWiperSwSts";
BA_ "ISignalName" SG_ 896 FrtWiperSwSts "IFrtWiperSwSts";
BA_ "LongName" SG_ 896 FrtWiperSwSts "Front_Wiper_Switch_Status";
BA_ "SysSignalName" SG_ 896 FrtWiperSwSts "FrtWiperSwSts";
BA_ "CompuMethodName" SG_ 896 FrtWshrPumpA "FrtWshrPumpA";
BA_ "ISignalName" SG_ 896 FrtWshrPumpA "IFrtWshrPumpA";
BA_ "LongName" SG_ 896 FrtWshrPumpA "Front Washer Pump Active";
BA_ "SysSignalName" SG_ 896 FrtWshrPumpA "FrtWshrPumpA";
BA_ "CompuMethodName" SG_ 896 FrtWiperOpReq "FrtWiperOpReq";
BA_ "ISignalName" SG_ 896 FrtWiperOpReq "IFrtWiperOpReq";
BA_ "LongName" SG_ 896 FrtWiperOpReq "Front WiperOpen Request";
BA_ "SysSignalName" SG_ 896 FrtWiperOpReq "FrtWiperOpReq";
BA_ "CompuMethodName" SG_ 157 LHZCU_10ms_Group01_CRC "LHZCU_10ms_Group01_CRC";
BA_ "ISignalName" SG_ 157 LHZCU_10ms_Group01_CRC "ILHZCU_10ms_Group01_CRC";
BA_ "LongName" SG_ 157 LHZCU_10ms_Group01_CRC "LHZCU_10ms_Group01_CRC";
BA_ "SysSignalName" SG_ 157 LHZCU_10ms_Group01_CRC "LHZCU_10ms_Group01_CRC";
BA_ "CompuMethodName" SG_ 157 LHZCU_10ms_Group01_RC "LHZCU_10ms_Group01_RC";
BA_ "ISignalName" SG_ 157 LHZCU_10ms_Group01_RC "ILHZCU_10ms_Group01_RC";
BA_ "LongName" SG_ 157 LHZCU_10ms_Group01_RC "LHZCU_10ms_Group01_RC";
BA_ "SysSignalName" SG_ 157 LHZCU_10ms_Group01_RC "LHZCU_10ms_Group01_RC";
BA_ "CompuMethodName" SG_ 157 SCUFltLvlWarn "SCUFltLvlWarn";
BA_ "ISignalName" SG_ 157 SCUFltLvlWarn "ISCUFltLvlWarn";
BA_ "LongName" SG_ 157 SCUFltLvlWarn "Shifter Control Unit Fault Level Warning";
BA_ "SysSignalName" SG_ 157 SCUFltLvlWarn "SCUFltLvlWarn";
BA_ "CompuMethodName" SG_ 157 SCUDrvMd "SCUDrvMd";
BA_ "ISignalName" SG_ 157 SCUDrvMd "ISCUDrvMd";
BA_ "LongName" SG_ 157 SCUDrvMd "Shifter Control Unit Drive Mode";
BA_ "SysSignalName" SG_ 157 SCUDrvMd "SCUDrvMd";
BA_ "CompuMethodName" SG_ 157 SCUExtdShiftrFlr "SCUExtdShiftrFlr";
BA_ "ISignalName" SG_ 157 SCUExtdShiftrFlr "ISCUExtdShiftrFlr";
BA_ "LongName" SG_ 157 SCUExtdShiftrFlr "Shifter Control Unit Extended Shifter Failure";
BA_ "SysSignalName" SG_ 157 SCUExtdShiftrFlr "SCUExtdShiftrFlr";
BA_ "CompuMethodName" SG_ 157 SCUShiftrOpngRmndr "SCUShiftrOpngRmndr";
BA_ "ISignalName" SG_ 157 SCUShiftrOpngRmndr "ISCUShiftrOpngRmndr";
BA_ "LongName" SG_ 157 SCUShiftrOpngRmndr "Shifter Control Unit Shifter Operating Reminder";
BA_ "SysSignalName" SG_ 157 SCUShiftrOpngRmndr "SCUShiftrOpngRmndr";
BA_ "CompuMethodName" SG_ 157 KeyAuthResp "KeyAuthResp";
BA_ "ISignalName" SG_ 157 KeyAuthResp "IKeyAuthResp";
BA_ "LongName" SG_ 157 KeyAuthResp "Key  Authentication Response";
BA_ "SysSignalName" SG_ 157 KeyAuthResp "KeyAuthResp";
BA_ "CompuMethodName" SG_ 157 SCUParkLckReq "SCUParkLckReq";
BA_ "ISignalName" SG_ 157 SCUParkLckReq "ISCUParkLckReq";
BA_ "LongName" SG_ 157 SCUParkLckReq "Shifter Control Unit Park Lock Request";
BA_ "SysSignalName" SG_ 157 SCUParkLckReq "SCUParkLckReq";
BA_ "CompuMethodName" SG_ 157 SCUParkLckReqV "SCUParkLckReqV";
BA_ "GenSigStartValue" SG_ 157 SCUParkLckReqV 1;
BA_ "ISignalName" SG_ 157 SCUParkLckReqV "ISCUParkLckReqV";
BA_ "LongName" SG_ 157 SCUParkLckReqV "Shifter Control Unit Park Lock Request Validity";
BA_ "SysSignalName" SG_ 157 SCUParkLckReqV "SCUParkLckReqV";
BA_ "CompuMethodName" SG_ 157 LHZCU_10ms_Group01_Reserved1 "LHZCU_10ms_Group01_Reserved1";
BA_ "GenSigStartValue" SG_ 157 LHZCU_10ms_Group01_Reserved1 7;
BA_ "ISignalName" SG_ 157 LHZCU_10ms_Group01_Reserved1 "ILHZCU_10ms_Group01_Reserved1";
BA_ "SysSignalName" SG_ 157 LHZCU_10ms_Group01_Reserved1 "LHZCU_10ms_Group01_Reserved1";
BA_ "CompuMethodName" SG_ 157 DigKeyAuthReq "DigKeyAuthReq";
BA_ "ISignalName" SG_ 157 DigKeyAuthReq "IDigKeyAuthReq";
BA_ "LongName" SG_ 157 DigKeyAuthReq "Digtial Key Authentication  Request";
BA_ "SysSignalName" SG_ 157 DigKeyAuthReq "DigKeyAuthReq";
BA_ "CompuMethodName" SG_ 157 SCUShiftrLvrRawPosn "SCUShiftrLvrRawPosn";
BA_ "GenSigStartValue" SG_ 157 SCUShiftrLvrRawPosn 2;
BA_ "ISignalName" SG_ 157 SCUShiftrLvrRawPosn "ISCUShiftrLvrRawPosn";
BA_ "LongName" SG_ 157 SCUShiftrLvrRawPosn "Shifter Control Unit Shifter Lever Raw Position";
BA_ "SysSignalName" SG_ 157 SCUShiftrLvrRawPosn "SCUShiftrLvrRawPosn";
BA_ "CompuMethodName" SG_ 157 SCUParkLckReqVEPMCU "SCUParkLckReqVEPMCU";
BA_ "GenSigStartValue" SG_ 157 SCUParkLckReqVEPMCU 1;
BA_ "ISignalName" SG_ 157 SCUParkLckReqVEPMCU "ISCUParkLckReqVEPMCU";
BA_ "LongName" SG_ 157 SCUParkLckReqVEPMCU "Shifter Control Unit Park Lock Request Validity Electrical Parking Motor Control Unit";
BA_ "SysSignalName" SG_ 157 SCUParkLckReqVEPMCU "SCUParkLckReqVEPMCU";
BA_ "CompuMethodName" SG_ 157 LHZCU_10ms_Group01_Reserved2 "LHZCU_10ms_Group01_Reserved2";
BA_ "GenSigStartValue" SG_ 157 LHZCU_10ms_Group01_Reserved2 3;
BA_ "ISignalName" SG_ 157 LHZCU_10ms_Group01_Reserved2 "ILHZCU_10ms_Group01_Reserved2";
BA_ "SysSignalName" SG_ 157 LHZCU_10ms_Group01_Reserved2 "LHZCU_10ms_Group01_Reserved2";
BA_ "CompuMethodName" SG_ 157 SCUParkLckReqEPMCU "SCUParkLckReqEPMCU";
BA_ "ISignalName" SG_ 157 SCUParkLckReqEPMCU "ISCUParkLckReqEPMCU";
BA_ "LongName" SG_ 157 SCUParkLckReqEPMCU "Shifter Control Unit Park Lock Request Electrical Parking Motor Control Unit";
BA_ "SysSignalName" SG_ 157 SCUParkLckReqEPMCU "SCUParkLckReqEPMCU";
BA_ "CompuMethodName" SG_ 157 SCUShiftrPosnInvsn "SCUShiftrPosnInvsn";
BA_ "GenSigStartValue" SG_ 157 SCUShiftrPosnInvsn 15;
BA_ "ISignalName" SG_ 157 SCUShiftrPosnInvsn "ISCUShiftrPosnInvsn";
BA_ "LongName" SG_ 157 SCUShiftrPosnInvsn "Shifter Control Unit Shifter Position Inversion";
BA_ "SysSignalName" SG_ 157 SCUShiftrPosnInvsn "SCUShiftrPosnInvsn";
BA_ "CompuMethodName" SG_ 157 SCUShiftrLvrPosn "SCUShiftrLvrPosn";
BA_ "ISignalName" SG_ 157 SCUShiftrLvrPosn "ISCUShiftrLvrPosn";
BA_ "LongName" SG_ 157 SCUShiftrLvrPosn "Shifter Control Unit Shifter Lever Position";
BA_ "SysSignalName" SG_ 157 SCUShiftrLvrPosn "SCUShiftrLvrPosn";
BA_ "CompuMethodName" SG_ 157 DrvrReqParkBtn "DrvrReqParkBtn";
BA_ "ISignalName" SG_ 157 DrvrReqParkBtn "IDrvrReqParkBtn";
BA_ "LongName" SG_ 157 DrvrReqParkBtn "Driver Request Park Button";
BA_ "SysSignalName" SG_ 157 DrvrReqParkBtn "DrvrReqParkBtn";
BA_ "CompuMethodName" SG_ 157 SCUShiftrLvrPosnLtchActv "SCUShiftrLvrPosnLtchActv";
BA_ "ISignalName" SG_ 157 SCUShiftrLvrPosnLtchActv "ISCUShiftrLvrPosnLtchActv";
BA_ "LongName" SG_ 157 SCUShiftrLvrPosnLtchActv "Shifter Control Unit Shifter Lever Position Latch Active";
BA_ "SysSignalName" SG_ 157 SCUShiftrLvrPosnLtchActv "SCUShiftrLvrPosnLtchActv";
BA_ "CompuMethodName" SG_ 157 SecuKeyVldSts "SecuKeyVldSts";
BA_ "GenSigStartValue" SG_ 157 SecuKeyVldSts 1;
BA_ "ISignalName" SG_ 157 SecuKeyVldSts "ISecuKeyVldSts";
BA_ "LongName" SG_ 157 SecuKeyVldSts "Security Key Valid Status";
BA_ "SysSignalName" SG_ 157 SecuKeyVldSts "SecuKeyVldSts";
BA_ "CompuMethodName" SG_ 157 SCUDrvrIntrvnActv "SCUDrvrIntrvnActv";
BA_ "ISignalName" SG_ 157 SCUDrvrIntrvnActv "ISCUDrvrIntrvnActv";
BA_ "LongName" SG_ 157 SCUDrvrIntrvnActv "Shifter Control Unit Driver Intervention Active";
BA_ "SysSignalName" SG_ 157 SCUDrvrIntrvnActv "SCUDrvrIntrvnActv";
BA_ "CompuMethodName" SG_ 157 SCUAPAUnderCtrlActv "SCUAPAUnderCtrlActv";
BA_ "ISignalName" SG_ 157 SCUAPAUnderCtrlActv "ISCUAPAUnderCtrlActv";
BA_ "LongName" SG_ 157 SCUAPAUnderCtrlActv "Shifter Control Unit Auto Parking Assist Under Control Active";
BA_ "SysSignalName" SG_ 157 SCUAPAUnderCtrlActv "SCUAPAUnderCtrlActv";
BA_ "CompuMethodName" SG_ 157 DigKeyPEValidReq "DigKeyPEValidReq";
BA_ "ISignalName" SG_ 157 DigKeyPEValidReq "IDigKeyPEValidReq";
BA_ "LongName" SG_ 157 DigKeyPEValidReq "Digital Key  Passive enter Valid  Request";
BA_ "SysSignalName" SG_ 157 DigKeyPEValidReq "DigKeyPEValidReq";
BA_ "CompuMethodName" SG_ 299 LHZCU_20ms_Group03_CRC "LHZCU_20ms_Group03_CRC";
BA_ "ISignalName" SG_ 299 LHZCU_20ms_Group03_CRC "ILHZCU_20ms_Group03_CRC";
BA_ "LongName" SG_ 299 LHZCU_20ms_Group03_CRC "LHZCU_20ms_Group03_CRC";
BA_ "SysSignalName" SG_ 299 LHZCU_20ms_Group03_CRC "LHZCU_20ms_Group03_CRC";
BA_ "CompuMethodName" SG_ 299 LHZCU_20ms_Group03_RC "LHZCU_20ms_Group03_RC";
BA_ "ISignalName" SG_ 299 LHZCU_20ms_Group03_RC "ILHZCU_20ms_Group03_RC";
BA_ "LongName" SG_ 299 LHZCU_20ms_Group03_RC "LHZCU_20ms_Group03_RC";
BA_ "SysSignalName" SG_ 299 LHZCU_20ms_Group03_RC "LHZCU_20ms_Group03_RC";
BA_ "CompuMethodName" SG_ 299 LHZCU_20ms_Group03_Reserved1 "LHZCU_20ms_Group03_Reserved1";
BA_ "GenSigStartValue" SG_ 299 LHZCU_20ms_Group03_Reserved1 15;
BA_ "ISignalName" SG_ 299 LHZCU_20ms_Group03_Reserved1 "ILHZCU_20ms_Group03_Reserved1";
BA_ "SysSignalName" SG_ 299 LHZCU_20ms_Group03_Reserved1 "LHZCU_20ms_Group03_Reserved1";
BA_ "CompuMethodName" SG_ 299 LHZCU_20ms_Group03_Reserved2 "LHZCU_20ms_Group03_Reserved2";
BA_ "GenSigStartValue" SG_ 299 LHZCU_20ms_Group03_Reserved2 255;
BA_ "ISignalName" SG_ 299 LHZCU_20ms_Group03_Reserved2 "ILHZCU_20ms_Group03_Reserved2";
BA_ "SysSignalName" SG_ 299 LHZCU_20ms_Group03_Reserved2 "LHZCU_20ms_Group03_Reserved2";
BA_ "CompuMethodName" SG_ 299 LHZCU_20ms_Group03_Reserved3 "LHZCU_20ms_Group03_Reserved3";
BA_ "GenSigStartValue" SG_ 299 LHZCU_20ms_Group03_Reserved3 255;
BA_ "ISignalName" SG_ 299 LHZCU_20ms_Group03_Reserved3 "ILHZCU_20ms_Group03_Reserved3";
BA_ "SysSignalName" SG_ 299 LHZCU_20ms_Group03_Reserved3 "LHZCU_20ms_Group03_Reserved3";
BA_ "CompuMethodName" SG_ 299 LHZCU_20ms_Group03_Reserved4 "LHZCU_20ms_Group03_Reserved4";
BA_ "GenSigStartValue" SG_ 299 LHZCU_20ms_Group03_Reserved4 255;
BA_ "ISignalName" SG_ 299 LHZCU_20ms_Group03_Reserved4 "ILHZCU_20ms_Group03_Reserved4";
BA_ "SysSignalName" SG_ 299 LHZCU_20ms_Group03_Reserved4 "LHZCU_20ms_Group03_Reserved4";
BA_ "CompuMethodName" SG_ 299 LHZCU_20ms_Group03_Reserved6 "LHZCU_20ms_Group03_Reserved6";
BA_ "GenSigStartValue" SG_ 299 LHZCU_20ms_Group03_Reserved6 15;
BA_ "ISignalName" SG_ 299 LHZCU_20ms_Group03_Reserved6 "ILHZCU_20ms_Group03_Reserved6";
BA_ "SysSignalName" SG_ 299 LHZCU_20ms_Group03_Reserved6 "LHZCU_20ms_Group03_Reserved6";
BA_ "CompuMethodName" SG_ 299 DippedBeamActStatus "DippedBeamActStatus";
BA_ "ISignalName" SG_ 299 DippedBeamActStatus "IDippedBeamActStatus";
BA_ "LongName" SG_ 299 DippedBeamActStatus "Dipped Beam Activated Status";
BA_ "SysSignalName" SG_ 299 DippedBeamActStatus "DippedBeamActStatus";
BA_ "CompuMethodName" SG_ 299 LHZCU_20ms_Group03_Reserved5 "LHZCU_20ms_Group03_Reserved5";
BA_ "GenSigStartValue" SG_ 299 LHZCU_20ms_Group03_Reserved5 31;
BA_ "ISignalName" SG_ 299 LHZCU_20ms_Group03_Reserved5 "ILHZCU_20ms_Group03_Reserved5";
BA_ "SysSignalName" SG_ 299 LHZCU_20ms_Group03_Reserved5 "LHZCU_20ms_Group03_Reserved5";
BA_ "CompuMethodName" SG_ 299 RevsLghtCtrl "RevsLghtCtrl";
BA_ "ISignalName" SG_ 299 RevsLghtCtrl "IRevsLghtCtrl";
BA_ "LongName" SG_ 299 RevsLghtCtrl "Reverse_Light_Control";
BA_ "SysSignalName" SG_ 299 RevsLghtCtrl "RevsLghtCtrl";
BA_ "CompuMethodName" SG_ 299 PriySSBA "PriySSBA";
BA_ "ISignalName" SG_ 299 PriySSBA "IPriySSBA";
BA_ "LongName" SG_ 299 PriySSBA "Primary_Start_Stop_Button_Active";
BA_ "SysSignalName" SG_ 299 PriySSBA "PriySSBA";
BA_ "CompuMethodName" SG_ 299 PriySSBAV "PriySSBAV";
BA_ "ISignalName" SG_ 299 PriySSBAV "IPriySSBAV";
BA_ "LongName" SG_ 299 PriySSBAV "Primary_Start_Stop_Button_Active_Validity";
BA_ "SysSignalName" SG_ 299 PriySSBAV "PriySSBAV";
BA_ "CompuMethodName" SG_ 299 SecySSBA "SecySSBA";
BA_ "ISignalName" SG_ 299 SecySSBA "ISecySSBA";
BA_ "LongName" SG_ 299 SecySSBA "Secondary_Start_Stop_Button_Active";
BA_ "SysSignalName" SG_ 299 SecySSBA "SecySSBA";
BA_ "CompuMethodName" SG_ 299 SecySSBAV "SecySSBAV";
BA_ "ISignalName" SG_ 299 SecySSBAV "ISecySSBAV";
BA_ "LongName" SG_ 299 SecySSBAV "Secondary_Start_Stop_Button_Active_Validity";
BA_ "SysSignalName" SG_ 299 SecySSBAV "SecySSBAV";
BA_ "CompuMethodName" SG_ 299 SSBTrigd "SSBTrigd";
BA_ "ISignalName" SG_ 299 SSBTrigd "ISSBTrigd";
BA_ "LongName" SG_ 299 SSBTrigd "Start Stop Button Triggered";
BA_ "SysSignalName" SG_ 299 SSBTrigd "SSBTrigd";
BA_ "CompuMethodName" SG_ 299 RMainBeamLghtCtrl "RMainBeamLghtCtrl";
BA_ "ISignalName" SG_ 299 RMainBeamLghtCtrl "IRMainBeamLghtCtrl";
BA_ "LongName" SG_ 299 RMainBeamLghtCtrl "Right_Main_beam_Light _Control";
BA_ "SysSignalName" SG_ 299 RMainBeamLghtCtrl "RMainBeamLghtCtrl";
BA_ "CompuMethodName" SG_ 299 LMainBeamLghtCtrl "LMainBeamLghtCtrl";
BA_ "ISignalName" SG_ 299 LMainBeamLghtCtrl "ILMainBeamLghtCtrl";
BA_ "LongName" SG_ 299 LMainBeamLghtCtrl "Left_Main_beam_Light _Control";
BA_ "SysSignalName" SG_ 299 LMainBeamLghtCtrl "LMainBeamLghtCtrl";
BA_ "CompuMethodName" SG_ 299 RRDircnLghtCtrl "RRDircnLghtCtrl";
BA_ "ISignalName" SG_ 299 RRDircnLghtCtrl "IRRDircnLghtCtrl";
BA_ "LongName" SG_ 299 RRDircnLghtCtrl "Right_Rear_Direction_Light_Control";
BA_ "SysSignalName" SG_ 299 RRDircnLghtCtrl "RRDircnLghtCtrl";
BA_ "CompuMethodName" SG_ 299 RLDircnLghtCtrl "RLDircnLghtCtrl";
BA_ "ISignalName" SG_ 299 RLDircnLghtCtrl "IRLDircnLghtCtrl";
BA_ "LongName" SG_ 299 RLDircnLghtCtrl "Left_Rear_Direction_Light_Control";
BA_ "SysSignalName" SG_ 299 RLDircnLghtCtrl "RLDircnLghtCtrl";
BA_ "CompuMethodName" SG_ 299 FRDircnLghtCtrl "FRDircnLghtCtrl";
BA_ "ISignalName" SG_ 299 FRDircnLghtCtrl "IFRDircnLghtCtrl";
BA_ "LongName" SG_ 299 FRDircnLghtCtrl "Right_Front_Direction_Light_Control";
BA_ "SysSignalName" SG_ 299 FRDircnLghtCtrl "FRDircnLghtCtrl";
BA_ "CompuMethodName" SG_ 299 FLDircnLghtCtrl "FLDircnLghtCtrl";
BA_ "ISignalName" SG_ 299 FLDircnLghtCtrl "IFLDircnLghtCtrl";
BA_ "LongName" SG_ 299 FLDircnLghtCtrl "Left_Front_Direction_Light_Control";
BA_ "SysSignalName" SG_ 299 FLDircnLghtCtrl "FLDircnLghtCtrl";
BA_ "CompuMethodName" SG_ 299 BrkLghtCtrl "BrkLghtCtrl";
BA_ "ISignalName" SG_ 299 BrkLghtCtrl "IBrkLghtCtrl";
BA_ "LongName" SG_ 299 BrkLghtCtrl "Brake_Light_Control";
BA_ "SysSignalName" SG_ 299 BrkLghtCtrl "BrkLghtCtrl";
BA_ "CompuMethodName" SG_ 299 HzrdLghtSwReq "HzrdLghtSwReq";
BA_ "ISignalName" SG_ 299 HzrdLghtSwReq "IHzrdLghtSwReq";
BA_ "LongName" SG_ 299 HzrdLghtSwReq "Hazard_Light_Switch_Request";
BA_ "SysSignalName" SG_ 299 HzrdLghtSwReq "HzrdLghtSwReq";
VAL_ 1202 IPD_NM_BSMtoRMS_BKPCANFD 0 "IPD_NM_BSMtoRMS_BKPCANFD_0_False" 1 "IPD_NM_BSMtoRMS_BKPCANFD_1_True";
VAL_ 1202 IPD_NM_PBSMtoRMS_BKPCANFD 0 "IPD_NM_PBSMtoRMS_BKPCANFD_0_False" 1 "IPD_NM_PBSMtoRMS_BKPCANFD_1_True";
VAL_ 1202 IPD_NM_RMStoNOS_BKPCANFD 0 "IPD_NM_RMStoNOS_BKPCANFD_0_False" 1 "IPD_NM_RMStoNOS_BKPCANFD_1_True";
VAL_ 1202 IPD_NM_RSStoNOS_BKPCANFD 0 "IPD_NM_RSStoNOS_BKPCANFD_0_False" 1 "IPD_NM_RSStoNOS_BKPCANFD_1_True";
VAL_ 1202 IPD_NM_RSStoRMS_BKPCANFD 0 "IPD_NM_RSStoRMS_BKPCANFD_0_False" 1 "IPD_NM_RSStoRMS_BKPCANFD_1_True";
VAL_ 1202 IPD_NM_NOStoRMS_BKPCANFD 0 "IPD_NM_NOStoRMS_BKPCANFD_0_False" 1 "IPD_NM_NOStoRMS_BKPCANFD_1_True";
VAL_ 1202 IPD_NM_NOSSta_BKPCANFD 0 "IPD_NM_NOSSta_BKPCANFD_0_False" 1 "IPD_NM_NOSSta_BKPCANFD_1_True";
VAL_ 1202 IPD_NM_RMSSta_BKPCANFD 0 "IPD_NM_RMSSta_BKPCANFD_0_False" 1 "IPD_NM_RMSSta_BKPCANFD_1_True";
VAL_ 1202 IPD_NWI_BKPCANFD 0 "IPD_NWI_BKPCANFD_0_NoWakeNetworkSource";
VAL_ 1202 IPD_NOI_BKPCANFD 0 "IPD_NOI_BKPCANFD_0_NoRequest" 65535 "IPD_NOI_BKPCANFD_65535_AllNetworkOperationActive";
VAL_ 1202 IPD_NKI_BKPCANFD 0 "IPD_NKI_BKPCANFD_0_NoRequest" 1 "IPD_NKI_BKPCANFD_1_PowerModeIsNonOFF" 2 "IPD_NKI_BKPCANFD_2_DOW" 3 "IPD_NKI_BKPCANFD_3_RPA";
VAL_ 705 RASysSts 0 "RASysSts_0_Off" 1 "RASysSts_1_Standby" 2 "RASysSts_2_Active" 3 "RASysSts_3_Quit" 4 "RASysSts_4_Error" 5 "RASysSts_5_Pause" 6 "RASysSts_6_Complete" 7 "RASysSts_7_Passive";
VAL_ 705 HWPEMStsForEdr 0 "HWPEMStsForEdr_0_Off" 1 "HWPEMStsForEdr_1_On_but_Not_Intervening" 2 "HWPEMStsForEdr_2_Warning_but_Not_Intervening" 3 "HWPEMStsForEdr_3_Intervening" 4 "HWPEMStsForEdr_4_Faulted" 5 "HWPEMStsForEdr_5_Reserved" 6 "HWPEMStsForEdr_6_Reserved" 7 "HWPEMStsForEdr_7_Non_Function";
VAL_ 705 HWPEMSts 0 "HWPEMSts_0_Off" 1 "HWPEMSts_1_On_but_Not_Intervening" 2 "HWPEMSts_2_Warning_but_Not_Intervening" 3 "HWPEMSts_3_Intervening" 4 "HWPEMSts_4_Faulted" 5 "HWPEMSts_5_Reserved" 6 "HWPEMSts_6_Reserved" 7 "HWPEMSts_7_Non_Function";
VAL_ 982 ACCDetObjRisk 0 "ACCDetObjRisk_0_NoRisk" 1 "ACCDetObjRisk_1_RiskExist";
VAL_ 982 ACCDetObjTyp 0 "ACCDetObjTyp_0_Unknown" 1 "ACCDetObjTyp_1_Car" 2 "ACCDetObjTyp_2_Truck" 3 "ACCDetObjTyp_3_Motorbike" 4 "ACCDetObjTyp_4_Bicycle" 5 "ACCDetObjTyp_5_Reserved" 6 "ACCDetObjTyp_6_Reserved" 7 "ACCDetObjTyp_7_Reserved";
VAL_ 960 IPDThermalWrnngLvl 0 "IPDThermalWrnngLvl_0_Normal" 1 "IPDThermalWrnngLvl_1_Thermal_warning_level_1" 2 "IPDThermalWrnngLvl_2_Thermal_warning_level_2" 3 "IPDThermalWrnngLvl_3__Invalid_Value" 4 "IPDThermalWrnngLvl_4__Invalid_Value" 5 "IPDThermalWrnngLvl_5__Invalid_Value" 6 "IPDThermalWrnngLvl_6__Invalid_Value" 7 "IPDThermalWrnngLvl_7__Invalid_Value" 8 "IPDThermalWrnngLvl_8__Invalid_Value" 9 "IPDThermalWrnngLvl_9__Invalid_Value" 10 "IPDThermalWrnngLvl_10__Invalid_Value" 11 "IPDThermalWrnngLvl_11__Invalid_Value" 12 "IPDThermalWrnngLvl_12__Invalid_Value" 13 "IPDThermalWrnngLvl_13__Invalid_Value" 14 "IPDThermalWrnngLvl_14__Invalid_Value" 15 "IPDThermalWrnngLvl_15__Invalid_Value" 16 "IPDThermalWrnngLvl_16__Invalid_Value" 17 "IPDThermalWrnngLvl_17__Invalid_Value" 18 "IPDThermalWrnngLvl_18__Invalid_Value" 19 "IPDThermalWrnngLvl_19__Invalid_Value" 20 "IPDThermalWrnngLvl_20__Invalid_Value" 21 "IPDThermalWrnngLvl_21__Invalid_Value" 22 "IPDThermalWrnngLvl_22__Invalid_Value" 23 "IPDThermalWrnngLvl_23__Invalid_Value" 24 "IPDThermalWrnngLvl_24__Invalid_Value" 25 "IPDThermalWrnngLvl_25__Invalid_Value" 26 "IPDThermalWrnngLvl_26__Invalid_Value" 27 "IPDThermalWrnngLvl_27__Invalid_Value" 28 "IPDThermalWrnngLvl_28__Invalid_Value" 29 "IPDThermalWrnngLvl_29__Invalid_Value" 30 "IPDThermalWrnngLvl_30__Invalid_Value" 31 "IPDThermalWrnngLvl_31__Invalid_Value" 32 "IPDThermalWrnngLvl_32__Invalid_Value" 33 "IPDThermalWrnngLvl_33__Invalid_Value" 34 "IPDThermalWrnngLvl_34__Invalid_Value" 35 "IPDThermalWrnngLvl_35__Invalid_Value" 36 "IPDThermalWrnngLvl_36__Invalid_Value" 37 "IPDThermalWrnngLvl_37__Invalid_Value" 38 "IPDThermalWrnngLvl_38__Invalid_Value" 39 "IPDThermalWrnngLvl_39__Invalid_Value" 40 "IPDThermalWrnngLvl_40__Invalid_Value" 41 "IPDThermalWrnngLvl_41__Invalid_Value" 42 "IPDThermalWrnngLvl_42__Invalid_Value" 43 "IPDThermalWrnngLvl_43__Invalid_Value" 44 "IPDThermalWrnngLvl_44__Invalid_Value" 45 "IPDThermalWrnngLvl_45__Invalid_Value" 46 "IPDThermalWrnngLvl_46__Invalid_Value" 47 "IPDThermalWrnngLvl_47__Invalid_Value" 48 "IPDThermalWrnngLvl_48__Invalid_Value" 49 "IPDThermalWrnngLvl_49__Invalid_Value" 50 "IPDThermalWrnngLvl_50__Invalid_Value" 51 "IPDThermalWrnngLvl_51__Invalid_Value" 52 "IPDThermalWrnngLvl_52__Invalid_Value" 53 "IPDThermalWrnngLvl_53__Invalid_Value" 54 "IPDThermalWrnngLvl_54__Invalid_Value" 55 "IPDThermalWrnngLvl_55__Invalid_Value" 56 "IPDThermalWrnngLvl_56__Invalid_Value" 57 "IPDThermalWrnngLvl_57__Invalid_Value" 58 "IPDThermalWrnngLvl_58__Invalid_Value" 59 "IPDThermalWrnngLvl_59__Invalid_Value" 60 "IPDThermalWrnngLvl_60__Invalid_Value" 61 "IPDThermalWrnngLvl_61__Invalid_Value" 62 "IPDThermalWrnngLvl_62__Invalid_Value" 63 "IPDThermalWrnngLvl_63__Invalid_Value" 64 "IPDThermalWrnngLvl_64__Invalid_Value" 65 "IPDThermalWrnngLvl_65__Invalid_Value" 66 "IPDThermalWrnngLvl_66__Invalid_Value" 67 "IPDThermalWrnngLvl_67__Invalid_Value" 68 "IPDThermalWrnngLvl_68__Invalid_Value" 69 "IPDThermalWrnngLvl_69__Invalid_Value" 70 "IPDThermalWrnngLvl_70__Invalid_Value" 71 "IPDThermalWrnngLvl_71__Invalid_Value" 72 "IPDThermalWrnngLvl_72__Invalid_Value" 73 "IPDThermalWrnngLvl_73__Invalid_Value" 74 "IPDThermalWrnngLvl_74__Invalid_Value" 75 "IPDThermalWrnngLvl_75__Invalid_Value" 76 "IPDThermalWrnngLvl_76__Invalid_Value" 77 "IPDThermalWrnngLvl_77__Invalid_Value" 78 "IPDThermalWrnngLvl_78__Invalid_Value" 79 "IPDThermalWrnngLvl_79__Invalid_Value" 80 "IPDThermalWrnngLvl_80__Invalid_Value" 81 "IPDThermalWrnngLvl_81__Invalid_Value" 82 "IPDThermalWrnngLvl_82__Invalid_Value" 83 "IPDThermalWrnngLvl_83__Invalid_Value" 84 "IPDThermalWrnngLvl_84__Invalid_Value" 85 "IPDThermalWrnngLvl_85__Invalid_Value" 86 "IPDThermalWrnngLvl_86__Invalid_Value" 87 "IPDThermalWrnngLvl_87__Invalid_Value" 88 "IPDThermalWrnngLvl_88__Invalid_Value" 89 "IPDThermalWrnngLvl_89__Invalid_Value" 90 "IPDThermalWrnngLvl_90__Invalid_Value" 91 "IPDThermalWrnngLvl_91__Invalid_Value" 92 "IPDThermalWrnngLvl_92__Invalid_Value" 93 "IPDThermalWrnngLvl_93__Invalid_Value" 94 "IPDThermalWrnngLvl_94__Invalid_Value" 95 "IPDThermalWrnngLvl_95__Invalid_Value" 96 "IPDThermalWrnngLvl_96__Invalid_Value" 97 "IPDThermalWrnngLvl_97__Invalid_Value" 98 "IPDThermalWrnngLvl_98__Invalid_Value" 99 "IPDThermalWrnngLvl_99__Invalid_Value" 100 "IPDThermalWrnngLvl_100__Invalid_Value" 101 "IPDThermalWrnngLvl_101__Invalid_Value" 102 "IPDThermalWrnngLvl_102__Invalid_Value" 103 "IPDThermalWrnngLvl_103__Invalid_Value" 104 "IPDThermalWrnngLvl_104__Invalid_Value" 105 "IPDThermalWrnngLvl_105__Invalid_Value" 106 "IPDThermalWrnngLvl_106__Invalid_Value" 107 "IPDThermalWrnngLvl_107__Invalid_Value" 108 "IPDThermalWrnngLvl_108__Invalid_Value" 109 "IPDThermalWrnngLvl_109__Invalid_Value" 110 "IPDThermalWrnngLvl_110__Invalid_Value" 111 "IPDThermalWrnngLvl_111__Invalid_Value" 112 "IPDThermalWrnngLvl_112__Invalid_Value" 113 "IPDThermalWrnngLvl_113__Invalid_Value" 114 "IPDThermalWrnngLvl_114__Invalid_Value" 115 "IPDThermalWrnngLvl_115__Invalid_Value" 116 "IPDThermalWrnngLvl_116__Invalid_Value" 117 "IPDThermalWrnngLvl_117__Invalid_Value" 118 "IPDThermalWrnngLvl_118__Invalid_Value" 119 "IPDThermalWrnngLvl_119__Invalid_Value" 120 "IPDThermalWrnngLvl_120__Invalid_Value" 121 "IPDThermalWrnngLvl_121__Invalid_Value" 122 "IPDThermalWrnngLvl_122__Invalid_Value" 123 "IPDThermalWrnngLvl_123__Invalid_Value" 124 "IPDThermalWrnngLvl_124__Invalid_Value" 125 "IPDThermalWrnngLvl_125__Invalid_Value" 126 "IPDThermalWrnngLvl_126__Invalid_Value" 127 "IPDThermalWrnngLvl_127__Invalid_Value" 128 "IPDThermalWrnngLvl_128__Invalid_Value" 129 "IPDThermalWrnngLvl_129__Invalid_Value" 130 "IPDThermalWrnngLvl_130__Invalid_Value" 131 "IPDThermalWrnngLvl_131__Invalid_Value" 132 "IPDThermalWrnngLvl_132__Invalid_Value" 133 "IPDThermalWrnngLvl_133__Invalid_Value" 134 "IPDThermalWrnngLvl_134__Invalid_Value" 135 "IPDThermalWrnngLvl_135__Invalid_Value" 136 "IPDThermalWrnngLvl_136__Invalid_Value" 137 "IPDThermalWrnngLvl_137__Invalid_Value" 138 "IPDThermalWrnngLvl_138__Invalid_Value" 139 "IPDThermalWrnngLvl_139__Invalid_Value" 140 "IPDThermalWrnngLvl_140__Invalid_Value" 141 "IPDThermalWrnngLvl_141__Invalid_Value" 142 "IPDThermalWrnngLvl_142__Invalid_Value" 143 "IPDThermalWrnngLvl_143__Invalid_Value" 144 "IPDThermalWrnngLvl_144__Invalid_Value" 145 "IPDThermalWrnngLvl_145__Invalid_Value" 146 "IPDThermalWrnngLvl_146__Invalid_Value" 147 "IPDThermalWrnngLvl_147__Invalid_Value" 148 "IPDThermalWrnngLvl_148__Invalid_Value" 149 "IPDThermalWrnngLvl_149__Invalid_Value" 150 "IPDThermalWrnngLvl_150__Invalid_Value" 151 "IPDThermalWrnngLvl_151__Invalid_Value" 152 "IPDThermalWrnngLvl_152__Invalid_Value" 153 "IPDThermalWrnngLvl_153__Invalid_Value" 154 "IPDThermalWrnngLvl_154__Invalid_Value" 155 "IPDThermalWrnngLvl_155__Invalid_Value" 156 "IPDThermalWrnngLvl_156__Invalid_Value" 157 "IPDThermalWrnngLvl_157__Invalid_Value" 158 "IPDThermalWrnngLvl_158__Invalid_Value" 159 "IPDThermalWrnngLvl_159__Invalid_Value" 160 "IPDThermalWrnngLvl_160__Invalid_Value" 161 "IPDThermalWrnngLvl_161__Invalid_Value" 162 "IPDThermalWrnngLvl_162__Invalid_Value" 163 "IPDThermalWrnngLvl_163__Invalid_Value" 164 "IPDThermalWrnngLvl_164__Invalid_Value" 165 "IPDThermalWrnngLvl_165__Invalid_Value" 166 "IPDThermalWrnngLvl_166__Invalid_Value" 167 "IPDThermalWrnngLvl_167__Invalid_Value" 168 "IPDThermalWrnngLvl_168__Invalid_Value" 169 "IPDThermalWrnngLvl_169__Invalid_Value" 170 "IPDThermalWrnngLvl_170__Invalid_Value" 171 "IPDThermalWrnngLvl_171__Invalid_Value" 172 "IPDThermalWrnngLvl_172__Invalid_Value" 173 "IPDThermalWrnngLvl_173__Invalid_Value" 174 "IPDThermalWrnngLvl_174__Invalid_Value" 175 "IPDThermalWrnngLvl_175__Invalid_Value" 176 "IPDThermalWrnngLvl_176__Invalid_Value" 177 "IPDThermalWrnngLvl_177__Invalid_Value" 178 "IPDThermalWrnngLvl_178__Invalid_Value" 179 "IPDThermalWrnngLvl_179__Invalid_Value" 180 "IPDThermalWrnngLvl_180__Invalid_Value" 181 "IPDThermalWrnngLvl_181__Invalid_Value" 182 "IPDThermalWrnngLvl_182__Invalid_Value" 183 "IPDThermalWrnngLvl_183__Invalid_Value" 184 "IPDThermalWrnngLvl_184__Invalid_Value" 185 "IPDThermalWrnngLvl_185__Invalid_Value" 186 "IPDThermalWrnngLvl_186__Invalid_Value" 187 "IPDThermalWrnngLvl_187__Invalid_Value" 188 "IPDThermalWrnngLvl_188__Invalid_Value" 189 "IPDThermalWrnngLvl_189__Invalid_Value" 190 "IPDThermalWrnngLvl_190__Invalid_Value" 191 "IPDThermalWrnngLvl_191__Invalid_Value" 192 "IPDThermalWrnngLvl_192__Invalid_Value" 193 "IPDThermalWrnngLvl_193__Invalid_Value" 194 "IPDThermalWrnngLvl_194__Invalid_Value" 195 "IPDThermalWrnngLvl_195__Invalid_Value" 196 "IPDThermalWrnngLvl_196__Invalid_Value" 197 "IPDThermalWrnngLvl_197__Invalid_Value" 198 "IPDThermalWrnngLvl_198__Invalid_Value" 199 "IPDThermalWrnngLvl_199__Invalid_Value" 200 "IPDThermalWrnngLvl_200__Invalid_Value" 201 "IPDThermalWrnngLvl_201__Invalid_Value" 202 "IPDThermalWrnngLvl_202__Invalid_Value" 203 "IPDThermalWrnngLvl_203__Invalid_Value" 204 "IPDThermalWrnngLvl_204__Invalid_Value" 205 "IPDThermalWrnngLvl_205__Invalid_Value" 206 "IPDThermalWrnngLvl_206__Invalid_Value" 207 "IPDThermalWrnngLvl_207__Invalid_Value" 208 "IPDThermalWrnngLvl_208__Invalid_Value" 209 "IPDThermalWrnngLvl_209__Invalid_Value" 210 "IPDThermalWrnngLvl_210__Invalid_Value" 211 "IPDThermalWrnngLvl_211__Invalid_Value" 212 "IPDThermalWrnngLvl_212__Invalid_Value" 213 "IPDThermalWrnngLvl_213__Invalid_Value" 214 "IPDThermalWrnngLvl_214__Invalid_Value" 215 "IPDThermalWrnngLvl_215__Invalid_Value" 216 "IPDThermalWrnngLvl_216__Invalid_Value" 217 "IPDThermalWrnngLvl_217__Invalid_Value" 218 "IPDThermalWrnngLvl_218__Invalid_Value" 219 "IPDThermalWrnngLvl_219__Invalid_Value" 220 "IPDThermalWrnngLvl_220__Invalid_Value" 221 "IPDThermalWrnngLvl_221__Invalid_Value" 222 "IPDThermalWrnngLvl_222__Invalid_Value" 223 "IPDThermalWrnngLvl_223__Invalid_Value" 224 "IPDThermalWrnngLvl_224__Invalid_Value" 225 "IPDThermalWrnngLvl_225__Invalid_Value" 226 "IPDThermalWrnngLvl_226__Invalid_Value" 227 "IPDThermalWrnngLvl_227__Invalid_Value" 228 "IPDThermalWrnngLvl_228__Invalid_Value" 229 "IPDThermalWrnngLvl_229__Invalid_Value" 230 "IPDThermalWrnngLvl_230__Invalid_Value" 231 "IPDThermalWrnngLvl_231__Invalid_Value" 232 "IPDThermalWrnngLvl_232__Invalid_Value" 233 "IPDThermalWrnngLvl_233__Invalid_Value" 234 "IPDThermalWrnngLvl_234__Invalid_Value" 235 "IPDThermalWrnngLvl_235__Invalid_Value" 236 "IPDThermalWrnngLvl_236__Invalid_Value" 237 "IPDThermalWrnngLvl_237__Invalid_Value" 238 "IPDThermalWrnngLvl_238__Invalid_Value" 239 "IPDThermalWrnngLvl_239__Invalid_Value" 240 "IPDThermalWrnngLvl_240__Invalid_Value" 241 "IPDThermalWrnngLvl_241__Invalid_Value" 242 "IPDThermalWrnngLvl_242__Invalid_Value" 243 "IPDThermalWrnngLvl_243__Invalid_Value" 244 "IPDThermalWrnngLvl_244__Invalid_Value" 245 "IPDThermalWrnngLvl_245__Invalid_Value" 246 "IPDThermalWrnngLvl_246__Invalid_Value" 247 "IPDThermalWrnngLvl_247__Invalid_Value" 248 "IPDThermalWrnngLvl_248__Invalid_Value" 249 "IPDThermalWrnngLvl_249__Invalid_Value" 250 "IPDThermalWrnngLvl_250__Invalid_Value" 251 "IPDThermalWrnngLvl_251__Invalid_Value" 252 "IPDThermalWrnngLvl_252__Invalid_Value" 253 "IPDThermalWrnngLvl_253__Invalid_Value" 254 "IPDThermalWrnngLvl_254__Invalid_Value" 255 "IPDThermalWrnngLvl_255__Invalid_Value";
VAL_ 960 IPDPMICTemp 255 "IPDPMICTemp_255_Invalid_Value";
VAL_ 960 IPDPCBTemp2 255 "IPDPCBTemp2_255_Invalid_Value";
VAL_ 960 IPDPCBTemp1 255 "IPDPCBTemp1_255_Invalid_Value";
VAL_ 960 IPDSOCTemp 255 "IPDSOCTemp_255_Invalid_Value";
VAL_ 960 IPDAurixTemp 255 "IPDAurixTemp_255_Invalid_Value";
VAL_ 1231 LFSDA_NM_BSMtoRMS_BKPCANFD 0 "LFSDA_NM_BSMtoRMS_BKPCANFD_0_LFSDA_NM_BSMtoRMS_0_False" 1 "LFSDA_NM_BSMtoRMS_BKPCANFD_1_LFSDA_NM_BSMtoRMS_1_True";
VAL_ 1231 LFSDA_NM_PBSMtoRMS_BKPCANFD 0 "LFSDA_NM_PBSMtoRMS_BKPCANFD_0_LFSDA_NM_PBSMtoRMS_0_False" 1 "LFSDA_NM_PBSMtoRMS_BKPCANFD_1_LFSDA_NM_PBSMtoRMS_1_True";
VAL_ 1231 LFSDA_NM_RMStoNOS_BKPCANFD 0 "LFSDA_NM_RMStoNOS_BKPCANFD_0_LFSDA_NM_RMStoNOS_0_False" 1 "LFSDA_NM_RMStoNOS_BKPCANFD_1_LFSDA_NM_RMStoNOS_1_True";
VAL_ 1231 LFSDA_NM_RSStoNOS_BKPCANFD 0 "LFSDA_NM_RSStoNOS_BKPCANFD_0_LFSDA_NM_RSStoNOS_0_False" 1 "LFSDA_NM_RSStoNOS_BKPCANFD_1_LFSDA_NM_RSStoNOS_1_True";
VAL_ 1231 LFSDA_NM_RSStoRMS_BKPCANFD 0 "LFSDA_NM_RSStoRMS_BKPCANFD_0_LFSDA_NM_RSStoRMS_0_False" 1 "LFSDA_NM_RSStoRMS_BKPCANFD_1_LFSDA_NM_RSStoRMS_1_True";
VAL_ 1231 LFSDA_NM_NOStoRMS_BKPCANFD 0 "LFSDA_NM_NOStoRMS_BKPCANFD_0_LFSDA_NM_NOStoRMS_0_False" 1 "LFSDA_NM_NOStoRMS_BKPCANFD_1_LFSDA_NM_NOStoRMS_1_True";
VAL_ 1231 LFSDA_NM_NOSSta_BKPCANFD 0 "LFSDA_NM_NOSSta_BKPCANFD_0_LFSDA_NM_NOSSta_0_False" 1 "LFSDA_NM_NOSSta_BKPCANFD_1_LFSDA_NM_NOSSta_1_True";
VAL_ 1231 LFSDA_NM_RMSSta_BKPCANFD 0 "LFSDA_NM_RMSSta_BKPCANFD_0_LFSDA_NM_RMSSta_0_False" 1 "LFSDA_NM_RMSSta_BKPCANFD_1_LFSDA_NM_RMSSta_1_True";
VAL_ 1231 LFSDA_NWI_BKPCANFD 0 "LFSDA_NWI_BKPCANFD_0_NoWakeNetworkSource" 1 "LFSDA_NWI_BKPCANFD_1_PowerModeIsNonOFF" 2 "LFSDA_NWI_BKPCANFD_2_OnboardChargerConnected";
VAL_ 1231 LFSDA_NOI_BKPCANFD 0 "LFSDA_NOI_BKPCANFD_0_NoRequest" 65535 "LFSDA_NOI_BKPCANFD_65535_AllNetworkOperationActive";
VAL_ 1231 LFSDA_NKI_BKPCANFD 0 "LFSDA_NKI_BKPCANFD_0_NoRequest" 1 "LFSDA_NKI_BKPCANFD_1_PowerModeIsNonOFF" 2 "LFSDA_NKI_BKPCANFD_2_DOW" 3 "LFSDA_NKI_BKPCANFD_3_RPA";
VAL_ 1229 LHRDA_NM_BSMtoRMS_BKPCANFD 0 "LHRDA_NM_BSMtoRMS_BKPCANFD_0_False" 1 "LHRDA_NM_BSMtoRMS_BKPCANFD_1_True";
VAL_ 1229 LHRDA_NM_PBSMtoRMS_BKPCANFD 0 "LHRDA_NM_PBSMtoRMS_BKPCANFD_0_False" 1 "LHRDA_NM_PBSMtoRMS_BKPCANFD_1_True";
VAL_ 1229 LHRDA_NM_RMStoNOS_BKPCANFD 0 "LHRDA_NM_RMStoNOS_BKPCANFD_0_False" 1 "LHRDA_NM_RMStoNOS_BKPCANFD_1_True";
VAL_ 1229 LHRDA_NM_RSStoNOS_BKPCANFD 0 "LHRDA_NM_RSStoNOS_BKPCANFD_0_False" 1 "LHRDA_NM_RSStoNOS_BKPCANFD_1_True";
VAL_ 1229 LHRDA_NM_RSStoRMS_BKPCANFD 0 "LHRDA_NM_RSStoRMS_BKPCANFD_0_False" 1 "LHRDA_NM_RSStoRMS_BKPCANFD_1_True";
VAL_ 1229 LHRDA_NM_NOStoRMS_BKPCANFD 0 "LHRDA_NM_NOStoRMS_BKPCANFD_0_False" 1 "LHRDA_NM_NOStoRMS_BKPCANFD_1_True";
VAL_ 1229 LHRDA_NM_NOSSta_BKPCANFD 0 "LHRDA_NM_NOSSta_BKPCANFD_0_False" 1 "LHRDA_NM_NOSSta_BKPCANFD_1_True";
VAL_ 1229 LHRDA_NM_RMSSta_BKPCANFD 0 "LHRDA_NM_RMSSta_BKPCANFD_0_False" 1 "LHRDA_NM_RMSSta_BKPCANFD_1_True";
VAL_ 1229 LHRDA_NWI_BKPCANFD 0 "LHRDA_NWI_BKPCANFD_0_NoWakeNetworkSource";
VAL_ 1229 LHRDA_NOI_BKPCANFD 0 "LHRDA_NOI_BKPCANFD_0_NoRequest" 65535 "LHRDA_NOI_BKPCANFD_65535_AllNetworkOperationActive";
VAL_ 1229 LHRDA_NKI_BKPCANFD 0 "LHRDA_NKI_BKPCANFD_0_NoRequest";
VAL_ 995 DircnIndLampSwStsMntry 0 "DircnIndLampSwStsMntry_0_off" 1 "DircnIndLampSwStsMntry_1_LeftshortturnmodeSwitchactive" 2 "DircnIndLampSwStsMntry_2_LeftlongturnmodeSwitchactive" 3 "DircnIndLampSwStsMntry_3_RightShortTurnModeSwitchActive" 4 "DircnIndLampSwStsMntry_4_RightLongTurnModeSwitchActive" 5 "DircnIndLampSwStsMntry_5_UnknowPosition" 6 "DircnIndLampSwStsMntry_6_reserve" 7 "DircnIndLampSwStsMntry_7_reserve";
VAL_ 995 FLSeatHorzPos 254 "FLSeatHorzPos_254_Stop" 255 "FLSeatHorzPos_255_Invalid";
VAL_ 995 FLSeatVertPos 254 "FLSeatVertPos_254_Stop" 255 "FLSeatVertPos_255_Invalid";
VAL_ 181 BrkLghtSwReq 0 "BrkLghtSwReq_0_Off" 1 "BrkLghtSwReq_1_On";
VAL_ 181 SideLghtOnReq 0 "SideLghtOnReq_0_Off" 1 "SideLghtOnReq_1_Front_Side_light_on" 2 "SideLghtOnReq_2_Rear_Side_light_on" 3 "SideLghtOnReq_3_Both_front_and_rear_side_light_on";
VAL_ 181 MainBeamLghtSwReq 0 "MainBeamLghtSwReq_0_Off" 1 "MainBeamLghtSwReq_1_On" 2 "MainBeamLghtSwReq_2_Flash";
VAL_ 181 DrvrReqGearShftPos 0 "DrvrReqGearShftPos_0_Shifter_position_zero_Z_POS_ZERO" 1 "DrvrReqGearShftPos_1_Shifter_position_one_bistable_BZ1_POS_ONE" 2 "DrvrReqGearShftPos_2_Shifter_position_two_forward_twice_X2_POS_TWO" 3 "DrvrReqGearShftPos_3_Shifter_position_three_forward_once_X1_POS_THREE" 4 "DrvrReqGearShftPos_4_Shifter_position_four_backwards_once_Y1_POS_FOUR" 5 "DrvrReqGearShftPos_5_Shifter_position_five_backwards_twice_Y2_POS_FIVE" 6 "DrvrReqGearShftPos_6_Shifter_position_six_bistable_forward_once_BX1_POS_SIX" 7 "DrvrReqGearShftPos_7_Shifter_position_seven_bistable_backwards_once_BY1_POS_SEVEN" 8 "DrvrReqGearShftPos_8_Shifter_not_initialized_INIT" 9 "DrvrReqGearShftPos_9_Reserved" 10 "DrvrReqGearShftPos_10_Reserved" 11 "DrvrReqGearShftPos_11_Reserved" 12 "DrvrReqGearShftPos_12_Reserved" 13 "DrvrReqGearShftPos_13_Reserved" 14 "DrvrReqGearShftPos_14_Reserved" 15 "DrvrReqGearShftPos_15_Signal_not_available_SNA_Double_fault_shifter_sensor";
VAL_ 181 RrFogLightOnReq 0 "RrFogLightOnReq_0_OFF" 1 "RrFogLightOnReq_1_On";
VAL_ 181 RDayTimeRunningLghtCtrl 0 "RDayTimeRunningLghtCtrl_0_Off" 1 "RDayTimeRunningLghtCtrl_1_On";
VAL_ 181 LDayTimeRunningLghtCtrl 0 "LDayTimeRunningLghtCtrl_0_Off" 1 "LDayTimeRunningLghtCtrl_1_On";
VAL_ 181 EleccTrRngReq 0 "EleccTrRngReq_0_SCU_initialization" 1 "EleccTrRngReq_1_Park" 2 "EleccTrRngReq_2_Reverse" 3 "EleccTrRngReq_3_Neutral" 4 "EleccTrRngReq_4_Drive" 5 "EleccTrRngReq_5_Sport_Range" 6 "EleccTrRngReq_6_Manual_Range" 7 "EleccTrRngReq_7_Error";
VAL_ 181 DrvrReqGearShftPosInvs 0 "DrvrReqGearShftPosInvs_0_Signal_not_available_SNA_Double_fault_shifter_sensor" 1 "DrvrReqGearShftPosInvs_1_Reserved" 2 "DrvrReqGearShftPosInvs_2_Reserved" 3 "DrvrReqGearShftPosInvs_3_Reserved" 4 "DrvrReqGearShftPosInvs_4_Reserved" 5 "DrvrReqGearShftPosInvs_5_Reserved" 6 "DrvrReqGearShftPosInvs_6_Reserved" 7 "DrvrReqGearShftPosInvs_7_Shifter_not_initialized_INIT" 8 "DrvrReqGearShftPosInvs_8_Shifter_position_seven_bistable_backwards_once_BY1_POS_SEVEN" 9 "DrvrReqGearShftPosInvs_9_Shifter_position_six_bistable_forward_once_BX1_POS_SIX" 10 "DrvrReqGearShftPosInvs_10_Shifter_position_five_backwards_twice_Y2_POS_FIVE" 11 "DrvrReqGearShftPosInvs_11_Shifter_position_four_backwards_once_Y1_POS_FOUR" 12 "DrvrReqGearShftPosInvs_12_Shifter_position_three_forward_once_X1_POS_THREE" 13 "DrvrReqGearShftPosInvs_13_Shifter_position_two_forward_twice_X2_POS_TWO" 14 "DrvrReqGearShftPosInvs_14_Shifter_position_one_bistable_BZ1_POS_ONE" 15 "DrvrReqGearShftPosInvs_15_Shifter_position_zero_Z_POS_ZERO";
VAL_ 181 DircnLghtOnReq_LHZCU 0 "DircnLghtOnReq_LHZCU_0_Off" 1 "DircnLghtOnReq_LHZCU_1_Left_direction_light_on" 2 "DircnLghtOnReq_LHZCU_2_Right_direction_light_on" 3 "DircnLghtOnReq_LHZCU_3_Both_left_and_right_direction_light_on";
VAL_ 181 SCUDrvnIntrvnPos 0 "SCUDrvnIntrvnPos_0_Initial" 1 "SCUDrvnIntrvnPos_1_S_Sportmode" 2 "SCUDrvnIntrvnPos_2_W_Wintermode" 3 "SCUDrvnIntrvnPos_3_M_Manualmode" 5 "SCUDrvnIntrvnPos_5_D_Drive" 6 "SCUDrvnIntrvnPos_6_N_Neutral" 7 "SCUDrvnIntrvnPos_7_R_Reverse" 8 "SCUDrvnIntrvnPos_8_P_Park" 9 "SCUDrvnIntrvnPos_9_Reserve" 10 "SCUDrvnIntrvnPos_10_Error";
VAL_ 181 SCUShftLvrPosIncnstntFlag 0 "SCUShftLvrPosIncnstntFlag_0_False" 1 "SCUShftLvrPosIncnstntFlag_1_True";
VAL_ 181 SCUShftLvrPosTrgt 0 "SCUShftLvrPosTrgt_0_SCU_initialization" 1 "SCUShftLvrPosTrgt_1__S_Sport_mode" 2 "SCUShftLvrPosTrgt_2__W_Winter_mode" 3 "SCUShftLvrPosTrgt_3__M_Manual_mode" 5 "SCUShftLvrPosTrgt_D_Drive" 6 "SCUShftLvrPosTrgt_6__N_Neutral" 7 "SCUShftLvrPosTrgt_7__R_Reverse" 8 "SCUShftLvrPosTrgt_8__P_Park" 9 "SCUShftLvrPosTrgt_9__In_learn_Process" 10 "SCUShftLvrPosTrgt_10__Error";
VAL_ 181 SCUExtdShifterActrPos 0 "SCUExtdShifterActrPos_0__Position_Detected_Unknow" 1 "SCUExtdShifterActrPos_1__Position_Detected_Park" 2 "SCUExtdShifterActrPos_2__Position_Detected_Reverse" 3 "SCUExtdShifterActrPos_3__Position_Detected_Neutral" 4 "SCUExtdShifterActrPos_4__Position_Detected_Drive" 5 "SCUExtdShifterActrPos_5__Position_Detected_Between_P_R" 6 "SCUExtdShifterActrPos_6__Position_Detected_Between_R_N" 7 "SCUExtdShifterActrPos_7__Position_Detected_Between_N_D" 8 "SCUExtdShifterActrPos_8__Position_Detected_Out_of_Bounds" 9 "SCUExtdShifterActrPos_9__Position_Detected_Release";
VAL_ 181 SCUTapUpDwnSwStaInvsn 0 "SCUTapUpDwnSwStaInvsn_0__Illegal_Up_Down_Switch_State_Active" 1 "SCUTapUpDwnSwStaInvsn_1__Tap_downshift_of_one_gear_in_M_mode" 2 "SCUTapUpDwnSwStaInvsn_2__Tap_upshift_of_one_gear_in_M_mode" 3 "SCUTapUpDwnSwStaInvsn_3__No_Activation";
VAL_ 181 SCUTapUpDwnSwSta 0 "SCUTapUpDwnSwSta_0__No_Activation" 1 "SCUTapUpDwnSwSta_1__Tap_upshift_of_one_gear_in_M_mode" 2 "SCUTapUpDwnSwSta_2__Tap_downshift_of_one_gear_in_Mmode" 3 "SCUTapUpDwnSwSta_3__Illegal_Up_Down_Switch_State_Active";
VAL_ 181 SCUParkActrSts 0 "SCUParkActrSts_0__No_Fault" 1 "SCUParkActrSts_1__Actuator_Fault" 2 "SCUParkActrSts_2__Single_actuator_sensor_fault_safety_yellow_warning" 3 "SCUParkActrSts_3__All_actuator_sensors_fault_safety_red_warning";
VAL_ 181 SCUActrMvmntSts 0 "SCUActrMvmntSts_0__Actuator_Stop" 1 "SCUActrMvmntSts_1__ActuatorGo_out_of_P" 2 "SCUActrMvmntSts_2__Actuator_Go_Into_P" 3 "SCUActrMvmntSts_3_Reserved";
VAL_ 181 SmrtKey4LoctnResp 0 "SmrtKey4LoctnResp_0_no_smart_key_response" 1 "SmrtKey4LoctnResp_1_left_side_pe_area" 2 "SmrtKey4LoctnResp_2_right_side_pe_area" 3 "SmrtKey4LoctnResp_3_front_side_pe_area" 4 "SmrtKey4LoctnResp_4_rear_side_pe_area" 5 "SmrtKey4LoctnResp_5_interior_ps_area" 6 "SmrtKey4LoctnResp_6_immo_area" 7 "SmrtKey4LoctnResp_7_charge_flap_pe_area" 8 "SmrtKey4LoctnResp_8_loadspace_interior_area" 9 "SmrtKey4LoctnResp_9_power_hood_interior_area" 10 "SmrtKey4LoctnResp_10_approach_zone0" 11 "SmrtKey4LoctnResp_11_approach_zone1" 12 "SmrtKey4LoctnResp_12_approach_zone2" 13 "SmrtKey4LoctnResp_13_approach_zone3" 14 "SmrtKey4LoctnResp_14_reserve" 15 "SmrtKey4LoctnResp_15_reserve";
VAL_ 181 SmrtKeyLoctnProc 0 "SmrtKeyLoctnProc_0_Idle" 1 "SmrtKeyLoctnProc_1_four_door_antilock_location_process" 2 "SmrtKeyLoctnProc_2_loadspace_antilock_location_process" 3 "SmrtKeyLoctnProc_3_power_hood_antilock_location_process" 4 "SmrtKeyLoctnProc_4_take_kay_out_reminder_location_process" 5 "SmrtKeyLoctnProc_5_vehicle_speed_over_15km_h_location_process" 6 "SmrtKeyLoctnProc_6_left_side_pe_location_process" 7 "SmrtKeyLoctnProc_7_right_side_pe_location_process" 8 "SmrtKeyLoctnProc_8_loadspace_pe_location_process" 9 "SmrtKeyLoctnProc_9_power_hood_pe_location_process" 10 "SmrtKeyLoctnProc_10_Charge_Flap_pe_location_process" 11 "SmrtKeyLoctnProc_11_ps_location_process_auth_one" 12 "SmrtKeyLoctnProc_12_interior_location_process_loc_all";
VAL_ 181 LHZCUWKSTS 0 "LHZCUWKSTS_0_False" 1 "LHZCUWKSTS_1_True";
VAL_ 181 SmrtKeyLoctnFlrRsn 0 "SmrtKeyLoctnFlrRsn_0_not_fail" 1 "SmrtKeyLoctnFlrRsn_1_CRC_check_failed" 2 "SmrtKeyLoctnFlrRsn_2_RSSI_out_of_range" 3 "SmrtKeyLoctnFlrRsn_3_encryption_decryption_failed" 4 "SmrtKeyLoctnFlrRsn_4_LF_chip_fault" 5 "SmrtKeyLoctnFlrRsn_5_RF_communication_lost" 6 "SmrtKeyLoctnFlrRsn_6_invalid_command" 7 "SmrtKeyLoctnFlrRsn_7_RF_response_timeout_nonMinuscommunication_fault" 8 "SmrtKeyLoctnFlrRsn_8_reserve" 9 "SmrtKeyLoctnFlrRsn_9_reserve" 10 "SmrtKeyLoctnFlrRsn_10_reserve" 11 "SmrtKeyLoctnFlrRsn_11_reserve" 12 "SmrtKeyLoctnFlrRsn_12_reserve" 13 "SmrtKeyLoctnFlrRsn_13_reserve" 14 "SmrtKeyLoctnFlrRsn_14_reserve" 15 "SmrtKeyLoctnFlrRsn_15_reserve";
VAL_ 1149 TPMSAutoLoctnCm 0 "TPMSAutoLoctnCm_0_False" 1 "TPMSAutoLoctnCm_1_True";
VAL_ 1149 FRTireSts 0 "FRTireSts_0_Normal" 1 "FRTireSts_1_Unkown" 2 "FRTireSts_2_Pressure_Low" 3 "FRTireSts_3_Quick_leak" 4 "FRTireSts_4_Pressure_High" 5 "FRTireSts_5_Temperature_High" 6 "FRTireSts_6_Axle_Pressure_imbalance" 7 "FRTireSts_7_Battery_Low";
VAL_ 1149 FLTireSts 0 "FLTireSts_0_Normal" 1 "FLTireSts_1_Unkown" 2 "FLTireSts_2_Pressure_Low" 3 "FLTireSts_3_Quick_leak" 4 "FLTireSts_4_Pressure_High" 5 "FLTireSts_5_Temperature_High" 6 "FLTireSts_6_Axle_Pressure_imbalance" 7 "FLTireSts_7_Battery_Low";
VAL_ 1149 TPMSIdficnLrnCm 0 "TPMSIdficnLrnCm_0_False" 1 "TPMSIdficnLrnCm_1_True";
VAL_ 1149 RRTireSts 0 "RRTireSts_0_Normal" 1 "RRTireSts_1_Unkown" 2 "RRTireSts_2_Pressure_Low" 3 "RRTireSts_3_Quick_leak" 4 "RRTireSts_4_Pressure_High" 5 "RRTireSts_5_Temperature_High" 6 "RRTireSts_6_Axle_Pressure_imbalance" 7 "RRTireSts_7_Battery_Low";
VAL_ 1149 RLTireSts 0 "RLTireSts_0_Normal" 1 "RLTireSts_1_Unkown" 2 "RLTireSts_2_Pressure_Low" 3 "RLTireSts_3_Quick_leak" 4 "RLTireSts_4_Pressure_High" 5 "RLTireSts_5_Temperature_High" 6 "RLTireSts_6_Axle_Pressure_imbalance" 7 "RLTireSts_7_Battery_Low";
VAL_ 1149 TPMSWntrMdA 0 "TPMSWntrMdA_0_False" 1 "TPMSWntrMdA_1_True";
VAL_ 1149 RLTirePrsV 0 "RLTirePrsV_0_Valid" 1 "RLTirePrsV_1_Invalid";
VAL_ 1149 FRTirePrsV 0 "FRTirePrsV_0_Valid" 1 "FRTirePrsV_1_Invalid";
VAL_ 1149 RRTirePrsV 0 "RRTirePrsV_0_Valid" 1 "RRTirePrsV_1_Invalid";
VAL_ 1149 FLTirePrsV 0 "FLTirePrsV_0_Valid" 1 "FLTirePrsV_1_Invalid";
VAL_ 1148 FLTireTemV 0 "FLTireTemV_0_Valid" 1 "FLTireTemV_1_Invalid";
VAL_ 1148 FRTireTemV 0 "FRTireTemV_0_Valid" 1 "FRTireTemV_1_Invalid";
VAL_ 1148 RLTireTemV 0 "RLTireTemV_0_Valid" 1 "RLTireTemV_1_Invalid";
VAL_ 1148 RRTireTemV 0 "RRTireTemV_0_Valid" 1 "RRTireTemV_1_Invalid";
VAL_ 638 VehHzrdMdSts 0 "VehHzrdMdSts_0_No_Request" 1 "VehHzrdMdSts_1_Manual_Mode" 2 "VehHzrdMdSts_2_Collision_Mode" 3 "VehHzrdMdSts_3_SHWA_Mode" 4 "VehHzrdMdSts_4_RCW_Mode" 5 "VehHzrdMdSts_5_AI_Pilot_Warning_Mode" 6 "VehHzrdMdSts_6_Battery_Thermal_Malfunction" 7 "VehHzrdMdSts_7_Emergency_Brake" 8 "VehHzrdMdSts_8_Alarm_trigger" 9 "VehHzrdMdSts_9_Find_my_car" 10 "VehHzrdMdSts_10_reserve" 11 "VehHzrdMdSts_11_reserve";
VAL_ 638 VehIlluminateCtrlCmd 0 "VehIlluminateCtrlCmd_0_Close" 1 "VehIlluminateCtrlCmd_1_Open";
VAL_ 638 BrkLghtSta 0 "BrkLghtSta_0_Off" 1 "BrkLghtSta_1_On";
VAL_ 638 BrkLghtFltSta 0 "BrkLghtFltSta_0_False" 1 "BrkLghtFltSta_1_True";
VAL_ 638 DircnLghtSts 0 "DircnLghtSts_0_OFF" 1 "DircnLghtSts_1_Left_Direction_Light_On" 2 "DircnLghtSts_2_Right_Direction_Light_On" 3 "DircnLghtSts_3_Both_Side_Direction_Light_On" 4 "DircnLghtSts_4_Reserved";
VAL_ 638 DircnLghtMdSts 0 "DircnLghtMdSts_0__Enabled" 1 "DircnLghtMdSts_1__Disabled";
VAL_ 638 RRSideLghtCtrl 0 "RRSideLghtCtrl_0_Off" 1 "RRSideLghtCtrl_1_On";
VAL_ 638 RLSideLghtCtrl 0 "RLSideLghtCtrl_0_Off" 1 "RLSideLghtCtrl_1_On";
VAL_ 638 VehSideLghtSts 0 "VehSideLghtSts_0_No_Side_Light_On" 1 "VehSideLghtSts_1_Left_Side_Light_On_Only" 2 "VehSideLghtSts_2_Right_Side_Light_On_Only" 3 "VehSideLghtSts_3_All_Side_Light_And_License_Plate_Light_On";
VAL_ 638 DircnLghtSwReq 0 "DircnLghtSwReq_0_Off" 1 "DircnLghtSwReq_1_Left_First_gear_direction_light_on" 2 "DircnLghtSwReq_2_Left_Second_gear_direction_light_on" 3 "DircnLghtSwReq_3_Right_First_gear_direction_light_on" 4 "DircnLghtSwReq_4_Right_Second_gear_direction_light_on";
VAL_ 638 DircnLghtFltsts 0 "DircnLghtFltsts_0_No_Error" 1 "DircnLghtFltsts_1_Left_Direction_Light_Error" 2 "DircnLghtFltsts_2_Right_Direction_Light_Error" 3 "DircnLghtFltsts_3_Both_Side_Direction_Light_Error";
VAL_ 638 HUDLkngAmbtLghtLvlByLux 16382 "HUDLkngAmbtLghtLvlByLux_16382_Invalid";
VAL_ 745 AutoMainBeamLghtOn 0 "AutoMainBeamLghtOn_0_False" 1 "AutoMainBeamLghtOn_1_True";
VAL_ 745 MainBeamLghtOn 0 "MainBeamLghtOnReq_0_Off" 1 "MainBeamLghtOnReq_1_On";
VAL_ 745 LRevsLghtSts 0 "LRevsLghtSts_0_off" 1 "LRevsLghtSts_1_on";
VAL_ 745 LBrkLghtSts 0 "LBrkLghtSts_0_Off" 1 "LBrkLghtSts_1_On";
VAL_ 745 ROtsdMirVertSwActReq 0 "ROtsdMirVertSwActReq_0_NoRequest" 1 "ROtsdMirVertSwActReq_1_Up_Request" 2 "ROtsdMirVertSwActReq_2_Down_Request" 3 "ROtsdMirVertSwActReq_3_Reserved";
VAL_ 745 ROtsdMirHoztSwActReq 0 "ROtsdMirHoztSwActReq_0_NoRequest" 1 "ROtsdMirHoztSwActReq_1_Left_Request" 2 "ROtsdMirHoztSwActReq_2_Right_Request" 3 "ROtsdMirHoztSwActReq_3_Reserved";
VAL_ 745 RLDoorLckSts 0 "RLDoorLckSts_0_Locked" 1 "RLDoorLckSts_1_Unlock" 2 "RLDoorLckSts_2_Error";
VAL_ 745 ZoneRLSideLghtSts 0 "ZoneRLSideLghtSts_0_Off" 1 "ZoneRLSideLghtSts_1_On" 2 "ZoneRLSideLghtSts_2_Error" 3 "ZoneRLSideLghtSts_3_Unknow";
VAL_ 745 ZoneFLSideLghtSts 0 "ZoneFLSideLghtSts_0_Off" 1 "ZoneFLSideLghtSts_1_On" 2 "ZoneFLSideLghtSts_2_Error" 3 "ZoneFLSideLghtSts_3_Unknow";
VAL_ 745 AllWndAndSrfLazyClsReq 0 "AllWndAndSrfLazyClsReq_l_0_False" 1 "AllWndAndSrfLazyClsReq_l_1_True";
VAL_ 745 RrSrvcPosReq 0 "RrSrvcPosReq_0_No_Request" 1 "RrSrvcPosReq_1_Service_position";
VAL_ 745 RrWiperFnEnb 0 "RrWiperFnEnb_0_Disable" 1 "RrWiperFnEnb_1_Enable";
VAL_ 745 DDSPSelRSwReq 0 "DDSPSelRSwReq_0_Idle" 1 "DDSPSelRSwReq_1_Press" 2 "DDSPSelRSwReq_2_Reserved" 3 "DDSPSelRSwReq_3_Error";
VAL_ 745 DDSPSelLSwReq 0 "DDSPSelLSwReq_0_Idle" 1 "DDSPSelLSwReq_1_Press" 2 "DDSPSelLSwReq_2_Reserved" 3 "DDSPSelLSwReq_3_Error";
VAL_ 745 TrdtnSmrtKyLckSwSts 0 "TrdtnSmrtKyLckSwSts_0_no_press" 1 "TrdtnSmrtKyLckSwSts_1_short_press" 2 "TrdtnSmrtKyLckSwSts_2_long_press" 3 "TrdtnSmrtKyLckSwSts_3_reserved";
VAL_ 745 TrdtnSmrtKyUnlckSwSts 0 "TrdtnSmrtKyUnlckSwSts_0_no_press" 1 "TrdtnSmrtKyUnlckSwSts_1_short_press" 2 "TrdtnSmrtKyUnlckSwSts_2_long_press" 3 "TrdtnSmrtKyUnlckSwSts_3_reserved";
VAL_ 745 RLSuperLckSts 0 "RLSuperLckSts_0_Lock" 1 "RLSuperLckSts_1_Unlock" 2 "RLSuperLckSts_2_Error";
VAL_ 745 FLSuperLckSts 0 "FLSuperLckSts_0_Lock" 1 "FLSuperLckSts_1_Unlock" 2 "FLSuperLckSts_2_Error";
VAL_ 745 DDSPSelDwnSwReq 0 "DDSPSelDwnSwReq_0_Idle" 1 "DDSPSelDwnSwReq_1_Press" 2 "DDSPSelDwnSwReq_2_Reserved" 3 "DDSPSelDwnSwReq_3_Error";
VAL_ 745 DDSPSelUpSwReq 0 "DDSPSelUpSwReq_0_Idle" 1 "DDSPSelUpSwReq_1_Press" 2 "DDSPSelUpSwReq_2_Reserved" 3 "DDSPSelUpSwReq_3_Error";
VAL_ 745 DDSPROtsdMirSeldSwA 0 "DDSPROtsdMirSeldSwA_0_False" 1 "DDSPROtsdMirSeldSwA_1_True" 2 "DDSPROtsdMirSeldSwA_2_Reserved" 3 "DDSPROtsdMirSeldSwA_3_Error";
VAL_ 745 DDSPLOtsdMirSeldSwA 0 "DDSPLOtsdMirSeldSwA_0_False" 1 "DDSPLOtsdMirSeldSwA_1_True" 2 "DDSPLOtsdMirSeldSwA_2_Reserved" 3 "DDSPLOtsdMirSeldSwA_3_Error";
VAL_ 745 DDSPOtsdMirFoldSwReq 0 "DDSPOtsdMirFoldSwReq_0_No_Request" 1 "DDSPOtsdMirFoldSwReq_1_Outside_Mirror_Fold_Unfold" 2 "DDSPOtsdMirFoldSwReq_2_Reserved" 3 "DDSPOtsdMirFoldSwReq_3_Error";
VAL_ 640 TrdtnKeyBtnSts 0 "TrdtnKeyBtnSts_0_no_press" 1 "TrdtnKeyBtnSts_1_unlock_button_pressed" 2 "TrdtnKeyBtnSts_2_lock_button_pressed" 3 "TrdtnKeyBtnSts_3_Find_car_button_pressed" 4 "TrdtnKeyBtnSts_4_loadspace_button_pressed" 5 "TrdtnKeyBtnSts_5_RPA_button_pressed" 6 "TrdtnKeyBtnSts_6_reserve" 7 "TrdtnKeyBtnSts_7_reserve";
VAL_ 640 SmrtKey2LoctnResp 0 "SmrtKey2LoctnResp_0_no_smart_key_response" 1 "SmrtKey2LoctnResp_1_left_side_pe_area" 2 "SmrtKey2LoctnResp_2_right_side_pe_area" 3 "SmrtKey2LoctnResp_3_front_side_pe_area" 4 "SmrtKey2LoctnResp_4_rear_side_pe_area" 5 "SmrtKey2LoctnResp_5_interior_ps_area" 6 "SmrtKey2LoctnResp_6_immo_area" 7 "SmrtKey2LoctnResp_7_charge_flap_pe_area" 8 "SmrtKey2LoctnResp_8_loadspace_interior_area" 9 "SmrtKey2LoctnResp_9_power_hood_interior_area" 10 "SmrtKey2LoctnResp_10_approach_zone0" 11 "SmrtKey2LoctnResp_11_approach_zone1" 12 "SmrtKey2LoctnResp_12_approach_zone2" 13 "SmrtKey2LoctnResp_13_approach_zone3" 14 "SmrtKey2LoctnResp_14_reserve" 15 "SmrtKey2LoctnResp_15_reserve";
VAL_ 640 SmrtKey1LoctnResp 0 "SmrtKey1LoctnResp_0_no_smart_key_response" 1 "SmrtKey1LoctnResp_1_left_side_pe_area" 2 "SmrtKey1LoctnResp_2_right_side_pe_area" 3 "SmrtKey1LoctnResp_3_front_side_pe_area" 4 "SmrtKey1LoctnResp_4_rear_side_pe_area" 5 "SmrtKey1LoctnResp_5_interior_ps_area" 6 "SmrtKey1LoctnResp_6_immo_area" 7 "SmrtKey1LoctnResp_7_charge_flap_pe_area" 8 "SmrtKey1LoctnResp_8_loadspace_interior_area" 9 "SmrtKey1LoctnResp_9_power_hood_interior_area" 10 "SmrtKey1LoctnResp_10_approach_zone0" 11 "SmrtKey1LoctnResp_11_approach_zone1" 12 "SmrtKey1LoctnResp_12_approach_zone2" 13 "SmrtKey1LoctnResp_13_approach_zone3" 14 "SmrtKey1LoctnResp_14_reserve" 15 "SmrtKey1LoctnResp_15_reserve";
VAL_ 640 LHandAntFltSts 0 "LHandAntFltSts_0_no_fault" 1 "LHandAntFltSts_1_open_circuit" 2 "LHandAntFltSts_2_short_to_GND" 3 "LHandAntFltSts_3_short_to_VBAT" 4 "LHandAntFltSts_4_line_to_line_short" 5 "LHandAntFltSts_5_reserve" 6 "LHandAntFltSts_6_reserve" 7 "LHandAntFltSts_7_reserve" 8 "LHandAntFltSts_8_reserve" 9 "LHandAntFltSts_9_reserve" 10 "LHandAntFltSts_10_reserve" 11 "LHandAntFltSts_11_reserve" 12 "LHandAntFltSts_12_reserve" 13 "LHandAntFltSts_13_reserve" 14 "LHandAntFltSts_14_reserve" 15 "LHandAntFltSts_15_reserve";
VAL_ 640 SmrtKey3LoctnResp 0 "SmrtKey3LoctnResp_0_no_smart_key_response" 1 "SmrtKey3LoctnResp_1_left_side_pe_area" 2 "SmrtKey3LoctnResp_2_right_side_pe_area" 3 "SmrtKey3LoctnResp_3_front_side_pe_area" 4 "SmrtKey3LoctnResp_4_rear_side_pe_area" 5 "SmrtKey3LoctnResp_5_interior_ps_area" 6 "SmrtKey3LoctnResp_6_immo_area" 7 "SmrtKey3LoctnResp_7_charge_flap_pe_area" 8 "SmrtKey3LoctnResp_8_loadspace_interior_area" 9 "SmrtKey3LoctnResp_9_power_hood_interior_area" 10 "SmrtKey3LoctnResp_10_approach_zone0" 11 "SmrtKey3LoctnResp_11_approach_zone1" 12 "SmrtKey3LoctnResp_12_approach_zone2" 13 "SmrtKey3LoctnResp_13_approach_zone3" 14 "SmrtKey3LoctnResp_14_reserve" 15 "SmrtKey3LoctnResp_15_reserve";
VAL_ 640 FrtBmpAntFltSts 0 "FrtBmpAntFltSts_0_no_fault" 1 "FrtBmpAntFltSts_1_open_circuit" 2 "FrtBmpAntFltSts_2_short_to_GND" 3 "FrtBmpAntFltSts_3_short_to_VBAT" 4 "FrtBmpAntFltSts_4_line_to_line_short" 5 "FrtBmpAntFltSts_5_reserve" 6 "FrtBmpAntFltSts_6_reserve" 7 "FrtBmpAntFltSts_7_reserve" 8 "FrtBmpAntFltSts_8_reserve" 9 "FrtBmpAntFltSts_9_reserve" 10 "FrtBmpAntFltSts_10_reserve" 11 "FrtBmpAntFltSts_11_reserve" 12 "FrtBmpAntFltSts_12_reserve" 13 "FrtBmpAntFltSts_13_reserve" 14 "FrtBmpAntFltSts_14_reserve" 15 "FrtBmpAntFltSts_15_reserve";
VAL_ 640 RHandAntFltSts 0 "RHandAntFltSts_0_no_fault" 1 "RHandAntFltSts_1_open_circuit" 2 "RHandAntFltSts_2_short_to_GND" 3 "RHandAntFltSts_3_short_to_VBAT" 4 "RHandAntFltSts_4_line_to_line_short" 5 "RHandAntFltSts_5_reserve" 6 "RHandAntFltSts_6_reserve" 7 "RHandAntFltSts_7_reserve" 8 "RHandAntFltSts_8_reserve" 9 "RHandAntFltSts_9_reserve" 10 "RHandAntFltSts_10_reserve" 11 "RHandAntFltSts_11_reserve" 12 "RHandAntFltSts_12_reserve" 13 "RHandAntFltSts_13_reserve" 14 "RHandAntFltSts_14_reserve" 15 "RHandAntFltSts_15_reserve";
VAL_ 640 CabinFrtAntFltSts 0 "CabinFrtAntFltSts_0_no_fault" 1 "CabinFrtAntFltSts_1_open_circuit" 2 "CabinFrtAntFltSts_2_short_to_GND" 3 "CabinFrtAntFltSts_3_short_to_VBAT" 4 "CabinFrtAntFltSts_4_line_to_line_short" 5 "CabinFrtAntFltSts_5_reserve" 6 "CabinFrtAntFltSts_6_reserve" 7 "CabinFrtAntFltSts_7_reserve" 8 "CabinFrtAntFltSts_8_reserve" 9 "CabinFrtAntFltSts_9_reserve" 10 "CabinFrtAntFltSts_10_reserve" 11 "CabinFrtAntFltSts_11_reserve" 12 "CabinFrtAntFltSts_12_reserve" 13 "CabinFrtAntFltSts_13_reserve" 14 "CabinFrtAntFltSts_14_reserve" 15 "CabinFrtAntFltSts_15_reserve";
VAL_ 640 RrBmpAntFltSts 0 "RrBmpAntFltSts_0_no_fault" 1 "RrBmpAntFltSts_1_open_circuit" 2 "RrBmpAntFltSts_2_short_to_GND" 3 "RrBmpAntFltSts_3_short_to_VBAT" 4 "RrBmpAntFltSts_4_line_to_line_short" 5 "RrBmpAntFltSts_5_reserve" 6 "RrBmpAntFltSts_6_reserve" 7 "RrBmpAntFltSts_7_reserve" 8 "RrBmpAntFltSts_8_reserve" 9 "RrBmpAntFltSts_9_reserve" 10 "RrBmpAntFltSts_10_reserve" 11 "RrBmpAntFltSts_11_reserve" 12 "RrBmpAntFltSts_12_reserve" 13 "RrBmpAntFltSts_13_reserve" 14 "RrBmpAntFltSts_14_reserve" 15 "RrBmpAntFltSts_15_reserve";
VAL_ 640 CabinRrAntFltSts 0 "CabinRrAntFltSts_0_no_fault" 1 "CabinRrAntFltSts_1_open_circuit" 2 "CabinRrAntFltSts_2_short_to_GND" 3 "CabinRrAntFltSts_3_short_to_VBAT" 4 "CabinRrAntFltSts_4_line_to_line_short" 5 "CabinRrAntFltSts_5_reserve" 6 "CabinRrAntFltSts_6_reserve" 7 "CabinRrAntFltSts_7_reserve" 8 "CabinRrAntFltSts_8_reserve" 9 "CabinRrAntFltSts_9_reserve" 10 "CabinRrAntFltSts_10_reserve" 11 "CabinRrAntFltSts_11_reserve" 12 "CabinRrAntFltSts_12_reserve" 13 "CabinRrAntFltSts_13_reserve" 14 "CabinRrAntFltSts_14_reserve" 15 "CabinRrAntFltSts_15_reserve";
VAL_ 640 CabinImmoAntFltSts 0 "CabinImmoAntFltSts_0_no_fault" 1 "CabinImmoAntFltSts_1_open_circuit" 2 "CabinImmoAntFltSts_2_short_to_GND" 3 "CabinImmoAntFltSts_3_short_to_VBAT" 4 "CabinImmoAntFltSts_4_line_to_line_short" 5 "CabinImmoAntFltSts_5_reserve" 6 "CabinImmoAntFltSts_6_reserve" 7 "CabinImmoAntFltSts_7_reserve" 8 "CabinImmoAntFltSts_8_reserve" 9 "CabinImmoAntFltSts_9_reserve" 10 "CabinImmoAntFltSts_10_reserve" 11 "CabinImmoAntFltSts_11_reserve" 12 "CabinImmoAntFltSts_12_reserve" 13 "CabinImmoAntFltSts_13_reserve" 14 "CabinImmoAntFltSts_14_reserve" 15 "CabinImmoAntFltSts_15_reserve";
VAL_ 640 KickSnsrDetnSts 0 "KickSnsrDetnSts_0_NoDetected" 1 "KickSnsrDetnSts_1_Detected" 2 "KickSnsrDetnSts_2_Invalid" 3 "KickSnsrDetnSts_3_Reserved";
VAL_ 640 TrdtnSmrtKyLdspcSwSts 0 "TrdtnSmrtKyLdspcSwSts_0_no_press" 1 "TrdtnSmrtKyLdspcSwSts_1_short_press" 2 "TrdtnSmrtKyLdspcSwSts_2_long_press" 3 "TrdtnSmrtKyLdspcSwSts_3_reserved";
VAL_ 640 TrdtnSmrtKyFindCarSwSts 0 "TrdtnSmrtKyFindCarSwSts_0_no_press" 1 "TrdtnSmrtKyFindCarSwSts_1_short_press" 2 "TrdtnSmrtKyFindCarSwSts_2_long_press" 3 "TrdtnSmrtKyFindCarSwSts_3_reserved";
VAL_ 513 FLDircnLghtSts 0 "FLDircnLghtSts_0_Off" 1 "FLDircnLghtSts_1_On";
VAL_ 513 LMainBeamLghtSts 0 "LMainBeamLghtSts_0_Off" 1 "LMainBeamLghtSts_1_On";
VAL_ 513 LDipdBeamLghtSts 0 "LDipdBeamLghtSts_0_Off" 1 "LDipdBeamLghtSts_1_On" 2 "LDipdBeamLghtSts_2_Error" 3 "LDipdBeamLghtSts_3_Unknow";
VAL_ 513 ESCLAuthnReq 0 "ESCLAuthnReq_0_Don_t_trigger" 1 "ESCLAuthnReq_1_Drive_door_trigger" 2 "ESCLAuthnReq_2_SSB_trigger" 3 "ESCLAuthnReq_3_Reserved";
VAL_ 513 DipdBeamLghtOnReq 0 "DipdBeamLghtOnReq__0__OFF" 1 "DipdBeamLghtOnReq_1_AllDipdBeamOn" 2 "DipdBeamLghtOnReq_2_RightDipdBeamOn" 3 "DipdBeamLghtOnReq__3_LeftDipdBeamOn";
VAL_ 800 FLDSP_RrWinInhbSwtSts 0 "FLDSP_RrWinInhbSwtSts_0_no_press" 1 "FLDSP_RrWinInhbSwtSts_1_press";
VAL_ 800 FLDSP_RrWinInhbSwtFlt 0 "FLDSP_RrWinInhbSwtFlt_0_no_error" 1 "FLDSP_RrWinInhbSwtFlt_1_error";
VAL_ 800 BCMOdoReq 0 "BCMOdoReq_0_NoRequest" 1 "BCMOdoReq_1_Request";
VAL_ 800 DircnIndLampSwStsMntry_CPD 0 "DircnIndLampSwStsMntry_0_off" 1 "DircnIndLampSwStsMntry_1_LeftshortturnmodeSwitchactive" 2 "DircnIndLampSwStsMntry_2_LeftlongturnmodeSwitchactive" 3 "DircnIndLampSwStsMntry_3_RightShortTurnModeSwitchActive" 4 "DircnIndLampSwStsMntry_4_RightLongTurnModeSwitchActive" 5 "DircnIndLampSwStsMntry_5_UnknowPosition" 6 "DircnIndLampSwStsMntry_6_reserve" 7 "DircnIndLampSwStsMntry_7_reserve";
VAL_ 800 ImmoSubModTCAuthnRunSts 0 "ImmoSubModTCAuthnRunSts__0_NotStartImmo" 1 "ImmoSubModTCAuthnRunSts__1_ImmoRunning" 2 "ImmoSubModTCAuthnRunSts__2_ImmoResponseSucess" 3 "ImmoSubModTCAuthnRunSts__3_ImmoAttack" 4 "ImmoSubModTCAuthnRunSts__4_ImmoNoChallenge" 5 "ImmoSubModTCAuthnRunSts__5_ImmoErrorChallenge" 6 "ImmoSubModTCAuthnRunSts__6_ImmoNoCipher" 7 "ImmoSubModTCAuthnRunSts_7_NoKey";
VAL_ 800 ImmoSubModSACAuthnRunSts 0 "ImmoSubModSACAuthnRunSts_0_NotStartImmo" 1 "ImmoSubModSACAuthnRunSts_1_ImmoRunning" 2 "ImmoSubModSACAuthnRunSts_2_ImmoResponseSucess" 3 "ImmoSubModSACAuthnRunSts_3_ImmoAttack" 4 "ImmoSubModSACAuthnRunSts_4_ImmoNoChallenge" 5 "ImmoSubModSACAuthnRunSts_5_ImmoErrorChallenge" 6 "ImmoSubModSACAuthnRunSts_6_ImmoNoCipher" 7 "ImmoSubModSACAuthnRunSts_7_ImmoNoSmtKey";
VAL_ 800 EDRDircnIndLampSwSts 0 "EDRDircnIndLampSwSts_0_off" 1 "EDRDircnIndLampSwSts_1_Left" 2 "EDRDircnIndLampSwSts_2_right" 3 "EDRDircnIndLampSwSts_3_hazard";
VAL_ 800 TemSnsrHdwrFltPrst 0 "TemSnsrHdwrFltPrst_0_False" 1 "TemSnsrHdwrFltPrst_1_True";
VAL_ 905 SmtKeyAuthnMnModRunSts 0 "SmtKeyAuthnMnModRunSts_0_Initialization" 1 "SmtKeyAuthnMnModRunSts_1_Running" 2 "SmtKeyAuthnMnModRunSts_2_Pass" 3 "SmtKeyAuthnMnModRunSts_3_Failure_Attack" 4 "SmtKeyAuthnMnModRunSts_4_Failure_NoResponse" 5 "SmtKeyAuthnMnModRunSts_5_Failure_NoCipher" 6 "SmtKeyAuthnMnModRunSts_6_HSM_Error" 7 "SmtKeyAuthnMnModRunSts_7_Reserved";
VAL_ 905 HtdFrtLftVwWndActSts 0 "HtdFrtLftVwWndActSts_0_Off" 1 "HtdFrtLftVwWndActSts_1_On";
VAL_ 905 LOtsdMirActSts 0 "LOtsdMirActSts_0_No_Action" 1 "LOtsdMirActSts_1_Tilt_X" 2 "LOtsdMirActSts_2_Tilt_Y" 3 "LOtsdMirActSts_3_Fold_Unfold" 4 "LOtsdMirActSts_4_Recall";
VAL_ 905 FrtWindShldSurndHmdty 254 "FrtWindShldSurndHmdty_254_No_such_feature" 255 "FrtWindShldSurndHmdty_255_Error";
VAL_ 905 FrtWindShldSurndTem 254 "FrtWindShldSurndTem_254_No_such_feature" 255 "FrtWindShldSurndTem_255_Error";
VAL_ 905 FrtWindShldSfcTem 2046 "FrtWindShldSfcTem_2046_No_such_feature" 2047 "FrtWindShldSfcTem_2047_Error";
VAL_ 905 SolarStrngLSideV 0 "SolarStrngLSideV_0_Valid" 1 "SolarStrngLSideV_1_Invalid";
VAL_ 905 SolarStrngRSideV 0 "SolarStrngRSideV_0_Valid" 1 "SolarStrngRSideV_1_Invalid";
VAL_ 905 DKBLERst 0 "DKBLERst_0_No_Request" 1 "DKBLERst_1_Request";
VAL_ 905 FrtWiperSpd 0 "FrtWiperSpd_0_No_Request" 1 "FrtWiperSpd_1_Low_Speed_Wipe" 2 "FrtWiperSpd_2_High_Speed_Wipe";
VAL_ 783 WlcmReq 0 "WlcmReq_0_NoRuqest" 1 "WlcmReq_1_DayRuquest" 2 "WlcmReq_2_NigtRequest" 3 "WlcmReq_3_Reserve";
VAL_ 783 FllwMeReq 0 "FllwMeReq_0_NoRuqest" 1 "FllwMeReq_1_DayRuquest" 2 "FllwMeReq_2_NigtRequest" 3 "FllwMeReq_3_Reserve";
VAL_ 783 FrwlLghtReq_LHZCU 0 "FrwlLghtReq_LHZCU_0_false" 1 "FrwlLghtReq_LHZCU_1_true";
VAL_ 783 FLSeatZeroSt 0 "FLSeatZeroSt_0_Not_Learned" 1 "FLSeatZeroSt_1_Learning" 2 "FLSeatZeroSt_2_Learned";
VAL_ 783 WlcmLghtReq_LHZCU 0 "WlcmLghtReq_LHZCU_0_false" 1 "WlcmLghtReq_LHZCU_1_true";
VAL_ 783 FLDoorOpenSts 0 "FLDoorOpenSts_0_Closed" 1 "FLDoorOpenSts_1_CantDetectDoorAjarStatus" 2 "FLDoorOpenSts_2_Ajar" 3 "FLDoorOpenSts_3_Open";
VAL_ 783 HUDLghtSnsrHdwrFltPrst 0 "HUDLghtSnsrHdwrFltPrst_l_0_False" 1 "HUDLghtSnsrHdwrFltPrst_l_1_True";
VAL_ 783 FLSeatRclnMotActn 0 "FLSeatRclnMotActn_0_NotMove" 1 "FLSeatRclnMotActn_1_ForwardMoving" 2 "FLSeatRclnMotActn_2_BackwordMoving" 3 "FLSeatRclnMotActn_3_NotAvailable";
VAL_ 783 FLSeatVertMotActn 0 "FLSeatVertMotActn_0_Not_Move" 1 "FLSeatVertMotActn_1_Upward_Moving" 2 "FLSeatVertMotActn_2_Downward_Moving" 3 "FLSeatVertMotActn_3_Not_available";
VAL_ 783 FLSeatHoztMotActn 0 "FLSeatHoztMotActn_0_NotMove" 1 "FLSeatHoztMotActn_1_ForwardMoving" 2 "FLSeatHoztMotActn_2_BackwordMoving" 3 "FLSeatHoztMotActn_3_NotAvailable";
VAL_ 783 HUDFwdLkngAmbtLghtLvl 16383 "HUDFwdLkngAmbtLghtLvl_16383_Invalid";
VAL_ 783 FollowMeHomeReq_LHZCU 0 "FollowMeHomeReq_LHZCU_0_false" 1 "FollowMeHomeReq_LHZCU_1_true";
VAL_ 783 BklghtReq 0 "BklghtReq_0_false" 1 "BklghtReq_1_true";
VAL_ 783 HUDRLSAmbtLghtLvl 4095 "HUDRLSAmbtLghtLvl_4095_Invalid";
VAL_ 783 HmdtySnsrHdwrFltPrst 0 "HmdtySnsrHdwrFltPrst_0_FALSE" 1 "HmdtySnsrHdwrFltPrst_1_TRUE";
VAL_ 783 FrtPsngDoorOpenSts_LHZCU 0 "FrtPsngDoorOpenSts_LHZCU_0_Closed" 1 "FrtPsngDoorOpenSts_LHZCU_1_CantDetectDoorAjarStatus" 2 "FrtPsngDoorOpenSts_LHZCU_2_Ajar" 3 "FrtPsngDoorOpenSts_LHZCU_3_Open";
VAL_ 896 LowBttySta 0 "LowBttySta_0_False" 1 "LowBttySta_1_True";
VAL_ 896 PutSmrtKeyToBkupPosRmnr 0 "PutSmrtKeyToBkupPosRmnr_0_False" 1 "PutSmrtKeyToBkupPosRmnr_1_True";
VAL_ 896 TakeKeyOutRmndr 0 "TakeKeyOutRmndr_0_False" 1 "TakeKeyOutRmndr_1_True";
VAL_ 896 CustrDblCnfmGearShftReq 0 "CustrDblCnfmGearShftReq_0_No_active" 1 "CustrDblCnfmGearShftReq_1_Active";
VAL_ 896 FrtWiperSwSts 0 "FrtWiperSwSts_0_WipersOff" 1 "FrtWiperSwSts_1_WipersInIntermittentMode" 2 "FrtWiperSwSts_2_WipersInSlowMode" 3 "FrtWiperSwSts_3_WipersInFastMode";
VAL_ 896 FrtWshrPumpA 0 "FrtWshrPumpA_0_False" 1 "FrtWshrPumpA_1_True";
VAL_ 896 FrtWiperOpReq 0 "FrtWiperOpReq_l_0_wiper_off" 1 "FrtWiperOpReq_l_1_slow_speed_wipe_single" 2 "FrtWiperOpReq_l_2_slow_speed_wipe_continuous" 3 "FrtWiperOpReq_l_3_fast_speed_wipe" 4 "FrtWiperOpReq_l_4_fault_mode";
VAL_ 157 SCUFltLvlWarn 0 "SCUFltLvlWarn_0_No_Fault" 1 "SCUFltLvlWarn_1_SCU_Limited_Fault" 2 "SCUFltLvlWarn_2_SCU_Critical_Fault" 3 "SCUFltLvlWarn_3_Transmission_Wrong_Gear_feedback";
VAL_ 157 SCUDrvMd 0 "SCUDrvMd_0_Normal" 1 "SCUDrvMd_1_TT_Push_mode" 2 "SCUDrvMd_2_Reserved" 3 "SCUDrvMd_3_Reserved";
VAL_ 157 SCUExtdShiftrFlr 0 "SCUExtdShiftrFlr_0_No_fail" 1 "SCUExtdShiftrFlr_1_Mode_selector_sensor_fail" 2 "SCUExtdShiftrFlr_2_Single_rotary_hall_sensor_fail" 3 "SCUExtdShiftrFlr_3_CAN_Bus_communication_fail" 4 "SCUExtdShiftrFlr_4_Single_P_button_sensor_fail" 5 "SCUExtdShiftrFlr_5_All_rotary_hall_sensor_fail" 6 "SCUExtdShiftrFlr_6_All_P_button_sensor_fail" 7 "SCUExtdShiftrFlr_7_SSU_fail" 8 "SCUExtdShiftrFlr_8_Single_Unlock_button_fail" 9 "SCUExtdShiftrFlr_9_All_unlock_button_fail" 10 "SCUExtdShiftrFlr_10_Single_SENT_sensor_fail" 11 "SCUExtdShiftrFlr_11_All_SENT_sensor_fail" 12 "SCUExtdShiftrFlr_12_Motor_Stuck" 13 "SCUExtdShiftrFlr_13_Motor_fail";
VAL_ 157 SCUShiftrOpngRmndr 0 "SCUShiftrOpngRmndr_0_No_Reminder_Request" 1 "SCUShiftrOpngRmndr_1_Please_Press_The_Unlock_Button" 2 "SCUShiftrOpngRmndr_2_Please_Slam_On_The_Brake_Pedal" 3 "SCUShiftrOpngRmndr_3_Please_Press_The_Unlock_Button_And_Slam_On_The_Brake_Pedal" 4 "SCUShiftrOpngRmndr_4_Speed_Too_High_Go_Into_P_not_allowed" 5 "SCUShiftrOpngRmndr_5_Speed_Too_High_Go_Into_R_not_allowed" 6 "SCUShiftrOpngRmndr_6_Changer_On_Inhibit_Shift_Out_P" 7 "SCUShiftrOpngRmndr_7_Shift_The_Lever_To_Left_Postion" 8 "SCUShiftrOpngRmndr_8_EPTRdy_Failed_Inhibit_Shift_to_D_R" 9 "SCUShiftrOpngRmndr_9_Camp_Mode_Active_Inhibit_Shift_Out_P" 10 "SCUShiftrOpngRmndr_10_Exhibition_Active_Inhibit_Shift_Out_P" 11 "SCUShiftrOpngRmndr_11_Game_Mode_Active_Inhibit_Shift_Out_P";
VAL_ 157 KeyAuthResp 0 "KeyAuthResp_0_PSNonValidKey" 1 "KeyAuthResp_1_PSValidKey";
VAL_ 157 SCUParkLckReq 0 "SCUParkLckReq_0_No_Request" 1 "SCUParkLckReq_1_Release_Brake_Request" 2 "SCUParkLckReq_2_Apply_Brake_Request" 3 "SCUParkLckReq_3_Reserved";
VAL_ 157 SCUParkLckReqV 0 "SCUParkLckReqV_0_Valid" 1 "SCUParkLckReqV_1_Invalid";
VAL_ 157 DigKeyAuthReq 0 "DigKeyAuthReq_0_NoRequest" 1 "DigKeyAuthReq_1_Request";
VAL_ 157 SCUShiftrLvrRawPosn 0 "SCUShiftrLvrRawPosn_0_Up2" 1 "SCUShiftrLvrRawPosn_1_Up1" 2 "SCUShiftrLvrRawPosn_2_Stable" 3 "SCUShiftrLvrRawPosn_3_Down1" 4 "SCUShiftrLvrRawPosn_4_Down2" 5 "SCUShiftrLvrRawPosn_5_Ptouch" 6 "SCUShiftrLvrRawPosn_6_Error";
VAL_ 157 SCUParkLckReqVEPMCU 0 "SCUParkLckReqVEPMCU_0_Valid" 1 "SCUParkLckReqVEPMCU_1_Invalid";
VAL_ 157 SCUParkLckReqEPMCU 0 "SCUParkLckReqEPMCU_0_No_Request" 1 "SCUParkLckReqEPMCU_1_Release_Brake_Request" 2 "SCUParkLckReqEPMCU_2_Apply_Brake_Request" 3 "SCUParkLckReqEPMCU_3_Reserved";
VAL_ 157 SCUShiftrPosnInvsn 5 "SCUShiftrPosnInvsn_5_Error" 6 "SCUShiftrPosnInvsn_6_In_learn_process" 7 "SCUShiftrPosnInvsn_7_P_Park" 8 "SCUShiftrPosnInvsn_8_R_Reverse" 9 "SCUShiftrPosnInvsn_9_N_Neutral" 10 "SCUShiftrPosnInvsn_10_D_Drive" 12 "SCUShiftrPosnInvsn_12_M_Manual_mode" 13 "SCUShiftrPosnInvsn_13_W_Winter_mode" 14 "SCUShiftrPosnInvsn_14_S_Sport_mode" 15 "SCUShiftrPosnInvsn_15_SCU_initialization";
VAL_ 157 SCUShiftrLvrPosn 0 "SCUShiftrLvrPosn_0_SCU_Initialization" 1 "SCUShiftrLvrPosn_1_S_Sport_Mode" 2 "SCUShiftrLvrPosn_2_W_Winter_Mode" 3 "SCUShiftrLvrPosn_3_M_Manual_Mode" 5 "SCUShiftrLvrPosn_5_D_Drive" 6 "SCUShiftrLvrPosn_6_N_Neutral" 7 "SCUShiftrLvrPosn_7_R_Reverse" 8 "SCUShiftrLvrPosn_8_P_Park" 9 "SCUShiftrLvrPosn_9_In_learn_Process" 10 "SCUShiftrLvrPosn_10_Error";
VAL_ 157 DrvrReqParkBtn 0 "DrvrReqParkBtn_0_no_request" 1 "DrvrReqParkBtn_1_driver_request_park_button" 2 "DrvrReqParkBtn_2_Park_button_fault" 3 "DrvrReqParkBtn_3_reserved";
VAL_ 157 SCUShiftrLvrPosnLtchActv 0 "SCUShiftrLvrPosnLtchActv_0_Inactive" 1 "SCUShiftrLvrPosnLtchActv_1_Active";
VAL_ 157 SecuKeyVldSts 0 "SecuKeyVldSts_0_Valid" 1 "SecuKeyVldSts_1_Invalid";
VAL_ 157 SCUDrvrIntrvnActv 0 "SCUDrvrIntrvnActv_0_Inactive" 1 "SCUDrvrIntrvnActv_1_Active";
VAL_ 157 SCUAPAUnderCtrlActv 0 "SCUAPAUnderCtrlActv_0_Inhibit" 1 "SCUAPAUnderCtrlActv_1_Available_For_Control" 2 "SCUAPAUnderCtrlActv_2_Active_For_Control" 3 "SCUAPAUnderCtrlActv_3_Failed";
VAL_ 299 DippedBeamActStatus 0 "DippedBeamActStatus_0_OFF" 1 "DippedBeamActStatus_1_ON";
VAL_ 299 RevsLghtCtrl 0 "RevsLghtCtrl_0_Off" 1 "RevsLghtCtrl_1_On";
VAL_ 299 PriySSBA 0 "PriySSBA_0_False" 1 "PriySSBA_1_True";
VAL_ 299 PriySSBAV 0 "PriySSBAV_0_Valid" 1 "PriySSBAV_1_Invalid";
VAL_ 299 SecySSBA 0 "SecySSBA_0_False" 1 "SecySSBA_1_True";
VAL_ 299 SecySSBAV 0 "SecySSBAV_0_Valid" 1 "SecySSBAV_1_Invalid";
VAL_ 299 SSBTrigd 0 "SSBTrigd_0_False" 1 "SSBTrigd_1_True";
VAL_ 299 RMainBeamLghtCtrl 0 "RMainBeamLghtCtrl_0_Off" 1 "RMainBeamLghtCtrl_1_On";
VAL_ 299 LMainBeamLghtCtrl 0 "LMainBeamLghtCtrl_0_Off" 1 "LMainBeamLghtCtrl_1_On";
VAL_ 299 RRDircnLghtCtrl 0 "RRDircnLghtCtrl_0_Off" 1 "RRDircnLghtCtrl_1_on";
VAL_ 299 RLDircnLghtCtrl 0 "RLDircnLghtCtrl_0_Off" 1 "RLDircnLghtCtrl_1_on";
VAL_ 299 FRDircnLghtCtrl 0 "FRDircnLghtCtrl_0_Off" 1 "FRDircnLghtCtrl_1_on";
VAL_ 299 FLDircnLghtCtrl 0 "FLDircnLghtCtrl_0_Off" 1 "FLDircnLghtCtrl_1_on";
VAL_ 299 BrkLghtCtrl 0 "BrkLghtCtrl_0_Off" 1 "BrkLghtCtrl_1_On";
VAL_ 299 HzrdLghtSwReq 0 "HzrdLghtSwReq_0_Off" 1 "HzrdLghtSwReq_1_On";
SIG_GROUP_ 995 ILHZCU_100ms_Group30 1 : DircnIndLampSwStsMntry FLSeatHorzPos FLSeatVertPos LHZCU_100ms_Group30_CRC LHZCU_100ms_Group30_RC LHZCU_100ms_Group30_Reserved103 LHZCU_100ms_Group30_Reserved111 LHZCU_100ms_Group30_Reserved119 LHZCU_100ms_Group30_Reserved12 LHZCU_100ms_Group30_Reserved127 LHZCU_100ms_Group30_Reserved23 LHZCU_100ms_Group30_Reserved31 LHZCU_100ms_Group30_Reserved55 LHZCU_100ms_Group30_Reserved63 LHZCU_100ms_Group30_Reserved71 LHZCU_100ms_Group30_Reserved79 LHZCU_100ms_Group30_Reserved87 LHZCU_100ms_Group30_Reserved95;
SIG_GROUP_ 181 ILHZCU_10ms_Group32 1 : BrkLghtSwReq DircnLghtOnReq_LHZCU DrvrReqGearShftPos DrvrReqGearShftPosInvs EleccTrRngReq LDayTimeRunningLghtCtrl LHZCUWKSTS LHZCU_10ms_Group32_CRC LHZCU_10ms_Group32_RC LHZCU_10ms_Group32_Reserved1 LHZCU_10ms_Group32_Reserved2 LHZCU_10ms_Group32_Reserved3 LHZCU_10ms_Group32_Reserved4 LHZCU_10ms_Group32_Reserved5 LHZCU_10ms_Group32_Reserved6 LHZCU_10ms_Group32_Reserved7 MainBeamLghtSwReq RDayTimeRunningLghtCtrl RrFogLightOnReq SCUActrMvmntSts SCUDrvnIntrvnPos SCUExtdShifterActrPos SCUParkActrSts SCUShftLvrPosIncnstntFlag SCUShftLvrPosTrgt SCUTapUpDwnSwSta SCUTapUpDwnSwStaInvsn SideLghtOnReq SmrtKey4LoctnResp SmrtKeyLoctnFlrRsn SmrtKeyLoctnProc;
SIG_GROUP_ 638 ILHZCU_50ms_Group24 1 : BrkLghtFltSta BrkLghtSta DircnLghtFltsts DircnLghtMdSts DircnLghtSts DircnLghtSwReq HUDLkngAmbtLghtLvlByLux LHZCU_50ms_Group24_CRC LHZCU_50ms_Group24_RC LHZCU_50ms_Group24_Reserved103 LHZCU_50ms_Group24_Reserved111 LHZCU_50ms_Group24_Reserved121 LHZCU_50ms_Group24_Reserved135 LHZCU_50ms_Group24_Reserved143 LHZCU_50ms_Group24_Reserved151 LHZCU_50ms_Group24_Reserved159 LHZCU_50ms_Group24_Reserved23 LHZCU_50ms_Group24_Reserved31 LHZCU_50ms_Group24_Reserved39 LHZCU_50ms_Group24_Reserved47 LHZCU_50ms_Group24_Reserved49 LHZCU_50ms_Group24_Reserved55 LHZCU_50ms_Group24_Reserved60 LHZCU_50ms_Group24_Reserved71 LHZCU_50ms_Group24_Reserved79 LHZCU_50ms_Group24_Reserved81 LHZCU_50ms_Group24_Reserved87 LHZCU_50ms_Group24_Reserved95 RLSideLghtCtrl RRSideLghtCtrl VehHzrdMdSts VehIlluminateCtrlCmd VehSideLghtSts;
SIG_GROUP_ 157 ILHZCU_10ms_Group01 1 : DigKeyAuthReq DigKeyPEValidReq DrvrReqParkBtn KeyAuthResp LHZCU_10ms_Group01_CRC LHZCU_10ms_Group01_RC LHZCU_10ms_Group01_Reserved1 LHZCU_10ms_Group01_Reserved2 SCUAPAUnderCtrlActv SCUDrvMd SCUDrvrIntrvnActv SCUExtdShiftrFlr SCUFltLvlWarn SCUParkLckReq SCUParkLckReqEPMCU SCUParkLckReqV SCUParkLckReqVEPMCU SCUShiftrLvrPosn SCUShiftrLvrPosnLtchActv SCUShiftrLvrRawPosn SCUShiftrOpngRmndr SCUShiftrPosnInvsn SecuKeyVldSts;
SIG_GROUP_ 299 ILHZCU_20ms_Group03 1 : BrkLghtCtrl DippedBeamActStatus FLDircnLghtCtrl FRDircnLghtCtrl HzrdLghtSwReq LHZCU_20ms_Group03_CRC LHZCU_20ms_Group03_RC LHZCU_20ms_Group03_Reserved1 LHZCU_20ms_Group03_Reserved2 LHZCU_20ms_Group03_Reserved3 LHZCU_20ms_Group03_Reserved4 LHZCU_20ms_Group03_Reserved5 LHZCU_20ms_Group03_Reserved6 LMainBeamLghtCtrl PriySSBA PriySSBAV RLDircnLghtCtrl RMainBeamLghtCtrl RRDircnLghtCtrl RevsLghtCtrl SSBTrigd SecySSBA SecySSBAV;
